[part 3 of 5: package /Cluster]
AUTOSAR XML (schema 4-3-0)
package /Cluster  (continued)
  can cluster HCP5_CANFD01: baudrate=500000, protocol-name=CAN, protocol-version=2.0, bus-off-recovery={bor-counter-l-1-to-l-2=1, bor-time-l-1=0.05, bor-time-l-2=0.2}, can-fd-baudrate=2000000  (continued)
    can physical channel CHNL: comm-connectors=CN_HCP5_CANFD01  (continued)
      frame NM_Gateway_XIX_HCP5_CANFD01: id 0x1B000010, to BMC_HV, frame-length=24, can-addressing-mode=EXTENDED, can-frame-rx-behavior=CAN-FD, can-frame-tx-behavior=CAN-FD, rx-identifier-range={lower-can-id=452984832, upper-can-id=452985855}
        nm pdu NM_Gateway_XIX_HCP5_CANFD01: length=24, unused-bit-pattern=0
          signal NM_Gateway_CBV_AWB_XIX_NM_Gateway_XIX_HCP5_CANFD01: start 4, 1 bit, little-endian, data-type-policy=OVERRIDE, i-signal-type=PRIMITIVE, init-value=0, base-type=BT_NM_Gateway_CBV_AWB, compu-method=CM_NM_Gateway_CBV_AWB, data-constr=DC_NM_Gateway_CBV_AWB, transfer-property=TRIGGERED  # Das Signal ist zu setzen, wenn das SG aktiv den Bus geweckt hat 0 = Passiver_WakeUp = SG hat das Netzwerk nicht aktiv geweckt 1 = Akitiver_WakeUp = SG hat das Netzwerk aktiv geweckt
          signal NM_Gateway_CBV_CRI_XIX_NM_Gateway_XIX_HCP5_CANFD01: start 6, 1 bit, little-endian, data-type-policy=OVERRIDE, i-signal-type=PRIMITIVE, init-value=1, base-type=BT_NM_Gateway_CBV_CRI, compu-method=CM_NM_Gateway_CBV_CRI, data-constr=DC_NM_Gateway_CBV_CRI, transfer-property=TRIGGERED  # Das Signal ist dauerhaft gesetzt, wenn das NM-Layout Cluster- Anforderungen enthält
          signal NM_Gateway_FCAB_XIX_NM_Gateway_XIX_HCP5_CANFD01: start 8, 56 bit, opaque, data-type-policy=OVERRIDE, i-signal-type=ARRAY, init-value=7 x 0b00000000, base-type=BT_NM_Gateway_FCAB, compu-method=CM_NM_Gateway_FCAB, data-constr=DC_NM_Gateway_FCAB, transfer-property=TRIGGERED-ON-CHANGE, to BMC_HV(timeout 2 s)  # FCAB = Funktions-Cluster-Aktiv-Bits
          signal NM_aktiv_ConnectVerbund_UseCase1_XIX_NM_Gateway_XIX_HCP5_CANFD01: start 114, 1 bit, little-endian, data-type-policy=OVERRIDE, i-signal-type=PRIMITIVE, init-value=0, base-type=BT_NM_aktiv_ConnectVerbund_UseCase1, compu-method=CM_NM_aktiv_ConnectVerbund_UseCase1, data-constr=DC_NM_aktiv_ConnectVerbund_UseCase1, transfer-property=TRIGGERED  # Die Connect Steuergeräte HCP3, HCP5 und ConMod sind über einen zusätzlichen Wecknachlauf, inkl. Bus Kommunikation und Backend Verbindung aufgeweckt. Der Kunde hat davor die Funktion "Verlängerte Wachphase An" in der HCP3 Goodbye Screen bestätigt. Die Funktion hat Dauer und Max Werte Analog VoKo oder Prädektives VoKo Funktionalität und darf nur aktiv bleiben solange VoKo an ist (NM_aktiv_Scheibenheizung). Um diese Funktionalität zu ermöglichen sind bestehenden Funktionscluster zu steuern
          signal NM_aktiv_ConnectVerbund_UseCase2_XIX_NM_Gateway_XIX_HCP5_CANFD01: start 115, 1 bit, little-endian, data-type-policy=OVERRIDE, i-signal-type=PRIMITIVE, init-value=0, base-type=BT_NM_aktiv_ConnectVerbund_UseCase2, compu-method=CM_NM_aktiv_ConnectVerbund_UseCase2, data-constr=DC_NM_aktiv_ConnectVerbund_UseCase2, transfer-property=TRIGGERED  # Die Connect Steuergeräte HCP3, HCP5 und ConMod bleiben über einen zusätzlichen Wecknachlauf wach, inkl. Bus Kommunikation und Backend Verbindung wenn der Kunde die Funktion "Verlängerte Wachphase An" in der HU Goodbye Screen die Funktion bestätigt. Um diese Funktionalität zu ermöglichen sind bestehenden Funktionscluster zu steuern Die HVEM soll zwischen 5-10 Minuten nachlaufen damit die Connect Verbund die NVEM Batterie optimal ausnutzt
          signal NM_aktiv_ConnectVerbund_UseCase3_XIX_NM_Gateway_XIX_HCP5_CANFD01: start 116, 1 bit, little-endian, data-type-policy=OVERRIDE, i-signal-type=PRIMITIVE, init-value=0, base-type=BT_NM_aktiv_ConnectVerbund_UseCase3, compu-method=CM_NM_aktiv_ConnectVerbund_UseCase3, data-constr=DC_NM_aktiv_ConnectVerbund_UseCase3, transfer-property=TRIGGERED  # Die ORU Steuergeräte sind länger wach inkl. Bus Kommunikation und Backend Verbindung wenn der Kunde die Funktion in der HU Goodbye Screen die Funktion "Verlängerte Wachphase An" bestätigt hat. Flash Umfänge bei denen den HV-System aus sein muss, darf nicht länger als 30 Minuten ORU Flashzeit. Andere Umfänge dürfen längere ORU Flashzeit (bis 180 Minuten) anfodern. NM_aktivgrund verfügbar NM_aktiv_OnlineRemoteUpdate
          signal NM_aktiv_ConnectVerbund_UseCase4_XIX_NM_Gateway_XIX_HCP5_CANFD01: start 117, 1 bit, little-endian, data-type-policy=OVERRIDE, i-signal-type=PRIMITIVE, init-value=0, base-type=BT_NM_aktiv_ConnectVerbund_UseCase4, compu-method=CM_NM_aktiv_ConnectVerbund_UseCase4, data-constr=DC_NM_aktiv_ConnectVerbund_UseCase4, transfer-property=TRIGGERED  # Die Connect Steuergeräte HCP3, HCP5, HCP4 und ConMod werden geweckt und bleiben wach, inkl. Bus Kommunikation und Backend Verbindung wenn der Kunde die Funktion "Verlängerte Wachphase An" in der Head Unit Goodbye Screen bestätigt hat während das Fahrzeug am DC Ladesäule geladen wird. Um diese Funktionalität zu ermöglichen sind bestehenden Funktionscluster zu steuern
          signal NM_aktiv_ConnectVerbund_UseCase5_XIX_NM_Gateway_XIX_HCP5_CANFD01: start 118, 1 bit, little-endian, data-type-policy=OVERRIDE, i-signal-type=PRIMITIVE, init-value=0, base-type=BT_NM_aktiv_ConnectVerbund_UseCase5, compu-method=CM_NM_aktiv_ConnectVerbund_UseCase5, data-constr=DC_NM_aktiv_ConnectVerbund_UseCase5, transfer-property=TRIGGERED  # Die Connect Steuergeräte HCP3, HCP5 und ConMod sind über einen zusätzlichen Wecknachlauf, inkl. Bus Kommunikation und Backend Verbindung aufgeweckt. Der Kunde hat davor die Funktion "Verlängerte Wachphase An" in der HCP3 Goodbye Screen bestätigt. Um diese Funktionalität zu ermöglichen sind bestehenden Funktionscluster zu steuern
          signal NM_aktiv_ConnectVerbund_UseCase6_XIX_NM_Gateway_XIX_HCP5_CANFD01: start 119, 1 bit, little-endian, data-type-policy=OVERRIDE, i-signal-type=PRIMITIVE, init-value=0, base-type=BT_NM_aktiv_ConnectVerbund_UseCase6, compu-method=CM_NM_aktiv_ConnectVerbund_UseCase6, data-constr=DC_NM_aktiv_ConnectVerbund_UseCase6, transfer-property=TRIGGERED  # Die Connect Steuergeräte HCP3, HCP5 und ConMod sind über einen zusätzlichen Wecknachlauf, inkl. Bus Kommunikation und Backend Verbindung aufgeweckt während das Fahrzeug am AC Ladesäule geladen wird. Trigger ist eine Anfrage über die App/Backend ins Auto. Der Kunde hat davor die Funktion "Verlängerte Wachphase An" in der HCP3 Goodbye Screen bestätigt. Um diese Funktionalität zu ermöglichen sind bestehenden Funktionscluster zu steuern
          signal NM_aktiv_AutomotiveEdge_1_XIX_NM_Gateway_XIX_HCP5_CANFD01: start 120, 1 bit, little-endian, data-type-policy=OVERRIDE, i-signal-type=PRIMITIVE, init-value=0, base-type=BT_NM_aktiv_AutomotiveEdge_1, compu-method=CM_NM_aktiv_AutomotiveEdge_1, data-constr=DC_NM_aktiv_AutomotiveEdge_1, transfer-property=TRIGGERED  # Vorhalt VNSM_UsrId und NM-Aktivgrund-Signal für künftig möglichen Funktionshub ohne erforderlichen K-Matrix Update
          signal NM_aktiv_AutomotiveEdge_2_XIX_NM_Gateway_XIX_HCP5_CANFD01: start 121, 1 bit, little-endian, data-type-policy=OVERRIDE, i-signal-type=PRIMITIVE, init-value=0, base-type=BT_NM_aktiv_AutomotiveEdge_2, compu-method=CM_NM_aktiv_AutomotiveEdge_2, data-constr=DC_NM_aktiv_AutomotiveEdge_2, transfer-property=TRIGGERED  # Vorhalt VNSM_UsrId und NM-Aktivgrund-Signal für künftig möglichen Funktionshub ohne erforderlichen K-Matrix Update
          signal NM_aktiv_AutomotiveEdge_3_XIX_NM_Gateway_XIX_HCP5_CANFD01: start 122, 1 bit, little-endian, data-type-policy=OVERRIDE, i-signal-type=PRIMITIVE, init-value=0, base-type=BT_NM_aktiv_AutomotiveEdge_3, compu-method=CM_NM_aktiv_AutomotiveEdge_3, data-constr=DC_NM_aktiv_AutomotiveEdge_3, transfer-property=TRIGGERED  # Vorhalt VNSM_UsrId und NM-Aktivgrund-Signal für künftig möglichen Funktionshub ohne erforderlichen K-Matrix Update
          signal NM_aktiv_AutomotiveEdge_4_XIX_NM_Gateway_XIX_HCP5_CANFD01: start 123, 1 bit, little-endian, data-type-policy=OVERRIDE, i-signal-type=PRIMITIVE, init-value=0, base-type=BT_NM_aktiv_AutomotiveEdge_4, compu-method=CM_NM_aktiv_AutomotiveEdge_4, data-constr=DC_NM_aktiv_AutomotiveEdge_4, transfer-property=TRIGGERED  # Vorhalt VNSM_UsrId und NM-Aktivgrund-Signal für künftig möglichen Funktionshub ohne erforderlichen K-Matrix Update
          signal NM_aktiv_AutomotiveEdge_5_XIX_NM_Gateway_XIX_HCP5_CANFD01: start 124, 1 bit, little-endian, data-type-policy=OVERRIDE, i-signal-type=PRIMITIVE, init-value=0, base-type=BT_NM_aktiv_AutomotiveEdge_5, compu-method=CM_NM_aktiv_AutomotiveEdge_5, data-constr=DC_NM_aktiv_AutomotiveEdge_5, transfer-property=TRIGGERED  # Vorhalt VNSM_UsrId und NM-Aktivgrund-Signal für künftig möglichen Funktionshub ohne erforderlichen K-Matrix Update
          signal NM_aktiv_MVEM_Fremdladung_XIX_NM_Gateway_XIX_HCP5_CANFD01: start 125, 1 bit, little-endian, data-type-policy=OVERRIDE, i-signal-type=PRIMITIVE, init-value=0, base-type=BT_NM_aktiv_MVEM_Fremdladung, compu-method=CM_NM_aktiv_MVEM_Fremdladung, data-constr=DC_NM_aktiv_MVEM_Fremdladung, transfer-property=TRIGGERED  # Nach Ausschalten der Kl.15 soll bei 12V-Fremdladungsfreigabe durch das NvEM das MV-Netz noch aktiv gehalten werden oder bei ausgeschalteter Kl.15 aktiviert werden, dazu muss der HCP5 wach sein, der DcDc-Wandler und das BMS mit den jeweiligen Bussen. - 12V-Fremdladung (Fremdladegerät an der 12V-Batterie), damit die 48V-Batterie über den DcDc-Wandler noch geladen werden kann => wachhalten/aufwecken
          signal NM_aktiv_Konditionierung_Track_XIX_NM_Gateway_XIX_HCP5_CANFD01: start 126, 1 bit, little-endian, data-type-policy=OVERRIDE, i-signal-type=PRIMITIVE, init-value=0, base-type=BT_NM_aktiv_Konditionierung_Track, compu-method=CM_NM_aktiv_Konditionierung_Track, data-constr=DC_NM_aktiv_Konditionierung_Track, transfer-property=TRIGGERED  # Ist die Teilfunktion "Vorkonditionierung" der Funktion Make Me Track Ready (MMTR) aktiv und das Fahrzeug wird dann abgestellt (HVEM_MMTR_State = 2 ||3 UND DANN KL15 Ein -> KL15 Aus), soll der Konditioniervorgang für eine applizierbare Maximalzeit weiter laufen und die betroffenen Steuergeräte wach gehalten werden. Der Kunde kann die Option mittels Display-Anzeige (HCP3) aktivieren. Anschließend wird der Konditionierungsstatus im Display angezeigt.
          signal NM_aktiv_Remote_Repair_XIX_NM_Gateway_XIX_HCP5_CANFD01: start 127, 1 bit, little-endian, data-type-policy=OVERRIDE, i-signal-type=PRIMITIVE, init-value=0, base-type=BT_NM_aktiv_Remote_Repair, compu-method=CM_NM_aktiv_Remote_Repair, data-constr=DC_NM_aktiv_Remote_Repair, transfer-property=TRIGGERED  # Wird aus den Aftersalessystemen (VW/Audi, Porsche) eine Remote Repair Verbindung zum Fahrzeug aufgebaut, so soll das HCP5 und zur Durchführung von Fehlerbehebungsmaßnahmen das gesamte Fahrzeug aufgeweckt bzw. Wachgehalten werden können. Die Verbindung aus den Aftersalessystemen soll hauptsächlich bei Liegenbleibern zur Anwendung kommen. Des Weiteren wenn die Fahrzeuge auf dem Werkstattgelände stehen, um ohne externen Tester DTCs auslesen zu können.
          signal NM_Gateway_SNI_10_XIX_NM_Gateway_XIX_HCP5_CANFD01: start 128, 10 bit, little-endian, data-type-policy=OVERRIDE, i-signal-type=PRIMITIVE, init-value=16, base-type=BT_NM_Gateway_SNI_10, compu-method=CM_NM_Gateway_SNI_10, data-constr=DC_NM_Gateway_SNI_10, transfer-property=TRIGGERED  # Source Node-Identifier (SNI) identifiziert den Sender der NM-Botschaft (Knotenadresse) eindeutig im Fahrzeug
          signal NM_Gateway_NM_State_XIX_NM_Gateway_XIX_HCP5_CANFD01: start 144, 6 bit, little-endian, data-type-policy=OVERRIDE, i-signal-type=PRIMITIVE, init-value=0, base-type=BT_NM_Gateway_NM_State, compu-method=CM_NM_Gateway_NM_State, data-constr=DC_NM_Gateway_NM_State, transfer-property=TRIGGERED  # 1 = Zustand Repeat Message (<-- Bus-Sleep Mode) 2 = Zustand Repeat Message (<-- Prepare Bus-Sleep Mode) 4 = Zustand Normal Operation (<-- Repeat Message) 8 = Zustand Normal Operation (<-- Ready Sleep)
          signal NM_Gateway_UDS_CC_XIX_NM_Gateway_XIX_HCP5_CANFD01: start 151, 1 bit, little-endian, data-type-policy=OVERRIDE, i-signal-type=PRIMITIVE, init-value=0, base-type=BT_NM_Gateway_UDS_CC, compu-method=CM_NM_Gateway_UDS_CC, data-constr=DC_NM_Gateway_UDS_CC, transfer-property=TRIGGERED  # Funktionseinschränkung aufgrund aktivem UDS-Communication Control, siehe VW80124
          signal NM_Gateway_Wakeup_V12_XIX_NM_Gateway_XIX_HCP5_CANFD01: start 152, 8 bit, little-endian, data-type-policy=OVERRIDE, i-signal-type=PRIMITIVE, init-value=0, base-type=BT_NM_Gateway_Wakeup_V12, compu-method=CM_NM_Gateway_Wakeup_V12, data-constr=DC_NM_Gateway_Wakeup_V12, transfer-property=TRIGGERED  # enthält die Weckursache; stehen mehrere Weckursachen parallel an, dann muss der kleinste Wert übertragen werden
          signal NM_Gateway_NM_aktiv_KL15_XIX_NM_Gateway_XIX_HCP5_CANFD01: start 160, 1 bit, little-endian, data-type-policy=OVERRIDE, i-signal-type=PRIMITIVE, init-value=0, base-type=BT_NM_Gateway_NM_aktiv_KL15, compu-method=CM_NM_Gateway_NM_aktiv_KL15, data-constr=DC_NM_Gateway_NM_aktiv_KL15, transfer-property=TRIGGERED  # Steuergerät hat KL15-EIN erkannt
          signal NM_Gateway_NM_aktiv_Diag_XIX_NM_Gateway_XIX_HCP5_CANFD01: start 161, 1 bit, little-endian, data-type-policy=OVERRIDE, i-signal-type=PRIMITIVE, init-value=0, base-type=BT_NM_Gateway_NM_aktiv_Diag, compu-method=CM_NM_Gateway_NM_aktiv_Diag, data-constr=DC_NM_Gateway_NM_aktiv_Diag, transfer-property=TRIGGERED  # Diagnose befindet sich nach VW80124 in einer NonDefaultDiagnostic-Session, z.B. ExtendedDiagnostic-Session
          signal NM_Gateway_NM_aktiv_Tmin_XIX_NM_Gateway_XIX_HCP5_CANFD01: start 162, 1 bit, little-endian, data-type-policy=OVERRIDE, i-signal-type=PRIMITIVE, init-value=0, base-type=BT_NM_Gateway_NM_aktiv_Tmin, compu-method=CM_NM_Gateway_NM_aktiv_Tmin, data-constr=DC_NM_Gateway_NM_aktiv_Tmin, transfer-property=TRIGGERED  # Mindestaktivzeit ist noch nicht abgelaufen (bei jedem Weckereignis wird die Mindestaktivzeit neu gestartet)
          signal NM_Gateway_NM_aktiv_CABaktiv_XIX_NM_Gateway_XIX_HCP5_CANFD01: start 163, 1 bit, little-endian, data-type-policy=OVERRIDE, i-signal-type=PRIMITIVE, init-value=0, base-type=BT_NM_Gateway_NM_aktiv_CABaktiv, compu-method=CM_NM_Gateway_NM_aktiv_CABaktiv, data-constr=DC_NM_Gateway_NM_aktiv_CABaktiv, transfer-property=TRIGGERED  # Nachlauf aufgrund Funktionscluster Anforderung
          signal NM_aktiv_Gefahreninfo_XIX_NM_Gateway_XIX_HCP5_CANFD01: start 164, 1 bit, little-endian, data-type-policy=OVERRIDE, i-signal-type=PRIMITIVE, init-value=0, base-type=BT_NM_aktiv_Gefahreninfo, compu-method=CM_NM_aktiv_Gefahreninfo, data-constr=DC_NM_aktiv_Gefahreninfo, transfer-property=TRIGGERED  # Nach dem Ausschalten der Zündung soll eine Veränderung der Position des FZGs, bzw. eine Bewegung des FZGs erkannt werden und ein zuvor detektiertes Pannen oder Unfall Event gecanncelt werden. Das versenden des Cancel-Events ans Backend muss noch sichergestellt sein. Allerdings tritt der Fall nur auf, wenn davor ein Unfall oder eine Panne detektiert wurde, also sehr selten.
          signal NM_aktiv_MVEM_Pos_RSG_XIX_NM_Gateway_XIX_HCP5_CANFD01: start 165, 1 bit, little-endian, data-type-policy=OVERRIDE, i-signal-type=PRIMITIVE, init-value=0, base-type=BT_NM_aktiv_MVEM_Pos_RSG, compu-method=CM_NM_aktiv_MVEM_Pos_RSG, data-constr=DC_NM_aktiv_MVEM_Pos_RSG, transfer-property=TRIGGERED  # Nach Ausschalten der Kl.15 soll der HCP5 noch für eine gewisse Zeit wachgehalten werden für Stalling Help/Positionierung vom RSG .
          signal NM_aktiv_Timer_abgelaufen_XIX_NM_Gateway_XIX_HCP5_CANFD01: start 166, 1 bit, little-endian, data-type-policy=OVERRIDE, i-signal-type=PRIMITIVE, init-value=0, base-type=BT_NM_aktiv_Timer_abgelaufen, compu-method=CM_NM_aktiv_Timer_abgelaufen, data-constr=DC_NM_aktiv_Timer_abgelaufen, transfer-property=TRIGGERED  # Timer des Basisdienst Zeitmaster::Timemaster_OBD hat ausgelöst
          signal NM_aktiv_Batteriekonditionierung_XIX_NM_Gateway_XIX_HCP5_CANFD01: start 167, 1 bit, little-endian, data-type-policy=OVERRIDE, i-signal-type=PRIMITIVE, init-value=0, base-type=BT_NM_aktiv_Batteriekonditionierung, compu-method=CM_NM_aktiv_Batteriekonditionierung, data-constr=DC_NM_aktiv_Batteriekonditionierung, transfer-property=TRIGGERED  # Zur Reduzierung der Ladezeit, Steigerung der Abfahrtsperfomance und Erhöhung der Reichweite durch Nutzung der HV-Batterie als Wärmequelle muss die HV-Batterie in einen Temperaturbereich konditioniert werden. Das prädiktive Thermomanagement ermittelt mittels Ladeplanung bzw. Abfahrtimer die notwendige Konditionierungsdauer und stellt in der Timerverwaltung einen Weckevorgang ein.
          signal NM_aktiv_HV_Laden_XIX_NM_Gateway_XIX_HCP5_CANFD01: start 168, 1 bit, little-endian, data-type-policy=OVERRIDE, i-signal-type=PRIMITIVE, init-value=0, base-type=BT_NM_aktiv_HV_Laden, compu-method=CM_NM_aktiv_HV_Laden, data-constr=DC_NM_aktiv_HV_Laden, transfer-property=TRIGGERED  # CMS-SWC fordert AC/DC-Laden
          signal NM_aktiv_Backend_KomGW_XIX_NM_Gateway_XIX_HCP5_CANFD01: start 169, 1 bit, little-endian, data-type-policy=OVERRIDE, i-signal-type=PRIMITIVE, init-value=0, base-type=BT_NM_aktiv_Backend_KomGW, compu-method=CM_NM_aktiv_Backend_KomGW, data-constr=DC_NM_aktiv_Backend_KomGW, transfer-property=TRIGGERED  # Der Nachlauf wird benötigt um eine Online Kommunikation zwischen dem Fahrzeug und dem Backend zu ermöglichen.
          signal NM_aktiv_Erw_HV_Ladefunktion_XIX_NM_Gateway_XIX_HCP5_CANFD01: start 170, 1 bit, little-endian, data-type-policy=OVERRIDE, i-signal-type=PRIMITIVE, init-value=0, base-type=BT_NM_aktiv_Erw_HV_Ladefunktion, compu-method=CM_NM_aktiv_Erw_HV_Ladefunktion, data-constr=DC_NM_aktiv_Erw_HV_Ladefunktion, transfer-property=TRIGGERED  # Anhand von Eingaben durch den Kunden wie z.b. einer Abfahrtszeit oder aufgrund von Preisleistungsinformationen werden Ladepläne berechnet und Zeitversetzt ggf. mit Unterbrechungen geladen.
          signal NM_aktiv_E3_SW_Plattform_1_XIX_NM_Gateway_XIX_HCP5_CANFD01: start 171, 1 bit, little-endian, data-type-policy=OVERRIDE, i-signal-type=PRIMITIVE, init-value=0, base-type=BT_NM_aktiv_E3_SW_Plattform_1, compu-method=CM_NM_aktiv_E3_SW_Plattform_1, data-constr=DC_NM_aktiv_E3_SW_Plattform_1, transfer-property=TRIGGERED  # Busaktivität wird durch Applikation 1 auf der E3 SW Plattform angefordert
          signal NM_aktiv_E3_SW_Plattform_2_XIX_NM_Gateway_XIX_HCP5_CANFD01: start 172, 1 bit, little-endian, data-type-policy=OVERRIDE, i-signal-type=PRIMITIVE, init-value=0, base-type=BT_NM_aktiv_E3_SW_Plattform_2, compu-method=CM_NM_aktiv_E3_SW_Plattform_2, data-constr=DC_NM_aktiv_E3_SW_Plattform_2, transfer-property=TRIGGERED  # Busaktivität wird durch Applikation 2 auf der E3 SW Plattform angefordert
          signal NM_aktiv_E3_SW_Plattform_3_XIX_NM_Gateway_XIX_HCP5_CANFD01: start 173, 1 bit, little-endian, data-type-policy=OVERRIDE, i-signal-type=PRIMITIVE, init-value=0, base-type=BT_NM_aktiv_E3_SW_Plattform_3, compu-method=CM_NM_aktiv_E3_SW_Plattform_3, data-constr=DC_NM_aktiv_E3_SW_Plattform_3, transfer-property=TRIGGERED  # Busaktivität wird durch Applikation 3 auf der E3 SW Plattform angefordert
          signal NM_aktiv_E3_SW_Plattform_4_XIX_NM_Gateway_XIX_HCP5_CANFD01: start 174, 1 bit, little-endian, data-type-policy=OVERRIDE, i-signal-type=PRIMITIVE, init-value=0, base-type=BT_NM_aktiv_E3_SW_Plattform_4, compu-method=CM_NM_aktiv_E3_SW_Plattform_4, data-constr=DC_NM_aktiv_E3_SW_Plattform_4, transfer-property=TRIGGERED  # Busaktivität wird durch Applikation 4 auf der E3 SW Plattform angefordert
          signal NM_aktiv_E3_SW_Plattform_5_XIX_NM_Gateway_XIX_HCP5_CANFD01: start 175, 1 bit, little-endian, data-type-policy=OVERRIDE, i-signal-type=PRIMITIVE, init-value=0, base-type=BT_NM_aktiv_E3_SW_Plattform_5, compu-method=CM_NM_aktiv_E3_SW_Plattform_5, data-constr=DC_NM_aktiv_E3_SW_Plattform_5, transfer-property=TRIGGERED  # Busaktivität wird durch Applikation 5 auf der E3 SW Plattform angefordert
          signal NM_aktiv_Key_Authentifiz_SMS_XIX_NM_Gateway_XIX_HCP5_CANFD01: start 176, 1 bit, little-endian, data-type-policy=OVERRIDE, i-signal-type=PRIMITIVE, init-value=0, base-type=BT_NM_aktiv_Key_Authentifiz_SMS, compu-method=CM_NM_aktiv_Key_Authentifiz_SMS, data-constr=DC_NM_aktiv_Key_Authentifiz_SMS, transfer-property=TRIGGERED  # Im Rahmen der Funktion MDK 2.0 müssen zu bestimmten Zeitpunkten Daten mit dem Backend ausgetauscht werden, um z.B. digitale Schlüssel im Fahrzeug zu löschen oder Zertifikate und Konfigurationsdaten zu aktualisieren
          signal NM_aktiv_HVK_XIX_NM_Gateway_XIX_HCP5_CANFD01: start 177, 1 bit, little-endian, data-type-policy=OVERRIDE, i-signal-type=PRIMITIVE, init-value=0, base-type=BT_NM_aktiv_HVK, compu-method=CM_NM_aktiv_HVK, data-constr=DC_NM_aktiv_HVK, transfer-property=TRIGGERED  # Der HV-Koordinator stellt den Fahrzeugfunktionen ein aktives HV-System im benötigten Betriebszustand zur Verfügung. Da es insbesondere für HV-Laden und für die Vorkonditionierung HV-Betriebszustände ohne KL15 Ein gibt, muss der Hochvolt-Koordinator benötigte Funktionen und HV-Komponenten aktiv anfordern.
          signal NM_aktiv_HVLM_XIX_NM_Gateway_XIX_HCP5_CANFD01: start 178, 1 bit, little-endian, data-type-policy=OVERRIDE, i-signal-type=PRIMITIVE, init-value=0, base-type=BT_NM_aktiv_HVLM, compu-method=CM_NM_aktiv_HVLM, data-constr=DC_NM_aktiv_HVLM, transfer-property=TRIGGERED  # HV-Lademanager bzw CMS-SWC fordert AC/DC-Laden
          signal NM_aktiv_NVEM_XIX_NM_Gateway_XIX_HCP5_CANFD01: start 179, 1 bit, little-endian, data-type-policy=OVERRIDE, i-signal-type=PRIMITIVE, init-value=0, base-type=BT_NM_aktiv_NVEM, compu-method=CM_NM_aktiv_NVEM, data-constr=DC_NM_aktiv_NVEM, transfer-property=TRIGGERED  # Niedervolt-Energiemanagement startet bei Unterschreitung eines bestimmten Ladungsinhalts der Niedervoltbatteri selbstständig den Nachlade-Prozess.
          signal NM_aktiv_OnlineRemoteUpdate_XIX_NM_Gateway_XIX_HCP5_CANFD01: start 180, 1 bit, little-endian, data-type-policy=OVERRIDE, i-signal-type=PRIMITIVE, init-value=0, base-type=BT_NM_aktiv_OnlineRemoteUpdate, compu-method=CM_NM_aktiv_OnlineRemoteUpdate, data-constr=DC_NM_aktiv_OnlineRemoteUpdate, transfer-property=TRIGGERED  # Im ORU Fall muss nach Kundenzustimmung des Updates geweckt wecken, um Vorbedinungungen für das Update zu prüfen sowie die Verbindung zu den betroffenen Steuergeräten aufzubauen und aufrechtzuerhalten.
          signal NM_aktiv_RemoteDiensteGW_XIX_NM_Gateway_XIX_HCP5_CANFD01: start 181, 1 bit, little-endian, data-type-policy=OVERRIDE, i-signal-type=PRIMITIVE, init-value=0, base-type=BT_NM_aktiv_RemoteDiensteGW, compu-method=CM_NM_aktiv_RemoteDiensteGW, data-constr=DC_NM_aktiv_RemoteDiensteGW, transfer-property=TRIGGERED  # Das Fahrzeug wird bei einem Smart-Phone-App Aufruf über die ConMod für einen Job geweckt. Der empfangene Job wird an das BCM bzw TME gesendet, welche die weiteren Services anbieten.
          signal NM_aktiv_SubbusSteuerung_HCP5_XIX_NM_Gateway_XIX_HCP5_CANFD01: start 182, 1 bit, little-endian, data-type-policy=OVERRIDE, i-signal-type=PRIMITIVE, init-value=0, base-type=BT_NM_aktiv_SubbusSteuerung_HCP5, compu-method=CM_NM_aktiv_SubbusSteuerung_HCP5, data-constr=DC_NM_aktiv_SubbusSteuerung_HCP5, transfer-property=TRIGGERED  # Steuerung des MFL_CAN sowie der Ethernet-Links HCP5_MFK_ETH, HCP5_MRR_ETH und HCP5_xView_ETH
          signal NM_aktiv_VehicleStatReport_Main_XIX_NM_Gateway_XIX_HCP5_CANFD01: start 183, 1 bit, little-endian, data-type-policy=OVERRIDE, i-signal-type=PRIMITIVE, init-value=0, base-type=BT_NM_aktiv_VehicleStatReport_Main, compu-method=CM_NM_aktiv_VehicleStatReport_Main, data-constr=DC_NM_aktiv_VehicleStatReport_Main, transfer-property=TRIGGERED  # Die Funktion zeigt Daten wie Türen und Fensterstatus oder Reichweiten in der App oder dem Portal an.
          signal NM_aktiv_Remote_Unlock_Lock_XIX_NM_Gateway_XIX_HCP5_CANFD01: start 184, 1 bit, little-endian, data-type-policy=OVERRIDE, i-signal-type=PRIMITIVE, init-value=0, base-type=BT_NM_aktiv_Remote_Unlock_Lock, compu-method=CM_NM_aktiv_Remote_Unlock_Lock, data-constr=DC_NM_aktiv_Remote_Unlock_Lock, transfer-property=TRIGGERED  # Über Smartphone App kann Nutzer ferngesteuert die Türen ver- und entriegeln: Fahrzeug wird für einen solchen Job geweckt über Online-Verbindung (conMod > HCP5; abgedeckt durch CoreServices Wakeup 85.3); empfangener Job wird von HCP5 an HCP4 gesendet (dieser Weck-/ Nachlaufgrund); HCP4 führt die Lock/Unlock Funktionalität dann aus, braucht dazu Backend-Kommunikation (HCP5 + ConMod), Türsteuergeräte, Zentralverriegelung und Powertrain (HCP1 + Gearbox) (weiterer Antrag/ Update von 67.2 )
          signal NM_aktiv_HVEM_XIX_NM_Gateway_XIX_HCP5_CANFD01: start 185, 1 bit, little-endian, data-type-policy=OVERRIDE, i-signal-type=PRIMITIVE, init-value=0, base-type=BT_NM_aktiv_HVEM, compu-method=CM_NM_aktiv_HVEM, data-constr=DC_NM_aktiv_HVEM, transfer-property=TRIGGERED  # Das Hochvolt-Energiemanagement (HVEM) ist für die Verteilung von Leistung und Energie in allen Betriebszuständen im HV-System zuständig.
          signal NM_aktiv_Call_XIX_NM_Gateway_XIX_HCP5_CANFD01: start 186, 1 bit, little-endian, data-type-policy=OVERRIDE, i-signal-type=PRIMITIVE, init-value=0, base-type=BT_NM_aktiv_Call, compu-method=CM_NM_aktiv_Call, data-constr=DC_NM_aktiv_Call, transfer-property=TRIGGERED  # Wird ein eCall oder Online Pannenruf durchgeführt und ist der Anruf zum Notruf oder Pannenruf Callcenter bereits aufgebaut, darf beim Ausschalten der KL15 der HCP3, ConMod und HCP5 nicht schlafen gehen
          signal NM_aktiv_RemoteStart_XIX_NM_Gateway_XIX_HCP5_CANFD01: start 187, 1 bit, little-endian, data-type-policy=OVERRIDE, i-signal-type=PRIMITIVE, init-value=0, base-type=BT_NM_aktiv_RemoteStart, compu-method=CM_NM_aktiv_RemoteStart, data-constr=DC_NM_aktiv_RemoteStart, transfer-property=TRIGGERED  # Zur Ausführung des Remote Motorstarts wird über den MOD eine Aktivierung durch den Fahrzeughalter über Smartphone getriggert
          signal NM_aktiv_Ladezustand_XIX_NM_Gateway_XIX_HCP5_CANFD01: start 188, 1 bit, little-endian, data-type-policy=OVERRIDE, i-signal-type=PRIMITIVE, init-value=0, base-type=BT_NM_aktiv_Ladezustand, compu-method=CM_NM_aktiv_Ladezustand, data-constr=DC_NM_aktiv_Ladezustand, transfer-property=TRIGGERED  # Über die App kann der Nutzer ferngesteuert zwischen Sofort und Zeitversetzten Laden wechseln. Weiterhin sendet das Fahrzeug wärend aktivem Ladevorgang zyklisch Updates zum Ladeverlauf.
          signal NM_aktiv_RemoteVehicleTracking_XIX_NM_Gateway_XIX_HCP5_CANFD01: start 189, 1 bit, little-endian, data-type-policy=OVERRIDE, i-signal-type=PRIMITIVE, init-value=0, base-type=BT_NM_aktiv_RemoteVehicleTracking, compu-method=CM_NM_aktiv_RemoteVehicleTracking, data-constr=DC_NM_aktiv_RemoteVehicleTracking, transfer-property=TRIGGERED  # Der RVT ist ein Diebstahlschutz, der remote das gestohlene Fahrzeug von einem Callcenter tracken kann. Dazu muss der Bus aufgeweckt werden.
          signal NM_aktiv_WarnblinkerInfo_XIX_NM_Gateway_XIX_HCP5_CANFD01: start 190, 1 bit, little-endian, data-type-policy=OVERRIDE, i-signal-type=PRIMITIVE, init-value=0, base-type=BT_NM_aktiv_WarnblinkerInfo, compu-method=CM_NM_aktiv_WarnblinkerInfo, data-constr=DC_NM_aktiv_WarnblinkerInfo, transfer-property=TRIGGERED  # - Der chinesische LTE-V2X Standard erfordert BSM Nachrichten. Das "Vehicle event flag" ist ein verpflichtender Teil dieser BSM Nachricht. Da die ConMod das nicht befüllen kann, soll diese SWC "LHWSenderChinaVehicleEventFlags" die Berechnung dieser Vehicle Event Flags übernehmen. Die Zusammensetzung und das Aussenden der vollständigen BSM-Nachrichten erfolgt nachgehend in der ConMod. - Eines dieser Vehicle Event Flags beschreibt das Verhalten bei aktiviertem Warnblinker. Ist der Warnblinker aktiviert sollen BSMs mit entsprechenden event flags auch bei inaktiver Klemme15 versendet werden. Hierfür ist ein Wecken der ConMod notwendig.
          signal NM_aktiv_NVEM2_XIX_NM_Gateway_XIX_HCP5_CANFD01: start 191, 1 bit, little-endian, data-type-policy=OVERRIDE, i-signal-type=PRIMITIVE, init-value=0, base-type=BT_NM_aktiv_NVEM2, compu-method=CM_NM_aktiv_NVEM2, data-constr=DC_NM_aktiv_NVEM2, transfer-property=TRIGGERED  # Niedervoltenergiemanagement 2 zur Sicherstellung der Versorgung sicherheitsrelevanter Verbraucher.
      frame NM_HVZB_XIX_HCP5_CANFD01: id 0x1B00011D, to BMC_HV, frame-length=24, can-addressing-mode=EXTENDED, can-frame-rx-behavior=CAN-FD, can-frame-tx-behavior=CAN-FD, rx-identifier-range={lower-can-id=452984832, upper-can-id=452985855}
        nm pdu NM_HVZB_XIX_HCP5_CANFD01: length=24, unused-bit-pattern=0
          signal NM_HVZB_CBV_AWB_XIX_NM_HVZB_XIX_HCP5_CANFD01: start 4, 1 bit, little-endian, data-type-policy=OVERRIDE, i-signal-type=PRIMITIVE, init-value=0, base-type=BT_NM_HVZB_CBV_AWB, compu-method=CM_NM_HVZB_CBV_AWB, data-constr=DC_NM_HVZB_CBV_AWB, transfer-property=TRIGGERED  # Das Signal ist zu setzen, wenn das SG aktiv den Bus geweckt hat 0 = Passiver_WakeUp = SG hat das Netzwerk nicht aktiv geweckt 1 = Akitiver_WakeUp = SG hat das Netzwerk aktiv geweckt
          signal NM_HVZB_CBV_CRI_XIX_NM_HVZB_XIX_HCP5_CANFD01: start 6, 1 bit, little-endian, data-type-policy=OVERRIDE, i-signal-type=PRIMITIVE, init-value=1, base-type=BT_NM_HVZB_CBV_CRI, compu-method=CM_NM_HVZB_CBV_CRI, data-constr=DC_NM_HVZB_CBV_CRI, transfer-property=TRIGGERED  # Das Signal ist dauerhaft gesetzt, wenn das NM-Layout Cluster- Anforderungen enthält
          signal NM_HVZB_FCAB_XIX_NM_HVZB_XIX_HCP5_CANFD01: start 8, 56 bit, opaque, data-type-policy=OVERRIDE, i-signal-type=ARRAY, init-value=7 x 0b00000000, base-type=BT_NM_HVZB_FCAB, compu-method=CM_NM_HVZB_FCAB, data-constr=DC_NM_HVZB_FCAB, transfer-property=TRIGGERED-ON-CHANGE, to BMC_HV(timeout 2 s)  # FCAB = Funktions-Cluster-Aktiv-Bits
          signal NM_HVZB_SNI_10_XIX_NM_HVZB_XIX_HCP5_CANFD01: start 128, 10 bit, little-endian, data-type-policy=OVERRIDE, i-signal-type=PRIMITIVE, init-value=285, base-type=BT_NM_HVZB_SNI_10, compu-method=CM_NM_HVZB_SNI_10, data-constr=DC_NM_HVZB_SNI_10, transfer-property=TRIGGERED  # Source Node-Identifier (SNI) identifiziert den Sender der NM-Botschaft (Knotenadresse) eindeutig im Fahrzeug
          signal NM_HVZB_NM_State_XIX_NM_HVZB_XIX_HCP5_CANFD01: start 144, 6 bit, little-endian, data-type-policy=OVERRIDE, i-signal-type=PRIMITIVE, init-value=0, base-type=BT_NM_HVZB_NM_State, compu-method=CM_NM_HVZB_NM_State, data-constr=DC_NM_HVZB_NM_State, transfer-property=TRIGGERED  # 1 = Zustand Repeat Message (<-- Bus-Sleep Mode) 2 = Zustand Repeat Message (<-- Prepare Bus-Sleep Mode) 4 = Zustand Normal Operation (<-- Repeat Message) 8 = Zustand Normal Operation (<-- Ready Sleep)
          signal NM_HVZB_UDS_CC_XIX_NM_HVZB_XIX_HCP5_CANFD01: start 151, 1 bit, little-endian, data-type-policy=OVERRIDE, i-signal-type=PRIMITIVE, init-value=0, base-type=BT_NM_HVZB_UDS_CC, compu-method=CM_NM_HVZB_UDS_CC, data-constr=DC_NM_HVZB_UDS_CC, transfer-property=TRIGGERED  # Funktionseinschränkung aufgrund aktivem UDS-Communication Control, siehe VW80124
          signal NM_HVZB_Wakeup_V12_XIX_NM_HVZB_XIX_HCP5_CANFD01: start 152, 8 bit, little-endian, data-type-policy=OVERRIDE, i-signal-type=PRIMITIVE, init-value=0, base-type=BT_NM_HVZB_Wakeup_V12, compu-method=CM_NM_HVZB_Wakeup_V12, data-constr=DC_NM_HVZB_Wakeup_V12, transfer-property=TRIGGERED  # enthält die Weckursache; stehen mehrere Weckursachen parallel an, dann muss der kleinste Wert übertragen werden
          signal NM_HVZB_NM_aktiv_KL15_XIX_NM_HVZB_XIX_HCP5_CANFD01: start 160, 1 bit, little-endian, data-type-policy=OVERRIDE, i-signal-type=PRIMITIVE, init-value=0, base-type=BT_NM_HVZB_NM_aktiv_KL15, compu-method=CM_NM_HVZB_NM_aktiv_KL15, data-constr=DC_NM_HVZB_NM_aktiv_KL15, transfer-property=TRIGGERED  # Steuergerät hat KL15-EIN erkannt
          signal NM_HVZB_NM_aktiv_Diag_XIX_NM_HVZB_XIX_HCP5_CANFD01: start 161, 1 bit, little-endian, data-type-policy=OVERRIDE, i-signal-type=PRIMITIVE, init-value=0, base-type=BT_NM_HVZB_NM_aktiv_Diag, compu-method=CM_NM_HVZB_NM_aktiv_Diag, data-constr=DC_NM_HVZB_NM_aktiv_Diag, transfer-property=TRIGGERED  # Diagnose befindet sich nach VW80124 in einer NonDefaultDiagnostic-Session, z.B. ExtendedDiagnostic-Session
          signal NM_HVZB_NM_aktiv_Tmin_XIX_NM_HVZB_XIX_HCP5_CANFD01: start 162, 1 bit, little-endian, data-type-policy=OVERRIDE, i-signal-type=PRIMITIVE, init-value=0, base-type=BT_NM_HVZB_NM_aktiv_Tmin, compu-method=CM_NM_HVZB_NM_aktiv_Tmin, data-constr=DC_NM_HVZB_NM_aktiv_Tmin, transfer-property=TRIGGERED  # Mindestaktivzeit ist noch nicht abgelaufen (bei jedem Weckereignis wird die Mindestaktivzeit neu gestartet)
      frame NM_Hybrid_01_XIX_HCP5_CANFD01: id 0x1B00007B, from BMC_HV, frame-length=24, can-addressing-mode=EXTENDED, can-frame-rx-behavior=CAN-FD, can-frame-tx-behavior=CAN-FD, rx-identifier-range={lower-can-id=452984832, upper-can-id=452985855}
        nm pdu NM_Hybrid_01_XIX_HCP5_CANFD01: length=24, unused-bit-pattern=0
          signal NM_Hybrid_01_CBV_AWB_XIX_NM_Hybrid_01_XIX_HCP5_CANFD01: start 4, 1 bit, little-endian, data-type-policy=OVERRIDE, i-signal-type=PRIMITIVE, init-value=0, base-type=BT_NM_Hybrid_01_CBV_AWB, compu-method=CM_NM_Hybrid_01_CBV_AWB, data-constr=DC_NM_Hybrid_01_CBV_AWB, transfer-property=TRIGGERED  # Das Signal ist zu setzen, wenn das SG aktiv den Bus geweckt hat 0 = Passiver_WakeUp = SG hat das Netzwerk nicht aktiv geweckt 1 = Akitiver_WakeUp = SG hat das Netzwerk aktiv geweckt
          signal NM_Hybrid_01_CBV_CRI_XIX_NM_Hybrid_01_XIX_HCP5_CANFD01: start 6, 1 bit, little-endian, data-type-policy=OVERRIDE, i-signal-type=PRIMITIVE, init-value=1, base-type=BT_NM_Hybrid_01_CBV_CRI, compu-method=CM_NM_Hybrid_01_CBV_CRI, data-constr=DC_NM_Hybrid_01_CBV_CRI, transfer-property=TRIGGERED  # Das Signal ist dauerhaft gesetzt, wenn das NM-Layout Cluster- Anforderungen enthält
          signal NM_Hybrid_01_FCAB_XIX_NM_Hybrid_01_XIX_HCP5_CANFD01: start 8, 56 bit, opaque, data-type-policy=OVERRIDE, i-signal-type=ARRAY, init-value=7 x 0b00000000, base-type=BT_NM_Hybrid_01_FCAB, compu-method=CM_NM_Hybrid_01_FCAB, data-constr=DC_NM_Hybrid_01_FCAB, transfer-property=TRIGGERED-ON-CHANGE  # FCAB = Funktions-Cluster-Aktiv-Bits
          signal NM_Hybrid_01_SNI_10_XIX_NM_Hybrid_01_XIX_HCP5_CANFD01: start 128, 10 bit, little-endian, data-type-policy=OVERRIDE, i-signal-type=PRIMITIVE, init-value=123, base-type=BT_NM_Hybrid_01_SNI_10, compu-method=CM_NM_Hybrid_01_SNI_10, data-constr=DC_NM_Hybrid_01_SNI_10, transfer-property=TRIGGERED  # Source Node-Identifier (SNI) identifiziert den Sender der NM-Botschaft (Knotenadresse) eindeutig im Fahrzeug
          signal NM_Hybrid_01_NM_State_XIX_NM_Hybrid_01_XIX_HCP5_CANFD01: start 144, 6 bit, little-endian, data-type-policy=OVERRIDE, i-signal-type=PRIMITIVE, init-value=0, base-type=BT_NM_Hybrid_01_NM_State, compu-method=CM_NM_Hybrid_01_NM_State, data-constr=DC_NM_Hybrid_01_NM_State, transfer-property=TRIGGERED  # 1 = Zustand Repeat Message (<-- Bus-Sleep Mode) 2 = Zustand Repeat Message (<-- Prepare Bus-Sleep Mode) 4 = Zustand Normal Operation (<-- Repeat Message) 8 = Zustand Normal Operation (<-- Ready Sleep)
          signal NM_Hybrid_01_UDS_CC_XIX_NM_Hybrid_01_XIX_HCP5_CANFD01: start 151, 1 bit, little-endian, data-type-policy=OVERRIDE, i-signal-type=PRIMITIVE, init-value=0, base-type=BT_NM_Hybrid_01_UDS_CC, compu-method=CM_NM_Hybrid_01_UDS_CC, data-constr=DC_NM_Hybrid_01_UDS_CC, transfer-property=TRIGGERED  # Funktionseinschränkung aufgrund aktivem UDS-Communication Control, siehe VW80124
          signal NM_Hybrid_01_Wakeup_V12_XIX_NM_Hybrid_01_XIX_HCP5_CANFD01: start 152, 8 bit, little-endian, data-type-policy=OVERRIDE, i-signal-type=PRIMITIVE, init-value=0, base-type=BT_NM_Hybrid_01_Wakeup_V12, compu-method=CM_NM_Hybrid_01_Wakeup_V12, data-constr=DC_NM_Hybrid_01_Wakeup_V12, transfer-property=TRIGGERED  # enthält die Weckursache; stehen mehrere Weckursachen parallel an, dann muss der kleinste Wert übertragen werden
          signal NM_Hybrid_01_NM_aktiv_KL15_XIX_NM_Hybrid_01_XIX_HCP5_CANFD01: start 160, 1 bit, little-endian, data-type-policy=OVERRIDE, i-signal-type=PRIMITIVE, init-value=0, base-type=BT_NM_Hybrid_01_NM_aktiv_KL15, compu-method=CM_NM_Hybrid_01_NM_aktiv_KL15, data-constr=DC_NM_Hybrid_01_NM_aktiv_KL15, transfer-property=TRIGGERED  # Steuergerät hat KL15-EIN erkannt
          signal NM_Hybrid_01_NM_aktiv_Diag_XIX_NM_Hybrid_01_XIX_HCP5_CANFD01: start 161, 1 bit, little-endian, data-type-policy=OVERRIDE, i-signal-type=PRIMITIVE, init-value=0, base-type=BT_NM_Hybrid_01_NM_aktiv_Diag, compu-method=CM_NM_Hybrid_01_NM_aktiv_Diag, data-constr=DC_NM_Hybrid_01_NM_aktiv_Diag, transfer-property=TRIGGERED  # Diagnose befindet sich nach VW80124 in einer NonDefaultDiagnostic-Session, z.B. ExtendedDiagnostic-Session
          signal NM_Hybrid_01_NM_aktiv_Tmin_XIX_NM_Hybrid_01_XIX_HCP5_CANFD01: start 162, 1 bit, little-endian, data-type-policy=OVERRIDE, i-signal-type=PRIMITIVE, init-value=0, base-type=BT_NM_Hybrid_01_NM_aktiv_Tmin, compu-method=CM_NM_Hybrid_01_NM_aktiv_Tmin, data-constr=DC_NM_Hybrid_01_NM_aktiv_Tmin, transfer-property=TRIGGERED  # Mindestaktivzeit ist noch nicht abgelaufen (bei jedem Weckereignis wird die Mindestaktivzeit neu gestartet)
          signal NM_aktiv_Konditionierungsbedarf_XIX_NM_Hybrid_01_XIX_HCP5_CANFD01: start 163, 1 bit, little-endian, data-type-policy=OVERRIDE, i-signal-type=PRIMITIVE, init-value=0, base-type=BT_NM_aktiv_Konditionierungsbedarf, compu-method=CM_NM_aktiv_Konditionierungsbedarf, data-constr=DC_NM_aktiv_Konditionierungsbedarf, transfer-property=TRIGGERED  # Die Batterie überwacht die Temperatur der Batterie und kann eine Konditionierung fordern.
          signal NM_aktiv_SubbusSteuerung_BMC_HV_XIX_NM_Hybrid_01_XIX_HCP5_CANFD01: start 164, 1 bit, little-endian, data-type-policy=OVERRIDE, i-signal-type=PRIMITIVE, init-value=0, base-type=BT_NM_aktiv_SubbusSteuerung_BMC_HV, compu-method=CM_NM_aktiv_SubbusSteuerung_BMC_HV, data-constr=DC_NM_aktiv_SubbusSteuerung_BMC_HV, transfer-property=TRIGGERED  # Wird für die Weiterleitung der Weckanforderungen an den SubCAN benötigt.
      frame NM_Ladegeraet_XIX_HCP5_CANFD01: id 0x1B000044, to BMC_HV, frame-length=24, can-addressing-mode=EXTENDED, can-frame-rx-behavior=CAN-FD, can-frame-tx-behavior=CAN-FD, rx-identifier-range={lower-can-id=452984832, upper-can-id=452985855}
        nm pdu NM_Ladegeraet_XIX_HCP5_CANFD01: length=24, unused-bit-pattern=0
          signal NM_Ladegeraet_CBV_AWB_XIX_NM_Ladegeraet_XIX_HCP5_CANFD01: start 4, 1 bit, little-endian, data-type-policy=OVERRIDE, i-signal-type=PRIMITIVE, init-value=0, base-type=BT_NM_Ladegeraet_CBV_AWB, compu-method=CM_NM_Ladegeraet_CBV_AWB, data-constr=DC_NM_Ladegeraet_CBV_AWB, transfer-property=TRIGGERED  # Das Signal ist zu setzen, wenn das SG aktiv den Bus geweckt hat 0 = Passiver_WakeUp = SG hat das Netzwerk nicht aktiv geweckt 1 = Akitiver_WakeUp = SG hat das Netzwerk aktiv geweckt
          signal NM_Ladegeraet_CBV_CRI_XIX_NM_Ladegeraet_XIX_HCP5_CANFD01: start 6, 1 bit, little-endian, data-type-policy=OVERRIDE, i-signal-type=PRIMITIVE, init-value=0, base-type=BT_NM_Ladegeraet_CBV_CRI, compu-method=CM_NM_Ladegeraet_CBV_CRI, data-constr=DC_NM_Ladegeraet_CBV_CRI, transfer-property=TRIGGERED  # Das Signal ist dauerhaft gesetzt, wenn das NM-Layout dem neuen NM-Layout für Teilnetzbetrieb entspricht
          signal NM_Ladegeraet_FCAB_XIX_NM_Ladegeraet_XIX_HCP5_CANFD01: start 8, 56 bit, opaque, data-type-policy=OVERRIDE, i-signal-type=ARRAY, init-value=7 x 0, base-type=BT_NM_Ladegeraet_FCAB, compu-method=CM_NM_Ladegeraet_FCAB, data-constr=DC_NM_Ladegeraet_FCAB, transfer-property=TRIGGERED-ON-CHANGE, to BMC_HV(timeout 2 s)  # FCAB = Funktions-Cluster-Aktiv-Bits
          signal NM_Ladegeraet_SNI_10_XIX_NM_Ladegeraet_XIX_HCP5_CANFD01: start 128, 10 bit, little-endian, data-type-policy=OVERRIDE, i-signal-type=PRIMITIVE, init-value=68, base-type=BT_NM_Ladegeraet_SNI_10, compu-method=CM_NM_Ladegeraet_SNI_10, data-constr=DC_NM_Ladegeraet_SNI_10, transfer-property=TRIGGERED  # Source Node-Identifier (SNI) identifiziert den Sender der NM-Botschaft (Knotenadresse) eindeutig im Fahrzeug
          signal NM_Ladegeraet_NM_State_XIX_NM_Ladegeraet_XIX_HCP5_CANFD01: start 144, 6 bit, little-endian, data-type-policy=OVERRIDE, i-signal-type=PRIMITIVE, init-value=0, base-type=BT_NM_Ladegeraet_NM_State, compu-method=CM_NM_Ladegeraet_NM_State, data-constr=DC_NM_Ladegeraet_NM_State, transfer-property=TRIGGERED  # 1 = Zustand Repeat Message (<-- Bus-Sleep Mode) 2 = Zustand Repeat Message (<-- Prepare Bus-Sleep Mode) 4 = Zustand Normal Operation (<-- Repeat Message) 8 = Zustand Normal Operation (<-- Ready Sleep)
          signal NM_Ladegeraet_UDS_CC_XIX_NM_Ladegeraet_XIX_HCP5_CANFD01: start 151, 1 bit, little-endian, data-type-policy=OVERRIDE, i-signal-type=PRIMITIVE, init-value=0, base-type=BT_NM_Ladegeraet_UDS_CC, compu-method=CM_NM_Ladegeraet_UDS_CC, data-constr=DC_NM_Ladegeraet_UDS_CC, transfer-property=TRIGGERED  # Funktionseinschränkung aufgrund aktivem UDS-Communication Control; siehe VW80124
          signal NM_Ladegeraet_Wakeup_V12_XIX_NM_Ladegeraet_XIX_HCP5_CANFD01: start 152, 8 bit, little-endian, data-type-policy=OVERRIDE, i-signal-type=PRIMITIVE, init-value=0, base-type=BT_NM_Ladegeraet_Wakeup_V12, compu-method=CM_NM_Ladegeraet_Wakeup_V12, data-constr=DC_NM_Ladegeraet_Wakeup_V12, transfer-property=TRIGGERED  # enthält die Weckursache; stehen mehrere Weckursachen parallel an, dann muss der kleinste Wert übertragen werden
          signal NM_Ladegeraet_NM_aktiv_KL15_XIX_NM_Ladegeraet_XIX_HCP5_CANFD01: start 160, 1 bit, little-endian, data-type-policy=OVERRIDE, i-signal-type=PRIMITIVE, init-value=0, base-type=BT_NM_Ladegeraet_NM_aktiv_KL15, compu-method=CM_NM_Ladegeraet_NM_aktiv_KL15, data-constr=DC_NM_Ladegeraet_NM_aktiv_KL15, transfer-property=TRIGGERED  # Steuergerät hat KL15-EIN erkannt
          signal NM_Ladegeraet_NM_aktiv_Diag_XIX_NM_Ladegeraet_XIX_HCP5_CANFD01: start 161, 1 bit, little-endian, data-type-policy=OVERRIDE, i-signal-type=PRIMITIVE, init-value=0, base-type=BT_NM_Ladegeraet_NM_aktiv_Diag, compu-method=CM_NM_Ladegeraet_NM_aktiv_Diag, data-constr=DC_NM_Ladegeraet_NM_aktiv_Diag, transfer-property=TRIGGERED  # Diagnose befindet sich nach VW80124 in einer NonDefaultDiagnostic-Session, z.B. ExtendedDiagnostic-Session
          signal NM_Ladegeraet_NM_aktiv_Tmin_XIX_NM_Ladegeraet_XIX_HCP5_CANFD01: start 162, 1 bit, little-endian, data-type-policy=OVERRIDE, i-signal-type=PRIMITIVE, init-value=0, base-type=BT_NM_Ladegeraet_NM_aktiv_Tmin, compu-method=CM_NM_Ladegeraet_NM_aktiv_Tmin, data-constr=DC_NM_Ladegeraet_NM_aktiv_Tmin, transfer-property=TRIGGERED  # Mindestaktivzeit ist noch nicht abgelaufen (bei jedem Weckereignis wird die Mindestaktivzeit neu gestartet)
      frame NM_SACID_1_XIX_HCP5_CANFD01: id 0x1B00011B, to BMC_HV, frame-length=24, can-addressing-mode=EXTENDED, can-frame-rx-behavior=CAN-FD, can-frame-tx-behavior=CAN-FD, rx-identifier-range={lower-can-id=452984832, upper-can-id=452985855}
        nm pdu NM_SACID_1_XIX_HCP5_CANFD01: length=24, unused-bit-pattern=0
          signal NM_SACID_1_CBV_AWB_XIX_NM_SACID_1_XIX_HCP5_CANFD01: start 4, 1 bit, little-endian, data-type-policy=OVERRIDE, i-signal-type=PRIMITIVE, init-value=0, base-type=BT_NM_SACID_1_CBV_AWB, compu-method=CM_NM_SACID_1_CBV_AWB, data-constr=DC_NM_SACID_1_CBV_AWB, transfer-property=TRIGGERED  # Das Signal ist zu setzen, wenn das SG aktiv den Bus geweckt hat 0 = Passiver_WakeUp = SG hat das Netzwerk nicht aktiv geweckt 1 = Akitiver_WakeUp = SG hat das Netzwerk aktiv geweckt
          signal NM_SACID_1_CBV_CRI_XIX_NM_SACID_1_XIX_HCP5_CANFD01: start 6, 1 bit, little-endian, data-type-policy=OVERRIDE, i-signal-type=PRIMITIVE, init-value=1, base-type=BT_NM_SACID_1_CBV_CRI, compu-method=CM_NM_SACID_1_CBV_CRI, data-constr=DC_NM_SACID_1_CBV_CRI, transfer-property=TRIGGERED  # Das Signal ist dauerhaft gesetzt, wenn das NM-Layout Cluster- Anforderungen enthält
          signal NM_SACID_1_FCAB_XIX_NM_SACID_1_XIX_HCP5_CANFD01: start 8, 56 bit, opaque, data-type-policy=OVERRIDE, i-signal-type=ARRAY, init-value=7 x 0b00000000, base-type=BT_NM_SACID_1_FCAB, compu-method=CM_NM_SACID_1_FCAB, data-constr=DC_NM_SACID_1_FCAB, transfer-property=TRIGGERED-ON-CHANGE, to BMC_HV(timeout 2 s)  # FCAB = Funktions-Cluster-Aktiv-Bits
          signal NM_SACID_1_SNI_10_XIX_NM_SACID_1_XIX_HCP5_CANFD01: start 128, 10 bit, little-endian, data-type-policy=OVERRIDE, i-signal-type=PRIMITIVE, init-value=283, base-type=BT_NM_SACID_1_SNI_10, compu-method=CM_NM_SACID_1_SNI_10, data-constr=DC_NM_SACID_1_SNI_10, transfer-property=TRIGGERED  # Source Node-Identifier (SNI) identifiziert den Sender der NM-Botschaft (Knotenadresse) eindeutig im Fahrzeug
          signal NM_SACID_1_NM_State_XIX_NM_SACID_1_XIX_HCP5_CANFD01: start 144, 6 bit, little-endian, data-type-policy=OVERRIDE, i-signal-type=PRIMITIVE, init-value=0, base-type=BT_NM_SACID_1_NM_State, compu-method=CM_NM_SACID_1_NM_State, data-constr=DC_NM_SACID_1_NM_State, transfer-property=TRIGGERED  # 1 = Zustand Repeat Message (<-- Bus-Sleep Mode) 2 = Zustand Repeat Message (<-- Prepare Bus-Sleep Mode) 4 = Zustand Normal Operation (<-- Repeat Message) 8 = Zustand Normal Operation (<-- Ready Sleep)
          signal NM_SACID_1_UDS_CC_XIX_NM_SACID_1_XIX_HCP5_CANFD01: start 151, 1 bit, little-endian, data-type-policy=OVERRIDE, i-signal-type=PRIMITIVE, init-value=0, base-type=BT_NM_SACID_1_UDS_CC, compu-method=CM_NM_SACID_1_UDS_CC, data-constr=DC_NM_SACID_1_UDS_CC, transfer-property=TRIGGERED  # Funktionseinschränkung aufgrund aktivem UDS-Communication Control, siehe VW80124
          signal NM_SACID_1_Wakeup_V12_XIX_NM_SACID_1_XIX_HCP5_CANFD01: start 152, 8 bit, little-endian, data-type-policy=OVERRIDE, i-signal-type=PRIMITIVE, init-value=0, base-type=BT_NM_SACID_1_Wakeup_V12, compu-method=CM_NM_SACID_1_Wakeup_V12, data-constr=DC_NM_SACID_1_Wakeup_V12, transfer-property=TRIGGERED  # enthält die Weckursache; stehen mehrere Weckursachen parallel an, dann muss der kleinste Wert übertragen werden
          signal NM_SACID_1_NM_aktiv_KL15_XIX_NM_SACID_1_XIX_HCP5_CANFD01: start 160, 1 bit, little-endian, data-type-policy=OVERRIDE, i-signal-type=PRIMITIVE, init-value=0, base-type=BT_NM_SACID_1_NM_aktiv_KL15, compu-method=CM_NM_SACID_1_NM_aktiv_KL15, data-constr=DC_NM_SACID_1_NM_aktiv_KL15, transfer-property=TRIGGERED  # Steuergerät hat KL15-EIN erkannt
          signal NM_SACID_1_NM_aktiv_Diag_XIX_NM_SACID_1_XIX_HCP5_CANFD01: start 161, 1 bit, little-endian, data-type-policy=OVERRIDE, i-signal-type=PRIMITIVE, init-value=0, base-type=BT_NM_SACID_1_NM_aktiv_Diag, compu-method=CM_NM_SACID_1_NM_aktiv_Diag, data-constr=DC_NM_SACID_1_NM_aktiv_Diag, transfer-property=TRIGGERED  # Diagnose befindet sich nach VW80124 in einer NonDefaultDiagnostic-Session, z.B. ExtendedDiagnostic-Session
          signal NM_SACID_1_NM_aktiv_Tmin_XIX_NM_SACID_1_XIX_HCP5_CANFD01: start 162, 1 bit, little-endian, data-type-policy=OVERRIDE, i-signal-type=PRIMITIVE, init-value=0, base-type=BT_NM_SACID_1_NM_aktiv_Tmin, compu-method=CM_NM_SACID_1_NM_aktiv_Tmin, data-constr=DC_NM_SACID_1_NM_aktiv_Tmin, transfer-property=TRIGGERED  # Mindestaktivzeit ist noch nicht abgelaufen (bei jedem Weckereignis wird die Mindestaktivzeit neu gestartet)
          signal NM_aktiv_Bedienung_an_Ladedose_1_XIX_NM_SACID_1_XIX_HCP5_CANFD01: start 163, 1 bit, little-endian, data-type-policy=OVERRIDE, i-signal-type=PRIMITIVE, init-value=0, base-type=BT_NM_aktiv_Bedienung_an_Ladedose_1, compu-method=CM_NM_aktiv_Bedienung_an_Ladedose_1, data-constr=DC_NM_aktiv_Bedienung_an_Ladedose_1, transfer-property=TRIGGERED  # Für die verschiedenen Bedienelemente an der Ladedose muss die HV-Ladefunktion im HCP5 geweckt werden um den Status zu erhalten und ggf. weitere Steuergeräte zu wecken
          signal NM_aktiv_Ladestecker_erkannt_1_XIX_NM_SACID_1_XIX_HCP5_CANFD01: start 164, 1 bit, little-endian, data-type-policy=OVERRIDE, i-signal-type=PRIMITIVE, init-value=0, base-type=BT_NM_aktiv_Ladestecker_erkannt_1, compu-method=CM_NM_aktiv_Ladestecker_erkannt_1, data-constr=DC_NM_aktiv_Ladestecker_erkannt_1, transfer-property=TRIGGERED  # Ladestecker erkannt und Absetzen der Information an das Hochvolt-Lademanagement
          signal NM_aktiv_SmartCharging_Aktiv_XIX_NM_SACID_1_XIX_HCP5_CANFD01: start 165, 1 bit, little-endian, data-type-policy=OVERRIDE, i-signal-type=PRIMITIVE, init-value=0, base-type=BT_NM_aktiv_SmartCharging_Aktiv, compu-method=CM_NM_aktiv_SmartCharging_Aktiv, data-constr=DC_NM_aktiv_SmartCharging_Aktiv, transfer-property=TRIGGERED  # Wenn eine Verbindung zum Smart Home's HEMS über die ConMod via WLAN aufgebaut wurde, dann muss das SACID 1 die Verbindugn so lange aktiv halten bis alle Daten empfangen wurden.
      frame NM_SACID_2_XIX_HCP5_CANFD01: id 0x1B00011C, to BMC_HV, frame-length=24, can-addressing-mode=EXTENDED, can-frame-rx-behavior=CAN-FD, can-frame-tx-behavior=CAN-FD, rx-identifier-range={lower-can-id=452984832, upper-can-id=452985855}
        nm pdu NM_SACID_2_XIX_HCP5_CANFD01: length=24, unused-bit-pattern=0
          signal NM_SACID_2_CBV_AWB_XIX_NM_SACID_2_XIX_HCP5_CANFD01: start 4, 1 bit, little-endian, data-type-policy=OVERRIDE, i-signal-type=PRIMITIVE, init-value=0, base-type=BT_NM_SACID_2_CBV_AWB, compu-method=CM_NM_SACID_2_CBV_AWB, data-constr=DC_NM_SACID_2_CBV_AWB, transfer-property=TRIGGERED  # Das Signal ist zu setzen, wenn das SG aktiv den Bus geweckt hat 0 = Passiver_WakeUp = SG hat das Netzwerk nicht aktiv geweckt 1 = Akitiver_WakeUp = SG hat das Netzwerk aktiv geweckt
          signal NM_SACID_2_CBV_CRI_XIX_NM_SACID_2_XIX_HCP5_CANFD01: start 6, 1 bit, little-endian, data-type-policy=OVERRIDE, i-signal-type=PRIMITIVE, init-value=1, base-type=BT_NM_SACID_2_CBV_CRI, compu-method=CM_NM_SACID_2_CBV_CRI, data-constr=DC_NM_SACID_2_CBV_CRI, transfer-property=TRIGGERED  # Das Signal ist dauerhaft gesetzt, wenn das NM-Layout Cluster- Anforderungen enthält
          signal NM_SACID_2_FCAB_XIX_NM_SACID_2_XIX_HCP5_CANFD01: start 8, 56 bit, opaque, data-type-policy=OVERRIDE, i-signal-type=ARRAY, init-value=7 x 0b00000000, base-type=BT_NM_SACID_2_FCAB, compu-method=CM_NM_SACID_2_FCAB, data-constr=DC_NM_SACID_2_FCAB, transfer-property=TRIGGERED-ON-CHANGE, to BMC_HV(timeout 2 s)  # FCAB = Funktions-Cluster-Aktiv-Bits
          signal NM_SACID_2_SNI_10_XIX_NM_SACID_2_XIX_HCP5_CANFD01: start 128, 10 bit, little-endian, data-type-policy=OVERRIDE, i-signal-type=PRIMITIVE, init-value=284, base-type=BT_NM_SACID_2_SNI_10, compu-method=CM_NM_SACID_2_SNI_10, data-constr=DC_NM_SACID_2_SNI_10, transfer-property=TRIGGERED  # Source Node-Identifier (SNI) identifiziert den Sender der NM-Botschaft (Knotenadresse) eindeutig im Fahrzeug
          signal NM_SACID_2_NM_State_XIX_NM_SACID_2_XIX_HCP5_CANFD01: start 144, 6 bit, little-endian, data-type-policy=OVERRIDE, i-signal-type=PRIMITIVE, init-value=0, base-type=BT_NM_SACID_2_NM_State, compu-method=CM_NM_SACID_2_NM_State, data-constr=DC_NM_SACID_2_NM_State, transfer-property=TRIGGERED  # 1 = Zustand Repeat Message (<-- Bus-Sleep Mode) 2 = Zustand Repeat Message (<-- Prepare Bus-Sleep Mode) 4 = Zustand Normal Operation (<-- Repeat Message) 8 = Zustand Normal Operation (<-- Ready Sleep)
          signal NM_SACID_2_UDS_CC_XIX_NM_SACID_2_XIX_HCP5_CANFD01: start 151, 1 bit, little-endian, data-type-policy=OVERRIDE, i-signal-type=PRIMITIVE, init-value=0, base-type=BT_NM_SACID_2_UDS_CC, compu-method=CM_NM_SACID_2_UDS_CC, data-constr=DC_NM_SACID_2_UDS_CC, transfer-property=TRIGGERED  # Funktionseinschränkung aufgrund aktivem UDS-Communication Control, siehe VW80124
          signal NM_SACID_2_Wakeup_V12_XIX_NM_SACID_2_XIX_HCP5_CANFD01: start 152, 8 bit, little-endian, data-type-policy=OVERRIDE, i-signal-type=PRIMITIVE, init-value=0, base-type=BT_NM_SACID_2_Wakeup_V12, compu-method=CM_NM_SACID_2_Wakeup_V12, data-constr=DC_NM_SACID_2_Wakeup_V12, transfer-property=TRIGGERED  # enthält die Weckursache; stehen mehrere Weckursachen parallel an, dann muss der kleinste Wert übertragen werden
          signal NM_SACID_2_NM_aktiv_KL15_XIX_NM_SACID_2_XIX_HCP5_CANFD01: start 160, 1 bit, little-endian, data-type-policy=OVERRIDE, i-signal-type=PRIMITIVE, init-value=0, base-type=BT_NM_SACID_2_NM_aktiv_KL15, compu-method=CM_NM_SACID_2_NM_aktiv_KL15, data-constr=DC_NM_SACID_2_NM_aktiv_KL15, transfer-property=TRIGGERED  # Steuergerät hat KL15-EIN erkannt
          signal NM_SACID_2_NM_aktiv_Diag_XIX_NM_SACID_2_XIX_HCP5_CANFD01: start 161, 1 bit, little-endian, data-type-policy=OVERRIDE, i-signal-type=PRIMITIVE, init-value=0, base-type=BT_NM_SACID_2_NM_aktiv_Diag, compu-method=CM_NM_SACID_2_NM_aktiv_Diag, data-constr=DC_NM_SACID_2_NM_aktiv_Diag, transfer-property=TRIGGERED  # Diagnose befindet sich nach VW80124 in einer NonDefaultDiagnostic-Session, z.B. ExtendedDiagnostic-Session
          signal NM_SACID_2_NM_aktiv_Tmin_XIX_NM_SACID_2_XIX_HCP5_CANFD01: start 162, 1 bit, little-endian, data-type-policy=OVERRIDE, i-signal-type=PRIMITIVE, init-value=0, base-type=BT_NM_SACID_2_NM_aktiv_Tmin, compu-method=CM_NM_SACID_2_NM_aktiv_Tmin, data-constr=DC_NM_SACID_2_NM_aktiv_Tmin, transfer-property=TRIGGERED  # Mindestaktivzeit ist noch nicht abgelaufen (bei jedem Weckereignis wird die Mindestaktivzeit neu gestartet)
          signal NM_aktiv_Bedienung_an_Ladedose_2_XIX_NM_SACID_2_XIX_HCP5_CANFD01: start 163, 1 bit, little-endian, data-type-policy=OVERRIDE, i-signal-type=PRIMITIVE, init-value=0, base-type=BT_NM_aktiv_Bedienung_an_Ladedose_2, compu-method=CM_NM_aktiv_Bedienung_an_Ladedose_2, data-constr=DC_NM_aktiv_Bedienung_an_Ladedose_2, transfer-property=TRIGGERED  # Für die verschiedenen Bedienelemente an der Ladedose muss die HV-Ladefunktion im HCP5 geweckt werden um den Status zu erhalten und ggf. weitere Steuergeräte zu wecken
          signal NM_aktiv_Ladestecker_erkannt_2_XIX_NM_SACID_2_XIX_HCP5_CANFD01: start 164, 1 bit, little-endian, data-type-policy=OVERRIDE, i-signal-type=PRIMITIVE, init-value=0, base-type=BT_NM_aktiv_Ladestecker_erkannt_2, compu-method=CM_NM_aktiv_Ladestecker_erkannt_2, data-constr=DC_NM_aktiv_Ladestecker_erkannt_2, transfer-property=TRIGGERED  # Ladestecker erkannt und Absetzen der Information an das Hochvolt-Lademanagement
      frame NVEM_12_XIX_HCP5_CANFD01: id 0x237, to BMC_HV, frame-length=12, can-addressing-mode=STANDARD, can-frame-rx-behavior=CAN-FD, can-frame-tx-behavior=CAN-FD
        pdu NVEM_12_XIX_HCP5_CANFD01: length=12, transmission-mode-true-timing=cyclic-timing={time-offset=0, time-period=0.1}, unused-bit-pattern=0
          signal NVEM_12_CRC_XIX_NVEM_12_XIX_HCP5_CANFD01: start 0, 8 bit, little-endian, data-type-policy=OVERRIDE, i-signal-type=PRIMITIVE, init-value=0, base-type=BT_NVEM_12_CRC, compu-method=CM_NVEM_12_CRC, data-constr=DC_NVEM_12_CRC, transfer-property=PENDING  # Für MLB: Berechnung siehe Lastenheft "Kommunikationsabsicherung für FlexRay und CAN" Ab MQB und MLBevo: Berechnung siehe Lastenheft "End-to-End Kommunikationsabsicherung" Endwerte siehe Begleitdokument "S-PDU Kennungsfolgen"
          signal NVEM_12_BZ_XIX_NVEM_12_XIX_HCP5_CANFD01: start 8, 4 bit, little-endian, data-type-policy=OVERRIDE, i-signal-type=PRIMITIVE, init-value=0, base-type=BT_NVEM_12_BZ, compu-method=CM_NVEM_12_BZ, data-constr=DC_NVEM_12_BZ, transfer-property=PENDING  # 4bit Botschaftszähler, wird mit jeder Sendebotschaft inkrementiert
          signal NVEM_Bordnetzdiagnose_XIX_NVEM_12_XIX_HCP5_CANFD01: start 12, 2 bit, little-endian, data-type-policy=OVERRIDE, i-signal-type=PRIMITIVE, init-value=0, base-type=BT_NVEM_Bordnetzdiagnose, compu-method=CM_NVEM_Bordnetzdiagnose, data-constr=DC_NVEM_Bordnetzdiagnose, transfer-property=PENDING  # Wird vom NVEM im NV-Netz ein Bordnetz-Fehler erkannt, so soll dies zu einer mehrstufigen Anzeige führen.
          signal NVEM_Last_Anf_XIX_NVEM_12_XIX_HCP5_CANFD01: start 14, 2 bit, little-endian, data-type-policy=OVERRIDE, i-signal-type=PRIMITIVE, init-value=0, base-type=BT_NVEM_Last_Anf, compu-method=CM_NVEM_Last_Anf, data-constr=DC_NVEM_Last_Anf, transfer-property=PENDING  # Das NVEM fordert für die Batteriediagnose einen Lastimpuls vom Fahrzeug an, der durch kontrollierte Verbraucherzuschaltungen (z. B. Aktivierung Heckscheibenheizung) generiert wird
          signal BEM_HL_Regelung_Status_XIX_NVEM_12_XIX_HCP5_CANFD01: start 16, 3 bit, little-endian, data-type-policy=OVERRIDE, i-signal-type=PRIMITIVE, init-value=0, base-type=BT_BEM_HL_Regelung_Status, compu-method=CM_BEM_HL_Regelung_Status, data-constr=DC_BEM_HL_Regelung_Status, transfer-property=PENDING  # Status Regelung Heizleistung
          signal NVEM_Abschaltstufe_XIX_NVEM_12_XIX_HCP5_CANFD01: start 19, 2 bit, little-endian, data-type-policy=OVERRIDE, i-signal-type=PRIMITIVE, init-value=0, base-type=BT_NVEM_Abschaltstufe, compu-method=CM_NVEM_Abschaltstufe, data-constr=DC_NVEM_Abschaltstufe, transfer-property=PENDING, to BMC_HV(timeout 1 s)  # Abschaltstufe aus dem Ruheenergiemanagement Maßnahmen des Empfängers werden im QLAH Ruhestrommanagement definiert
          signal NVEM_NV_BAT_ZellStatus_Index_Anf_XIX_NVEM_12_XIX_HCP5_CANFD01: start 21, 4 bit, little-endian, data-type-policy=OVERRIDE, i-signal-type=PRIMITIVE, init-value=0, base-type=BT_NVEM_NV_BAT_ZellStatus_Index_Anf, compu-method=CM_NVEM_NV_BAT_ZellStatus_Index_Anf, data-constr=DC_NVEM_NV_BAT_ZellStatus_Index_Anf, transfer-property=PENDING  # Multiplex signal for cell number of low voltage battery.
          signal NVEM_NV_BAT_ZellStatus_Typ_Anf_XIX_NVEM_12_XIX_HCP5_CANFD01: start 25, 3 bit, little-endian, data-type-policy=OVERRIDE, i-signal-type=PRIMITIVE, init-value=0, base-type=BT_NVEM_NV_BAT_ZellStatus_Typ_Anf, compu-method=CM_NVEM_NV_BAT_ZellStatus_Typ_Anf, data-constr=DC_NVEM_NV_BAT_ZellStatus_Typ_Anf, transfer-property=PENDING  # Multiplex signal for cell status of low voltage battery.
          signal NVEM_Freigabe_OTA_XIX_NVEM_12_XIX_HCP5_CANFD01: start 28, 2 bit, little-endian, data-type-policy=OVERRIDE, i-signal-type=PRIMITIVE, init-value=0, base-type=BT_NVEM_Freigabe_OTA, compu-method=CM_NVEM_Freigabe_OTA, data-constr=DC_NVEM_Freigabe_OTA, transfer-property=PENDING  # Bestätigung oder Ablehnung eines konkreten, angefragten Online-Updates durch das Energiemangement
          signal BEM_Generatordiagnose_XIX_NVEM_12_XIX_HCP5_CANFD01: start 30, 2 bit, little-endian, data-type-policy=OVERRIDE, i-signal-type=PRIMITIVE, init-value=0, base-type=BT_BEM_Generatordiagnose, compu-method=CM_BEM_Generatordiagnose, data-constr=DC_BEM_Generatordiagnose, transfer-property=PENDING  # Ansteuerung Generatorwarnleuchte im Kombi
          signal NVEM_DC_uSoll_NV_XIX_NVEM_12_XIX_HCP5_CANFD01: start 32, 8 bit, little-endian, data-type-policy=OVERRIDE, i-signal-type=PRIMITIVE, init-value=116, base-type=BT_NVEM_DC_uSoll_NV, invalid-value=Invalid_NVEM_DC_uSoll_NV_XIX_NVEM_12_XIX_HCP5_CANFD01:255, compu-method=CM_NVEM_DC_uSoll_NV, data-constr=DC_NVEM_DC_uSoll_NV, unit=Unit_Unit_Volt, transfer-property=PENDING  # Sollspannung 12V Seite des DC Wandlers, feine Auflösung
          signal NVEM_DC_iSoll_NV_XIX_NVEM_12_XIX_HCP5_CANFD01: start 40, 8 bit, little-endian, data-type-policy=OVERRIDE, i-signal-type=PRIMITIVE, init-value=254, base-type=BT_NVEM_DC_iSoll_NV, invalid-value=Invalid_NVEM_DC_iSoll_NV_XIX_NVEM_12_XIX_HCP5_CANFD01:255, compu-method=CM_NVEM_DC_iSoll_NV, data-constr=DC_NVEM_DC_iSoll_NV, unit=Unit_Unit_Amper, transfer-property=PENDING  # Soll-Entladestrom 12V Seite des DCDC Wandlers
          signal BEM_Batt_Ab_XIX_NVEM_12_XIX_HCP5_CANFD01: start 48, 1 bit, little-endian, data-type-policy=OVERRIDE, i-signal-type=PRIMITIVE, init-value=0, base-type=BT_BEM_Batt_Ab, compu-method=CM_BEM_Batt_Ab, data-constr=DC_BEM_Batt_Ab, transfer-property=PENDING  # Batterieverbindungskontrolle: 0x0: Batterie am Bordnetz 0x1: Batterie ab erkannt
          signal BEM_Red_Innengeblaese_XIX_NVEM_12_XIX_HCP5_CANFD01: start 49, 2 bit, little-endian, data-type-policy=OVERRIDE, i-signal-type=PRIMITIVE, init-value=0, base-type=BT_BEM_Red_Innengeblaese, compu-method=CM_BEM_Red_Innengeblaese, data-constr=DC_BEM_Red_Innengeblaese, transfer-property=PENDING  # Reduzierung Innengebläse
          signal NVEM_MV_DC_uMinLV_XIX_NVEM_12_XIX_HCP5_CANFD01: start 51, 7 bit, little-endian, data-type-policy=OVERRIDE, i-signal-type=PRIMITIVE, init-value=126, base-type=BT_NVEM_MV_DC_uMinLV, invalid-value=Invalid_NVEM_MV_DC_uMinLV_XIX_NVEM_12_XIX_HCP5_CANFD01:127, compu-method=CM_NVEM_MV_DC_uMinLV, data-constr=DC_NVEM_MV_DC_uMinLV, unit=Unit_Unit_Volt, transfer-property=PENDING  # Abregelgrenze: minimal erlaubte Bordnetzspannung im Hochsetzbetrieb vom 12V-Bordnetz ins 48V-Netz
          signal NVEM_MV_DC_uSollLV_XIX_NVEM_12_XIX_HCP5_CANFD01: start 58, 7 bit, little-endian, data-type-policy=OVERRIDE, i-signal-type=PRIMITIVE, init-value=126, base-type=BT_NVEM_MV_DC_uSollLV, invalid-value=Invalid_NVEM_MV_DC_uSollLV_XIX_NVEM_12_XIX_HCP5_CANFD01:127, compu-method=CM_NVEM_MV_DC_uSollLV, data-constr=DC_NVEM_MV_DC_uSollLV, unit=Unit_Unit_Volt, transfer-property=PENDING  # Sollwert für die 12V-Bordnetzspannung im Tiefsetzbetrieb vom 48V-Netz ins 12V-Bordnetz
          signal BEM_STH_Einschaltverbot_XIX_NVEM_12_XIX_HCP5_CANFD01: start 65, 1 bit, little-endian, data-type-policy=OVERRIDE, i-signal-type=PRIMITIVE, init-value=0, base-type=BT_BEM_STH_Einschaltverbot, compu-method=CM_BEM_STH_Einschaltverbot, data-constr=DC_BEM_STH_Einschaltverbot, transfer-property=PENDING  # Einschränkung Standheizung/-lüftung durch BEM: Setzt der BEM das Bit, dann darf die Standheizung nicht mehr einschalten (Die Standheizung muss aber nicht abschalten, sondern darf weiterbrennen) (Initialisierungswert aus EEprom)
          signal BEM_STH_Zielzeit_XIX_NVEM_12_XIX_HCP5_CANFD01: start 66, 4 bit, little-endian, data-type-policy=OVERRIDE, i-signal-type=PRIMITIVE, init-value=14, base-type=BT_BEM_STH_Zielzeit, invalid-value=Invalid_BEM_STH_Zielzeit_XIX_NVEM_12_XIX_HCP5_CANFD01:15, compu-method=CM_BEM_STH_Zielzeit, data-constr=DC_BEM_STH_Zielzeit, unit=Unit_Unit_Minut, transfer-property=PENDING  # Maximal mögliche Zeit für den Standheizungsbetrieb, um die Startfähigkeit nicht zu gefährden
          signal NVEM_Verbraucher_Information_XIX_NVEM_12_XIX_HCP5_CANFD01: start 70, 3 bit, little-endian, data-type-policy=OVERRIDE, i-signal-type=PRIMITIVE, init-value=6, base-type=BT_NVEM_Verbraucher_Information, invalid-value=Invalid_NVEM_Verbraucher_Information_XIX_NVEM_12_XIX_HCP5_CANFD01:7, compu-method=CM_NVEM_Verbraucher_Information, data-constr=DC_NVEM_Verbraucher_Information, transfer-property=PENDING  # Mit diesem Signal löst Das NVM eine Anzeige bzgl. einer bevorstehenden oder erfolgten Verbraucherabschaltung aus
          signal NVEM3_Absch_SCR_XIX_NVEM_12_XIX_HCP5_CANFD01: start 73, 1 bit, little-endian, data-type-policy=OVERRIDE, i-signal-type=PRIMITIVE, init-value=0, base-type=BT_NVEM3_Absch_SCR, compu-method=CM_NVEM3_Absch_SCR, data-constr=DC_NVEM3_Absch_SCR, transfer-property=PENDING  # Abschaltung der SCR-Heizung durch das NVEM bei energetisch kritischen Zuständen.
          signal NVEM_Bordnetz_Information_XIX_NVEM_12_XIX_HCP5_CANFD01: start 76, 4 bit, little-endian, data-type-policy=OVERRIDE, i-signal-type=PRIMITIVE, init-value=14, base-type=BT_NVEM_Bordnetz_Information, invalid-value=Invalid_NVEM_Bordnetz_Information_XIX_NVEM_12_XIX_HCP5_CANFD01:15, compu-method=CM_NVEM_Bordnetz_Information, data-constr=DC_NVEM_Bordnetz_Information, transfer-property=PENDING  # Informationsanzeigen zum 12V - Bordnetz
          signal NVEM_DC_uMin_NV_XIX_NVEM_12_XIX_HCP5_CANFD01: start 80, 8 bit, little-endian, data-type-policy=OVERRIDE, i-signal-type=PRIMITIVE, init-value=122, base-type=BT_NVEM_DC_uMin_NV, compu-method=CM_NVEM_DC_uMin_NV, data-constr=DC_NVEM_DC_uMin_NV, unit=Unit_Unit_Volt, transfer-property=PENDING  # Mindestspannung des DCDC Wandlers im Hochsetzbetrieb auf 12V Seite
          signal NVEM_MV_DC_iSoll_NV_XIX_NVEM_12_XIX_HCP5_CANFD01: start 88, 8 bit, little-endian, data-type-policy=OVERRIDE, i-signal-type=PRIMITIVE, init-value=254, base-type=BT_NVEM_MV_DC_iSoll_NV, invalid-value=Invalid_NVEM_MV_DC_iSoll_NV_XIX_NVEM_12_XIX_HCP5_CANFD01:255, compu-method=CM_NVEM_MV_DC_iSoll_NV, data-constr=DC_NVEM_MV_DC_iSoll_NV, unit=Unit_Unit_Amper, transfer-property=PENDING  # Sollstromvorgabe NVEM an MV - DCDC Wandler
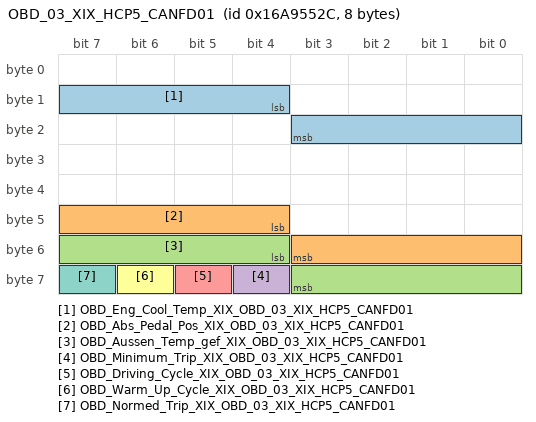
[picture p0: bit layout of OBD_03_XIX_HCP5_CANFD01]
      frame OBD_03_XIX_HCP5_CANFD01: id 0x16A9552C, to BMC_HV, frame-length=8, can-addressing-mode=EXTENDED, can-frame-rx-behavior=CAN-FD, can-frame-tx-behavior=CAN-FD
        pdu OBD_03_XIX_HCP5_CANFD01: length=8, transmission-mode-true-timing=cyclic-timing={time-offset=0, time-period=0.32}, unused-bit-pattern=0
          signal OBD_Eng_Cool_Temp_XIX_OBD_03_XIX_HCP5_CANFD01: start 12, 8 bit, little-endian, data-type-policy=OVERRIDE, i-signal-type=PRIMITIVE, init-value=255, base-type=BT_OBD_Eng_Cool_Temp, compu-method=CM_OBD_Eng_Cool_Temp, data-constr=DC_OBD_Eng_Cool_Temp, unit=Unit_Unit_DegreCelsi, transfer-property=PENDING, to BMC_HV(timeout 3.2 s)  # Engine Coolant Temperature Übertragung von Meßgrößen an das Getriebesteuergerät für Freeze Frame Abspeicherung bei Getriebefehlern PID $05 Engine Coolant Temperature; -40 .. +215°C mit 1°C/bit und 40°C Offset
          signal OBD_Abs_Pedal_Pos_XIX_OBD_03_XIX_HCP5_CANFD01: start 44, 8 bit, little-endian, data-type-policy=OVERRIDE, i-signal-type=PRIMITIVE, init-value=255, base-type=BT_OBD_Abs_Pedal_Pos, compu-method=CM_OBD_Abs_Pedal_Pos, data-constr=DC_OBD_Abs_Pedal_Pos, unit=Unit_Unit_PerCent, transfer-property=PENDING, to BMC_HV(timeout 3.2 s)  # Absolute Pedal Position Übertragung von Meßgrößen an das Getriebesteuergerät für Freeze Frame Abspeicherung bei Getriebefehlern PID $49 Accelerator Pedal Position D; 0 .. 100% mit 100/255 %/bit
          signal OBD_Aussen_Temp_gef_XIX_OBD_03_XIX_HCP5_CANFD01: start 52, 8 bit, little-endian, data-type-policy=OVERRIDE, i-signal-type=PRIMITIVE, init-value=254, base-type=BT_OBD_Aussen_Temp_gef, invalid-value=Invalid_OBD_Aussen_Temp_gef_XIX_OBD_03_XIX_HCP5_CANFD01:255, compu-method=CM_OBD_Aussen_Temp_gef, data-constr=DC_OBD_Aussen_Temp_gef, unit=Unit_Unit_DegreCelsi, transfer-property=PENDING, to BMC_HV(timeout 3.2 s)  # Gefilterte Aussentemperatur vom Motor für OBD Funktionen.
          signal OBD_Minimum_Trip_XIX_OBD_03_XIX_HCP5_CANFD01: start 60, 1 bit, little-endian, data-type-policy=OVERRIDE, i-signal-type=PRIMITIVE, init-value=0, base-type=BT_OBD_Minimum_Trip, compu-method=CM_OBD_Minimum_Trip, data-constr=DC_OBD_Minimum_Trip, transfer-property=PENDING, to BMC_HV(timeout 3.2 s)  # Grundlage OBD-Gesetz CCR 1968.2 (d)(4.3) Denominator Specifications Bildung des General Denominator "Normed Trip": 600 sec. (kumulativ) Zeit nach Motorstart 300 sec. (kumulativ) mit Fahrzeuggeschwindigkeit > 25 mph (40 km/h) 30 sec. (kontinuierlich) Leerlauf Wenn alle diese Bedingungen erfüllt wurden ist ein OBD_Min_Normed_Trip erfüllt
          signal OBD_Driving_Cycle_XIX_OBD_03_XIX_HCP5_CANFD01: start 61, 1 bit, little-endian, data-type-policy=OVERRIDE, i-signal-type=PRIMITIVE, init-value=0, base-type=BT_OBD_Driving_Cycle, compu-method=CM_OBD_Driving_Cycle, data-constr=DC_OBD_Driving_Cycle, transfer-property=PENDING, to BMC_HV(timeout 3.2 s)  # Signalisierung Driving Cycle Qualifizierung - Trigger Ignition Cycle Counter
          signal OBD_Warm_Up_Cycle_XIX_OBD_03_XIX_HCP5_CANFD01: start 62, 1 bit, little-endian, data-type-policy=OVERRIDE, i-signal-type=PRIMITIVE, init-value=0, base-type=BT_OBD_Warm_Up_Cycle, compu-method=CM_OBD_Warm_Up_Cycle, data-constr=DC_OBD_Warm_Up_Cycle, transfer-property=PENDING, to BMC_HV(timeout 3.2 s)  # Mit dem Warm-Up-Cycle wird der zentrale Verlernzähler vom Gateway inkrementiert
          signal OBD_Normed_Trip_XIX_OBD_03_XIX_HCP5_CANFD01: start 63, 1 bit, little-endian, data-type-policy=OVERRIDE, i-signal-type=PRIMITIVE, init-value=0, base-type=BT_OBD_Normed_Trip, compu-method=CM_OBD_Normed_Trip, data-constr=DC_OBD_Normed_Trip, transfer-property=PENDING, to BMC_HV(timeout 3.2 s)  # Gesetzlich definierte "Normed Condition" erfüllt, "General Denominator" darf erhöht werden
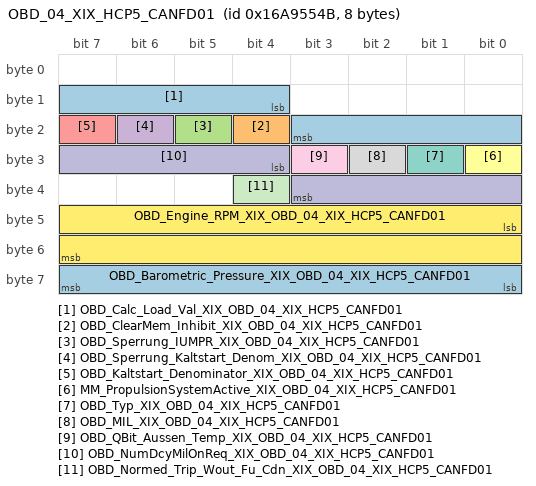
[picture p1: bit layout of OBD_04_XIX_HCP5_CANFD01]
      frame OBD_04_XIX_HCP5_CANFD01: id 0x16A9554B, to BMC_HV, frame-length=8, can-addressing-mode=EXTENDED, can-frame-rx-behavior=CAN-FD, can-frame-tx-behavior=CAN-FD
        pdu OBD_04_XIX_HCP5_CANFD01: length=8, minimum-delay=0.08, transmission-mode-true-timing={cyclic-timing={time-offset=0, time-period=0.32}, event-controlled-timing={number-of-repetitions=0, repetition-period=0}}, unused-bit-pattern=0
          signal OBD_Calc_Load_Val_XIX_OBD_04_XIX_HCP5_CANFD01: start 12, 8 bit, little-endian, data-type-policy=OVERRIDE, i-signal-type=PRIMITIVE, init-value=255, base-type=BT_OBD_Calc_Load_Val, compu-method=CM_OBD_Calc_Load_Val, data-constr=DC_OBD_Calc_Load_Val, unit=Unit_Unit_PerCent, transfer-property=PENDING, to BMC_HV(timeout 3.2 s)  # Calculated Load Value Übertragung von Meßgrößen an das Getriebesteuergerät für Freeze Frame Abspeicherung bei Getriebefehlern PID $04 Calculated Load Value; 0 .. 100% mit 100/255 % per bit
          signal OBD_ClearMem_Inhibit_XIX_OBD_04_XIX_HCP5_CANFD01: start 20, 1 bit, little-endian, data-type-policy=OVERRIDE, i-signal-type=PRIMITIVE, init-value=0, base-type=BT_OBD_ClearMem_Inhibit, compu-method=CM_OBD_ClearMem_Inhibit, data-constr=DC_OBD_ClearMem_Inhibit, transfer-property=PENDING, to BMC_HV(timeout 3.2 s)  # Bei FSP_Loeschen_zulässig müssen alle OBD-ECUs im Gesamtfahrzeug einen Service 04hex Request (Ereignisspeicher löschen) korrekt ausführen. In MLB-, MLBevo-, MQB-Fahrzeugkonzepten muss der MIL-Master/Motorsteuergerät bei Kl.15 ein, projektabhängig, konstant OBD_ClearMem_Inhibit = 0 senden, sofern das Löschen des Ereignisspeichers noch in jedem Betriebszustand (auch bei laufendem Motor, etc.) gefordert ist. Projektspezifisch im MLB-, MLBevo-, und MQB-Fahrzeugkonzepten und vollumfänglich in MQB_37W- und MLB3-Fahrzeugkonzepten wird das Ereignisspeicher löschen in allen OBD-ECUs auf den Betriebszustand stehendes Fahrzeug und stehender Motor beschränkt und die entsprechende Freigabe das Ereignisspeicher Löschens vom MIL-Master über das Bussignal OBD_ClearMem_Inhibit für alle anderen OBD-ECUs im Gesamtfahrzeug signalisiert. Hinweis: Steuergerät- oder Komponentenspezifische Randbedingungen sind unter Abhängigkeit des Sicherheitskonzepts zu prüfen und zu bewerten.
          signal OBD_Sperrung_IUMPR_XIX_OBD_04_XIX_HCP5_CANFD01: start 21, 1 bit, little-endian, data-type-policy=OVERRIDE, i-signal-type=PRIMITIVE, init-value=0, base-type=BT_OBD_Sperrung_IUMPR, compu-method=CM_OBD_Sperrung_IUMPR, data-constr=DC_OBD_Sperrung_IUMPR, transfer-property=PENDING, to BMC_HV(timeout 3.2 s)  # Wenn der General Denominator auf Grund eines Fehlers in den Eingangsgrößen gesperrt wird, wird diese Information über Bussystem als OBD-Statusinformation OBD_Sperrung_IUMPR für andere OBD-Steuergeräte bereitgestellt. Das MSG (MIL-Master) setzt dieses Bit, wenn auf Grund vorliegender Sperrbedingungen keine Inkrementierung des GeneralDenominator mehr stattfindet. Im Empfänger-SG ist entsprechend die Inkrementierung des oder der Numeratoren einzufrieren.
          signal OBD_Sperrung_Kaltstart_Denom_XIX_OBD_04_XIX_HCP5_CANFD01: start 22, 1 bit, little-endian, data-type-policy=OVERRIDE, i-signal-type=PRIMITIVE, init-value=0, base-type=BT_OBD_Sperrung_Kaltstart_Denom, compu-method=CM_OBD_Sperrung_Kaltstart_Denom, data-constr=DC_OBD_Sperrung_Kaltstart_Denom, transfer-property=PENDING, to BMC_HV(timeout 3.2 s)  # Information vom MIL Master, dass die Bildung des EVAP Denominators im Motor nicht möglich ist und damit der noECM-Denominator gesperrt werden darf.
          signal OBD_Kaltstart_Denominator_XIX_OBD_04_XIX_HCP5_CANFD01: start 23, 1 bit, little-endian, data-type-policy=OVERRIDE, i-signal-type=PRIMITIVE, init-value=0, base-type=BT_OBD_Kaltstart_Denominator, compu-method=CM_OBD_Kaltstart_Denominator, data-constr=DC_OBD_Kaltstart_Denominator, transfer-property=PENDING, to BMC_HV(timeout 3.2 s)  # Bestimmte Diagnosen werden nur unter Kaltstartbedingungen durchgeführt, der entsprechende Denominator bei IUMPR-pflichtigen Systemen wird anhand dieses vom MSG gebildeten Signals inkrementiert. (Entspricht EVAP-Denominator)
          signal MM_PropulsionSystemActive_XIX_OBD_04_XIX_HCP5_CANFD01: start 24, 1 bit, little-endian, data-type-policy=OVERRIDE, i-signal-type=PRIMITIVE, init-value=0, base-type=BT_MM_PropulsionSystemActive, compu-method=CM_MM_PropulsionSystemActive, data-constr=DC_MM_PropulsionSystemActive, transfer-property=TRIGGERED-ON-CHANGE-WITHOUT-REPETITION, to BMC_HV(timeout 3.2 s)  # Fahrzeug ist fahrbereit
          signal OBD_Typ_XIX_OBD_04_XIX_HCP5_CANFD01: start 25, 1 bit, little-endian, data-type-policy=OVERRIDE, i-signal-type=PRIMITIVE, init-value=0, base-type=BT_OBD_Typ, compu-method=CM_OBD_Typ, data-constr=DC_OBD_Typ, transfer-property=PENDING, to BMC_HV(timeout 3.2 s)  # Abgastyp OBD Hinweis: In Fahrzeugen mit dem Zielmarkt China und einer Zertifizierung ab China 6 muss auf dem Signal "OBD_Typ" der Wert "US_OBD" gesendet werden."
          signal OBD_MIL_XIX_OBD_04_XIX_HCP5_CANFD01: start 26, 1 bit, little-endian, data-type-policy=OVERRIDE, i-signal-type=PRIMITIVE, init-value=0, base-type=BT_OBD_MIL, invalid-value=Invalid_OBD_MIL_XIX_OBD_04_XIX_HCP5_CANFD01:1, compu-method=CM_OBD_MIL, data-constr=DC_OBD_MIL, transfer-property=TRIGGERED-ON-CHANGE-WITHOUT-REPETITION  # Ansteuerung der MIL
          signal OBD_QBit_Aussen_Temp_XIX_OBD_04_XIX_HCP5_CANFD01: start 27, 1 bit, little-endian, data-type-policy=OVERRIDE, i-signal-type=PRIMITIVE, init-value=1, base-type=BT_OBD_QBit_Aussen_Temp, compu-method=CM_OBD_QBit_Aussen_Temp, data-constr=DC_OBD_QBit_Aussen_Temp, transfer-property=TRIGGERED-ON-CHANGE-WITHOUT-REPETITION, to BMC_HV(timeout 3.2 s)  # QBit der Aussentemperatur. Gesetzt bei Ersatzwert, Init oder Fehler.
          signal OBD_NumDcyMilOnReq_XIX_OBD_04_XIX_HCP5_CANFD01: start 28, 8 bit, little-endian, data-type-policy=OVERRIDE, i-signal-type=PRIMITIVE, init-value=0, base-type=BT_OBD_NumDcyMilOnReq, compu-method=CM_OBD_NumDcyMilOnReq, data-constr=DC_OBD_NumDcyMilOnReq, unit=Unit_Unit_None, transfer-property=PENDING, to BMC_HV(timeout 3.2 s)  # Anzahl der DrivingCycle für MIL-Entprellung von MIL-Master
          signal OBD_Normed_Trip_Wout_Fu_Cdn_XIX_OBD_04_XIX_HCP5_CANFD01: start 36, 1 bit, little-endian, data-type-policy=OVERRIDE, i-signal-type=PRIMITIVE, init-value=0, base-type=BT_OBD_Normed_Trip_Wout_Fu_Cdn, compu-method=CM_OBD_Normed_Trip_Wout_Fu_Cdn, data-constr=DC_OBD_Normed_Trip_Wout_Fu_Cdn, transfer-property=PENDING  # Bedingung für General Denominator-Inkrementierung ohne FueledEngine-Operation -> wird für die Berechnung des General Denominators in der Motorsteuerung (ScanTool-Ausgabe Mode$09, InfoType$08, OBDCOND) benötigt
          signal OBD_Engine_RPM_XIX_OBD_04_XIX_HCP5_CANFD01: start 40, 16 bit, little-endian, data-type-policy=OVERRIDE, i-signal-type=PRIMITIVE, init-value=0, base-type=BT_OBD_Engine_RPM, compu-method=CM_OBD_Engine_RPM, data-constr=DC_OBD_Engine_RPM, unit=Unit_Unit_MinutInver, transfer-property=PENDING, to BMC_HV(timeout 3.2 s)  # Motordrehzahl des Verbrennungsmotors für OBD freeze frame
          signal OBD_Barometric_Pressure_XIX_OBD_04_XIX_HCP5_CANFD01: start 56, 8 bit, little-endian, data-type-policy=OVERRIDE, i-signal-type=PRIMITIVE, init-value=0, base-type=BT_OBD_Barometric_Pressure, compu-method=CM_OBD_Barometric_Pressure, data-constr=DC_OBD_Barometric_Pressure, unit=Unit_Unit_KiloPascal, transfer-property=PENDING, to BMC_HV(timeout 3.2 s)  # Umgebungsdruck für OBD freeze frame
      frame OBD_HCP1_SOK_XIX_HCP5_CANFD01: id 0x17E4000F, to BMC_HV, frame-length=6, can-addressing-mode=EXTENDED, can-frame-rx-behavior=CAN-FD, can-frame-tx-behavior=CAN-FD
        secured i pdu OBD_HCP1_SOK_XIX_HCP5_CANFD01:
          length=6
          authentication-props=SecureCommunicationAuthenticationProps_XIX_32
          freshness-props=SecureCommunicationFreshnessProps
          payload=PT_OBD_HCP1
          secure-communication-props={auth-data-freshness-length=0, auth-data-freshness-start-position=0, auth-info-tx-length=32, authentication-build-attempts=1, authentication-retries=4, data-id=864, freshness-value-id=2, freshness-value-length=64, freshness-value-tx-length=0}
          use-as-cryptographic-i-pdu=false
      frame OBD_Hybrid_01_SOK_XIX_HCP5_CANFD01: id 0x17E40005, from BMC_HV, frame-length=6, can-addressing-mode=EXTENDED, can-frame-rx-behavior=CAN-FD, can-frame-tx-behavior=CAN-FD
        secured i pdu OBD_Hybrid_01_SOK_XIX_HCP5_CANFD01:
          length=6
          authentication-props=SecureCommunicationAuthenticationProps_XIX_32
          freshness-props=SecureCommunicationFreshnessProps
          payload=PT_OBD_Hybrid_01
          secure-communication-props={auth-data-freshness-length=0, auth-data-freshness-start-position=0, auth-info-tx-length=32, authentication-build-attempts=1, authentication-retries=4, data-id=865, freshness-value-id=7, freshness-value-length=64, freshness-value-tx-length=0}
          use-as-cryptographic-i-pdu=false
      frame OBDC_Funktionaler_Req_All_FD_XIX_HCP5_CANFD01: id 0x1C410200, to BMC_HV, frame-length=64, can-addressing-mode=EXTENDED, can-frame-rx-behavior=CAN-FD, can-frame-tx-behavior=CAN-FD
        n pdu OBDC_Funktionaler_Req_All_FD_XIX_HCP5_CANFD01: length=64
      frame OBDC_Hybrid_01_Req_FD_XIX_HCP5_CANFD01: id 0x1C40027B, to BMC_HV, frame-length=64, can-addressing-mode=EXTENDED, can-frame-rx-behavior=CAN-FD, can-frame-tx-behavior=CAN-FD
        n pdu OBDC_Hybrid_01_Req_FD_XIX_HCP5_CANFD01: length=64
      frame OBDC_Hybrid_01_Resp_FD_XIX_HCP5_CANFD01: id 0x1C42027B, from BMC_HV, frame-length=64, can-addressing-mode=EXTENDED, can-frame-rx-behavior=CAN-FD, can-frame-tx-behavior=CAN-FD
        n pdu OBDC_Hybrid_01_Resp_FD_XIX_HCP5_CANFD01: length=64
      frame OBDC_SSN_BJB_Req_XIX_HCP5_CANFD01: id 0x17FC70D0, to BMC_HV, frame-length=8, can-addressing-mode=EXTENDED, can-frame-rx-behavior=CAN-FD, can-frame-tx-behavior=CAN-FD
        n pdu OBDC_SSN_BJB_Req_XIX_HCP5_CANFD01: length=8
      frame OBDC_SSN_BJB_Resp_XIX_HCP5_CANFD01: id 0x17FE70D0, from BMC_HV, frame-length=8, can-addressing-mode=EXTENDED, can-frame-rx-behavior=CAN-FD, can-frame-tx-behavior=CAN-FD
        n pdu OBDC_SSN_BJB_Resp_XIX_HCP5_CANFD01: length=8
      frame OBDC_SSN_UI2Sens01_Req_XIX_HCP5_CANFD01: id 0x17FC71B1, to BMC_HV, frame-length=8, can-addressing-mode=EXTENDED, can-frame-rx-behavior=CAN-FD, can-frame-tx-behavior=CAN-FD
        n pdu OBDC_SSN_UI2Sens01_Req_XIX_HCP5_CANFD01: length=8
      frame OBDC_SSN_UI2Sens01_Resp_XIX_HCP5_CANFD01: id 0x17FE71B1, from BMC_HV, frame-length=8, can-addressing-mode=EXTENDED, can-frame-rx-behavior=CAN-FD, can-frame-tx-behavior=CAN-FD
        n pdu OBDC_SSN_UI2Sens01_Resp_XIX_HCP5_CANFD01: length=8
      frame OBDC_SSN_UI2Sens02_Req_XIX_HCP5_CANFD01: id 0x17FC71B2, to BMC_HV, frame-length=8, can-addressing-mode=EXTENDED, can-frame-rx-behavior=CAN-FD, can-frame-tx-behavior=CAN-FD
        n pdu OBDC_SSN_UI2Sens02_Req_XIX_HCP5_CANFD01: length=8
      frame OBDC_SSN_UI2Sens02_Resp_XIX_HCP5_CANFD01: id 0x17FE71B2, from BMC_HV, frame-length=8, can-addressing-mode=EXTENDED, can-frame-rx-behavior=CAN-FD, can-frame-tx-behavior=CAN-FD
        n pdu OBDC_SSN_UI2Sens02_Resp_XIX_HCP5_CANFD01: length=8
      frame OBDx_allOBD_Req_XIX_HCP5_CANFD01: id 0x18DB33F1, to BMC_HV, frame-length=8, can-addressing-mode=EXTENDED, can-frame-rx-behavior=CAN-FD, can-frame-tx-behavior=CAN-FD
        n pdu OBDx_allOBD_Req_XIX_HCP5_CANFD01: length=8
      frame OBDx_Hybrid_01_Req_XIX_HCP5_CANFD01: id 0x18DA05F1, to BMC_HV, frame-length=8, can-addressing-mode=EXTENDED, can-frame-rx-behavior=CAN-FD, can-frame-tx-behavior=CAN-FD
        n pdu OBDx_Hybrid_01_Req_XIX_HCP5_CANFD01: length=8
      frame OBDx_Hybrid_01_Resp_XIX_HCP5_CANFD01: id 0x18DAF105, from BMC_HV, frame-length=8, can-addressing-mode=EXTENDED, can-frame-rx-behavior=CAN-FD, can-frame-tx-behavior=CAN-FD
        n pdu OBDx_Hybrid_01_Resp_XIX_HCP5_CANFD01: length=8
      frame OBG_01_XIX_HCP5_CANFD01: id 0x12DD5518, to BMC_HV, frame-length=64, can-addressing-mode=EXTENDED, can-frame-rx-behavior=CAN-FD, can-frame-tx-behavior=CAN-FD
        pdu OBG_01_XIX_HCP5_CANFD01: length=60, transmission-mode-true-timing=cyclic-timing={time-offset=0, time-period=0.1}, unused-bit-pattern=0
          signal OBG_01_BZ_XIX_OBG_01_XIX_HCP5_CANFD01: start 8, 4 bit, little-endian, data-type-policy=OVERRIDE, i-signal-type=PRIMITIVE, init-value=0, base-type=BT_OBG_01_BZ, compu-method=CM_OBG_01_BZ, data-constr=DC_OBG_01_BZ, transfer-property=PENDING  # 4bit Botschaftszähler, wird mit jeder Sendebotschaft inkrementiert
          signal HVLE_IstSpannung_HV_XIX_OBG_01_XIX_HCP5_CANFD01: start 12, 10 bit, little-endian, data-type-policy=OVERRIDE, i-signal-type=PRIMITIVE, init-value=1022, base-type=BT_HVLE_IstSpannung_HV, invalid-value=Invalid_HVLE_IstSpannung_HV_XIX_OBG_01_XIX_HCP5_CANFD01:1023, compu-method=CM_HVLE_IstSpannung_HV, data-constr=DC_HVLE_IstSpannung_HV, unit=Unit_Unit_Volt, transfer-property=PENDING, to BMC_HV(timeout 1 s)  # aktuelle DC-Ausgangsspannung des Ladegeraet
          signal HVLE_Ist_Wirkungsgrad_XIX_OBG_01_XIX_HCP5_CANFD01: start 22, 7 bit, little-endian, data-type-policy=OVERRIDE, i-signal-type=PRIMITIVE, init-value=126, base-type=BT_HVLE_Ist_Wirkungsgrad, invalid-value=Invalid_HVLE_Ist_Wirkungsgrad_XIX_OBG_01_XIX_HCP5_CANFD01:127, compu-method=CM_HVLE_Ist_Wirkungsgrad, data-constr=DC_HVLE_Ist_Wirkungsgrad, unit=Unit_Unit_PerCent, transfer-property=PENDING  # aktueller Wirkungsgrad des Ladegeraet
          signal HVLE_Netzfrequenz_EVU_XIX_OBG_01_XIX_HCP5_CANFD01: start 29, 9 bit, little-endian, data-type-policy=OVERRIDE, i-signal-type=PRIMITIVE, init-value=510, base-type=BT_HVLE_Netzfrequenz_EVU, invalid-value=Invalid_HVLE_Netzfrequenz_EVU_XIX_OBG_01_XIX_HCP5_CANFD01:511, compu-method=CM_HVLE_Netzfrequenz_EVU, data-constr=DC_HVLE_Netzfrequenz_EVU, unit=Unit_Unit_Hertz, transfer-property=PENDING  # aktuelle AC-Netzfrequenz im Eingangskreis des Ladegeraet
          signal HVLE_Energiemenge_Laden_XIX_OBG_01_XIX_HCP5_CANFD01: start 38, 14 bit, little-endian, data-type-policy=OVERRIDE, i-signal-type=PRIMITIVE, init-value=0, base-type=BT_HVLE_Energiemenge_Laden, compu-method=CM_HVLE_Energiemenge_Laden, data-constr=DC_HVLE_Energiemenge_Laden, unit=Unit_Unit_WattHour, transfer-property=PENDING  # Energiemenge, die von dem Ladegeraet ueber einen definierten Zeitraum an das Fahrzeug geliefert wurde
          signal HVLE_I_istAC_Netz_L1_XIX_OBG_01_XIX_HCP5_CANFD01: start 52, 9 bit, little-endian, data-type-policy=OVERRIDE, i-signal-type=PRIMITIVE, init-value=510, base-type=BT_HVLE_I_istAC_Netz_L1, invalid-value=Invalid_HVLE_I_istAC_Netz_L1_XIX_OBG_01_XIX_HCP5_CANFD01:511, compu-method=CM_HVLE_I_istAC_Netz_L1, data-constr=DC_HVLE_I_istAC_Netz_L1, unit=Unit_Unit_Amper, transfer-property=PENDING  # aktueller AC-Iststrom am Eingangskreis Phase 1 des Ladegeraet
          signal HVLE_I_istAC_Netz_L2_XIX_OBG_01_XIX_HCP5_CANFD01: start 61, 9 bit, little-endian, data-type-policy=OVERRIDE, i-signal-type=PRIMITIVE, init-value=510, base-type=BT_HVLE_I_istAC_Netz_L2, invalid-value=Invalid_HVLE_I_istAC_Netz_L2_XIX_OBG_01_XIX_HCP5_CANFD01:511, compu-method=CM_HVLE_I_istAC_Netz_L2, data-constr=DC_HVLE_I_istAC_Netz_L2, unit=Unit_Unit_Amper, transfer-property=PENDING  # aktueller AC-Iststrom am Eingangskreis Phase 2 des Ladegeraet
          signal HVLE_I_istAC_Netz_L3_XIX_OBG_01_XIX_HCP5_CANFD01: start 70, 9 bit, little-endian, data-type-policy=OVERRIDE, i-signal-type=PRIMITIVE, init-value=510, base-type=BT_HVLE_I_istAC_Netz_L3, invalid-value=Invalid_HVLE_I_istAC_Netz_L3_XIX_OBG_01_XIX_HCP5_CANFD01:511, compu-method=CM_HVLE_I_istAC_Netz_L3, data-constr=DC_HVLE_I_istAC_Netz_L3, unit=Unit_Unit_Amper, transfer-property=PENDING  # aktueller AC-Iststrom am Eingangskreis Phase 3 des Ladegeraet
          signal HVLE_U_istAC_Netz_L1_XIX_OBG_01_XIX_HCP5_CANFD01: start 79, 9 bit, little-endian, data-type-policy=OVERRIDE, i-signal-type=PRIMITIVE, init-value=510, base-type=BT_HVLE_U_istAC_Netz_L1, invalid-value=Invalid_HVLE_U_istAC_Netz_L1_XIX_OBG_01_XIX_HCP5_CANFD01:511, compu-method=CM_HVLE_U_istAC_Netz_L1, data-constr=DC_HVLE_U_istAC_Netz_L1, unit=Unit_Unit_Volt, transfer-property=PENDING  # aktuelle AC-Istspannung am Eingangskreis Phase 1 des Ladegeraet
          signal HVLE_U_istAC_Netz_L2_XIX_OBG_01_XIX_HCP5_CANFD01: start 88, 9 bit, little-endian, data-type-policy=OVERRIDE, i-signal-type=PRIMITIVE, init-value=510, base-type=BT_HVLE_U_istAC_Netz_L2, invalid-value=Invalid_HVLE_U_istAC_Netz_L2_XIX_OBG_01_XIX_HCP5_CANFD01:511, compu-method=CM_HVLE_U_istAC_Netz_L2, data-constr=DC_HVLE_U_istAC_Netz_L2, unit=Unit_Unit_Volt, transfer-property=PENDING  # aktuelle AC-Istspannung am Eingangskreis Phase 2 des Ladegeraet
          signal HVLE_U_istAC_Netz_L3_XIX_OBG_01_XIX_HCP5_CANFD01: start 97, 9 bit, little-endian, data-type-policy=OVERRIDE, i-signal-type=PRIMITIVE, init-value=510, base-type=BT_HVLE_U_istAC_Netz_L3, invalid-value=Invalid_HVLE_U_istAC_Netz_L3_XIX_OBG_01_XIX_HCP5_CANFD01:511, compu-method=CM_HVLE_U_istAC_Netz_L3, data-constr=DC_HVLE_U_istAC_Netz_L3, unit=Unit_Unit_Volt, transfer-property=PENDING  # aktuelle AC-Istspannung am Eingangskreis Phase 3 des Ladegeraet
          signal HVLE_OBG_DC_MaxStrom_XIX_OBG_01_XIX_HCP5_CANFD01: start 106, 11 bit, little-endian, data-type-policy=OVERRIDE, i-signal-type=PRIMITIVE, init-value=2046, base-type=BT_HVLE_OBG_DC_MaxStrom, invalid-value=Invalid_HVLE_OBG_DC_MaxStrom_XIX_OBG_01_XIX_HCP5_CANFD01:2047, compu-method=CM_HVLE_OBG_DC_MaxStrom, data-constr=DC_HVLE_OBG_DC_MaxStrom, unit=Unit_Unit_Amper, transfer-property=PENDING  # maximaler Strom den das Ladegeraet bei der aktuellen Spannungslage und des vorgegebenen AC-Aufnahmenstrom stellen kann
          signal HVLE_OBG_DC_IstStrom_XIX_OBG_01_XIX_HCP5_CANFD01: start 117, 11 bit, little-endian, data-type-policy=OVERRIDE, i-signal-type=PRIMITIVE, init-value=2046, base-type=BT_HVLE_OBG_DC_IstStrom, invalid-value=Invalid_HVLE_OBG_DC_IstStrom_XIX_OBG_01_XIX_HCP5_CANFD01:2047, compu-method=CM_HVLE_OBG_DC_IstStrom, data-constr=DC_HVLE_OBG_DC_IstStrom, unit=Unit_Unit_Amper, transfer-property=PENDING  # aktueller Iststrom des OCC
          signal HVLE_Netzmodus_XIX_OBG_01_XIX_HCP5_CANFD01: start 128, 4 bit, little-endian, data-type-policy=OVERRIDE, i-signal-type=PRIMITIVE, init-value=0, base-type=BT_HVLE_Netzmodus, invalid-value=Invalid_HVLE_Netzmodus_XIX_OBG_01_XIX_HCP5_CANFD01:15, compu-method=CM_HVLE_Netzmodus, data-constr=DC_HVLE_Netzmodus, transfer-property=PENDING  # Das Ladegeraet signalisiert hier den aktuellen Netzmodus. (1-phasig, 2-phasig, 3phasig, usw.)
          signal HVLE_Derating_Temperatur_XIX_OBG_01_XIX_HCP5_CANFD01: start 132, 1 bit, little-endian, data-type-policy=OVERRIDE, i-signal-type=PRIMITIVE, init-value=0, base-type=BT_HVLE_Derating_Temperatur, compu-method=CM_HVLE_Derating_Temperatur, data-constr=DC_HVLE_Derating_Temperatur, transfer-property=PENDING  # Derating-Status aufgrund von Temperaturbegrenzungen des Ladegeraet
          signal HVLE_OBG_IstModus_XIX_OBG_01_XIX_HCP5_CANFD01: start 133, 3 bit, little-endian, data-type-policy=OVERRIDE, i-signal-type=PRIMITIVE, init-value=6, base-type=BT_HVLE_OBG_IstModus, invalid-value=Invalid_HVLE_OBG_IstModus_XIX_OBG_01_XIX_HCP5_CANFD01:7, compu-method=CM_HVLE_OBG_IstModus, data-constr=DC_HVLE_OBG_IstModus, transfer-property=PENDING, to BMC_HV(timeout 1 s)  # aktueller Funktionszustand des Ladegeraet
          signal HVLE_OBG_Warnzustand_XIX_OBG_01_XIX_HCP5_CANFD01: start 136, 4 bit, little-endian, data-type-policy=OVERRIDE, i-signal-type=PRIMITIVE, init-value=0, base-type=BT_HVLE_OBG_Warnzustand, compu-method=CM_HVLE_OBG_Warnzustand, data-constr=DC_HVLE_OBG_Warnzustand, transfer-property=PENDING  # Zeigt an, ob eine Warnung für das Ladegerät aufgetreten ist.
          signal HVLE_OBG_Fehlerstatus_XIX_OBG_01_XIX_HCP5_CANFD01: start 140, 1 bit, little-endian, data-type-policy=OVERRIDE, i-signal-type=PRIMITIVE, init-value=0, base-type=BT_HVLE_OBG_Fehlerstatus, compu-method=CM_HVLE_OBG_Fehlerstatus, data-constr=DC_HVLE_OBG_Fehlerstatus, transfer-property=PENDING  # Gibt an, ob bei dem Ladegerät ein Fehler anliegt.
          signal HVLE_OBG_Fehlerstrom_XIX_OBG_01_XIX_HCP5_CANFD01: start 143, 1 bit, little-endian, data-type-policy=OVERRIDE, i-signal-type=PRIMITIVE, init-value=0, base-type=BT_HVLE_OBG_Fehlerstrom, compu-method=CM_HVLE_OBG_Fehlerstrom, data-constr=DC_HVLE_OBG_Fehlerstrom, transfer-property=PENDING  # Fehlerstrom der durch einen Isolationsfehler (z.B. schadhafte Isolierung, Berührung) vom Betriebsmittel zum Erdungssystem abfließt. Dies können hier AC- oder DC-Ströme sein.
          signal HVLE_OBG_ACDC_IstLeistung_XIX_OBG_01_XIX_HCP5_CANFD01: start 144, 11 bit, little-endian, data-type-policy=OVERRIDE, i-signal-type=PRIMITIVE, init-value=2046, base-type=BT_HVLE_OBG_ACDC_IstLeistung, invalid-value=Invalid_HVLE_OBG_ACDC_IstLeistung_XIX_OBG_01_XIX_HCP5_CANFD01:2047, compu-method=CM_HVLE_OBG_ACDC_IstLeistung, data-constr=DC_HVLE_OBG_ACDC_IstLeistung, unit=Unit_Unit_Watt, transfer-property=PENDING  # Aktuelle Ist-Leistung des Onboardgleichrichters nach der AC-DC-Umwandlung inkl. Verluste des Wirkungsgrades
          signal HVLE_OBG_ACDC_MaxLeistung_XIX_OBG_01_XIX_HCP5_CANFD01: start 155, 11 bit, little-endian, data-type-policy=OVERRIDE, i-signal-type=PRIMITIVE, init-value=2046, base-type=BT_HVLE_OBG_ACDC_MaxLeistung, invalid-value=Invalid_HVLE_OBG_ACDC_MaxLeistung_XIX_OBG_01_XIX_HCP5_CANFD01:2047, compu-method=CM_HVLE_OBG_ACDC_MaxLeistung, data-constr=DC_HVLE_OBG_ACDC_MaxLeistung, unit=Unit_Unit_Watt, transfer-property=PENDING  # Maximale mögliche Leistung des Onboardgleichrichters nach der AC-DC-Umwandlung inkl. Verluste des Wirkungsgrades
          signal HVLE_OBG_AC_maxStrom_XIX_OBG_01_XIX_HCP5_CANFD01: start 166, 10 bit, little-endian, data-type-policy=OVERRIDE, i-signal-type=PRIMITIVE, init-value=1022, base-type=BT_HVLE_OBG_AC_maxStrom, invalid-value=Invalid_HVLE_OBG_AC_maxStrom_XIX_OBG_01_XIX_HCP5_CANFD01:1023, compu-method=CM_HVLE_OBG_AC_maxStrom, data-constr=DC_HVLE_OBG_AC_maxStrom, unit=Unit_Unit_Amper, transfer-property=PENDING  # auteiltechnischer Grenzwert des maximalen Stroms pro Phase welches vom Ladegerät unterstützt wird.
          signal HVLE_OBG_AC_maxSpannung_XIX_OBG_01_XIX_HCP5_CANFD01: start 176, 10 bit, little-endian, data-type-policy=OVERRIDE, i-signal-type=PRIMITIVE, init-value=1022, base-type=BT_HVLE_OBG_AC_maxSpannung, invalid-value=Invalid_HVLE_OBG_AC_maxSpannung_XIX_OBG_01_XIX_HCP5_CANFD01:1023, compu-method=CM_HVLE_OBG_AC_maxSpannung, data-constr=DC_HVLE_OBG_AC_maxSpannung, unit=Unit_Unit_Volt, transfer-property=PENDING  # Bauteiltechnischer Grenzwert der maximalen nominellen Spannung gemessen zwischen Phase und Neutral.
          signal HVLE_AnzahlVerwendeterPhasen_XIX_OBG_01_XIX_HCP5_CANFD01: start 186, 2 bit, little-endian, data-type-policy=OVERRIDE, i-signal-type=PRIMITIVE, init-value=0, base-type=BT_HVLE_AnzahlVerwendeterPhasen, invalid-value=Invalid_HVLE_AnzahlVerwendeterPhasen_XIX_OBG_01_XIX_HCP5_CANFD01:3, compu-method=CM_HVLE_AnzahlVerwendeterPhasen, data-constr=DC_HVLE_AnzahlVerwendeterPhasen, transfer-property=PENDING  # Gibt die Anzahl der verwendeten Phasen für das AC Laden an
          signal HVLE_AsymmetrischLadenMoeglich_XIX_OBG_01_XIX_HCP5_CANFD01: start 188, 1 bit, little-endian, data-type-policy=OVERRIDE, i-signal-type=PRIMITIVE, init-value=0, base-type=BT_HVLE_AsymmetrischLadenMoeglich, compu-method=CM_HVLE_AsymmetrischLadenMoeglich, data-constr=DC_HVLE_AsymmetrischLadenMoeglich, transfer-property=PENDING  # Information ob das Ladegerät ein asymetrisches Laden bauartbedingt unterstützt
          signal HVLE_OBG_Typ_verbaut_XIX_OBG_01_XIX_HCP5_CANFD01: start 189, 3 bit, little-endian, data-type-policy=OVERRIDE, i-signal-type=PRIMITIVE, init-value=7, base-type=BT_HVLE_OBG_Typ_verbaut, compu-method=CM_HVLE_OBG_Typ_verbaut, data-constr=DC_HVLE_OBG_Typ_verbaut, transfer-property=PENDING  # Typ des verbauten Onboard-Gleichrichters
          signal HVLE_PE_Monitor_XIX_OBG_01_XIX_HCP5_CANFD01: start 192, 3 bit, little-endian, data-type-policy=OVERRIDE, i-signal-type=PRIMITIVE, init-value=0, base-type=BT_HVLE_PE_Monitor, invalid-value=Invalid_HVLE_PE_Monitor_XIX_OBG_01_XIX_HCP5_CANFD01:7, compu-method=CM_HVLE_PE_Monitor, data-constr=DC_HVLE_PE_Monitor, transfer-property=PENDING  # Messung des PE-Leiters der Infrastruktur bei galvanisch nicht getrennten Onboard Gleichrichtern.
      frame ORU_01_XIX_HCP5_CANFD01: id 0x1A555548, to BMC_HV, frame-length=8, can-addressing-mode=EXTENDED, can-frame-rx-behavior=CAN-FD, can-frame-tx-behavior=CAN-FD
        pdu ORU_01_XIX_HCP5_CANFD01: length=8, transmission-mode-true-timing=cyclic-timing={time-offset=0, time-period=0.5}, unused-bit-pattern=0
          signal ORU_AgLgtSdsl_XIX_ORU_01_XIX_HCP5_CANFD01: start 12, 11 bit, little-endian, data-type-policy=OVERRIDE, i-signal-type=PRIMITIVE, init-value=2001, base-type=BT_ORU_AgLgtSdsl, invalid-value=Invalid_ORU_AgLgtSdsl_XIX_ORU_01_XIX_HCP5_CANFD01:2002, compu-method=CM_ORU_AgLgtSdsl, data-constr=DC_ORU_AgLgtSdsl, unit=Unit_Unit_PerCent, transfer-property=PENDING  # Vehicle inclination angle at standstill in percent
          signal ORU_Status_XIX_ORU_01_XIX_HCP5_CANFD01: start 61, 3 bit, little-endian, data-type-policy=OVERRIDE, i-signal-type=PRIMITIVE, init-value=0, base-type=BT_ORU_Status, compu-method=CM_ORU_Status, data-constr=DC_ORU_Status, transfer-property=PENDING, to BMC_HV(timeout 5 s)  # Verteilung des internen ORU Zustandes
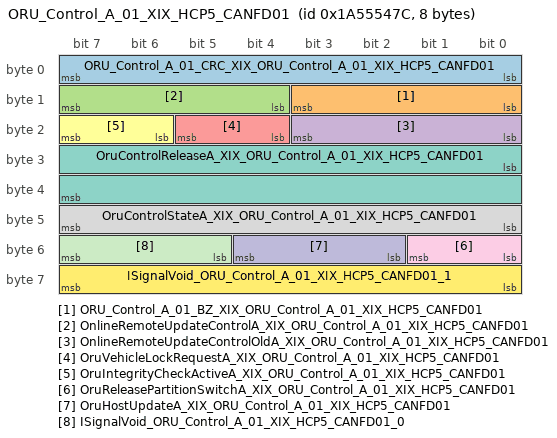
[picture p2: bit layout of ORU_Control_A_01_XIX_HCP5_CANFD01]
      frame ORU_Control_A_01_XIX_HCP5_CANFD01: id 0x1A55547C, to BMC_HV, frame-length=8, can-addressing-mode=EXTENDED, can-frame-rx-behavior=CAN-FD, can-frame-tx-behavior=CAN-FD
        pdu ORU_Control_A_01_XIX_HCP5_CANFD01_E2E: length=8, transmission-mode-true-timing=event-controlled-timing={number-of-repetitions=0, repetition-period=0}, unused-bit-pattern=0  # Fuer die Botschaft ist das Cyclic-Timing 0.5 zu verwenden.
          signal ORU_Control_A_01_CRC_XIX_ORU_Control_A_01_XIX_HCP5_CANFD01: start 0, 8 bit, little-endian, data-type-policy=OVERRIDE, i-signal-type=PRIMITIVE, init-value=0, base-type=BT_ORU_Control_A_01_CRC, compu-method=CM_ORU_Control_A_01_CRC, data-constr=DC_ORU_Control_A_01_CRC, to BMC_HV(timeout 5 s)
          signal ORU_Control_A_01_BZ_XIX_ORU_Control_A_01_XIX_HCP5_CANFD01: start 8, 4 bit, little-endian, data-type-policy=OVERRIDE, i-signal-type=PRIMITIVE, init-value=0, base-type=BT_ORU_Control_A_01_BZ, compu-method=CM_ORU_Control_A_01_BZ, data-constr=DC_ORU_Control_A_01_BZ, to BMC_HV(timeout 5 s)
          signal OnlineRemoteUpdateControlA_XIX_ORU_Control_A_01_XIX_HCP5_CANFD01: start 12, 4 bit, little-endian, data-type-policy=OVERRIDE, i-signal-type=PRIMITIVE, init-value=0, base-type=BT_OnlineRemoteUpdateControlA, invalid-value=Invalid_OnlineRemoteUpdateControlA_XIX_ORU_Control_A_01_XIX_HCP5_CANFD01:15, compu-method=CM_OnlineRemoteUpdateControlA, data-constr=DC_OnlineRemoteUpdateControlA, to BMC_HV(timeout 5 s)  # Current state of the oru control component
          signal OnlineRemoteUpdateControlOldA_XIX_ORU_Control_A_01_XIX_HCP5_CANFD01: start 16, 4 bit, little-endian, data-type-policy=OVERRIDE, i-signal-type=PRIMITIVE, init-value=0, base-type=BT_OnlineRemoteUpdateControlOldA, invalid-value=Invalid_OnlineRemoteUpdateControlOldA_XIX_ORU_Control_A_01_XIX_HCP5_CANFD01:15, compu-method=CM_OnlineRemoteUpdateControlOldA, data-constr=DC_OnlineRemoteUpdateControlOldA, to BMC_HV(timeout 5 s)  # Old state of the ORU control A signal (state 5 cycles before)
          signal OruVehicleLockRequestA_XIX_ORU_Control_A_01_XIX_HCP5_CANFD01: start 20, 2 bit, little-endian, data-type-policy=OVERRIDE, i-signal-type=PRIMITIVE, init-value=0, base-type=BT_OruVehicleLockRequestA, invalid-value=Invalid_OruVehicleLockRequestA_XIX_ORU_Control_A_01_XIX_HCP5_CANFD01:3, compu-method=CM_OruVehicleLockRequestA, data-constr=DC_OruVehicleLockRequestA  # Releases or locks one or more ECUs with their specific functions (e.g. immobilizer)
          signal OruIntegrityCheckActiveA_XIX_ORU_Control_A_01_XIX_HCP5_CANFD01: start 22, 2 bit, little-endian, data-type-policy=OVERRIDE, i-signal-type=PRIMITIVE, init-value=0, base-type=BT_OruIntegrityCheckActiveA, invalid-value=Invalid_OruIntegrityCheckActiveA_XIX_ORU_Control_A_01_XIX_HCP5_CANFD01:3, compu-method=CM_OruIntegrityCheckActiveA, data-constr=DC_OruIntegrityCheckActiveA  # Signal to indicate if the integrity check is active
          signal OruControlReleaseA_XIX_ORU_Control_A_01_XIX_HCP5_CANFD01: start 24, 16 bit, little-endian, data-type-policy=OVERRIDE, i-signal-type=PRIMITIVE, init-value=0, base-type=BT_OruControlReleaseA, compu-method=CM_OruControlReleaseA, data-constr=DC_OruControlReleaseA, unit=Unit_Unit_None, to BMC_HV(timeout 5 s)  # Release of an ecu to be flashed by oru
          signal OruControlStateA_XIX_ORU_Control_A_01_XIX_HCP5_CANFD01: start 40, 8 bit, little-endian, data-type-policy=OVERRIDE, i-signal-type=PRIMITIVE, init-value=0, base-type=BT_OruControlStateA, invalid-value=Invalid_OruControlStateA_XIX_ORU_Control_A_01_XIX_HCP5_CANFD01:129, compu-method=CM_OruControlStateA, data-constr=DC_OruControlStateA  # Internal State of ORU Control component.
          signal OruReleasePartitionSwitchA_XIX_ORU_Control_A_01_XIX_HCP5_CANFD01: start 48, 2 bit, little-endian, data-type-policy=OVERRIDE, i-signal-type=PRIMITIVE, init-value=0, base-type=BT_OruReleasePartitionSwitchA, invalid-value=Invalid_OruReleasePartitionSwitchA_XIX_ORU_Control_A_01_XIX_HCP5_CANFD01:3, compu-method=CM_OruReleasePartitionSwitchA, data-constr=DC_OruReleasePartitionSwitchA  # Release to switch the partition in case of an A/B partition update
          signal OruHostUpdateA_XIX_ORU_Control_A_01_XIX_HCP5_CANFD01: start 50, 3 bit, little-endian, data-type-policy=OVERRIDE, i-signal-type=PRIMITIVE, init-value=0, base-type=BT_OruHostUpdateA, invalid-value=Invalid_OruHostUpdateA_XIX_ORU_Control_A_01_XIX_HCP5_CANFD01:4, compu-method=CM_OruHostUpdateA, data-constr=DC_OruHostUpdateA  # Releases an update of an critical funcion's host (due to functional safety)
          signal ISignalVoid_ORU_Control_A_01_XIX_HCP5_CANFD01_0: start 53, 3 bit, little-endian, system signal SignalVoid_ORU_Control_A_01_0, data-type-policy=OVERRIDE, i-signal-type=PRIMITIVE, base-type=BT_SignalVoid
          signal ISignalVoid_ORU_Control_A_01_XIX_HCP5_CANFD01_1: start 56, 8 bit, little-endian, system signal SignalVoid_ORU_Control_A_01_1, data-type-policy=OVERRIDE, i-signal-type=PRIMITIVE, base-type=BT_SignalVoid
          mapping SG_ORU_Control_A_01_XIX_HCP5_CANFD01: i-signal-group=SG_ORU_Control_A_01_XIX_HCP5_CANFD01, transfer-property=TRIGGERED-WITHOUT-REPETITION
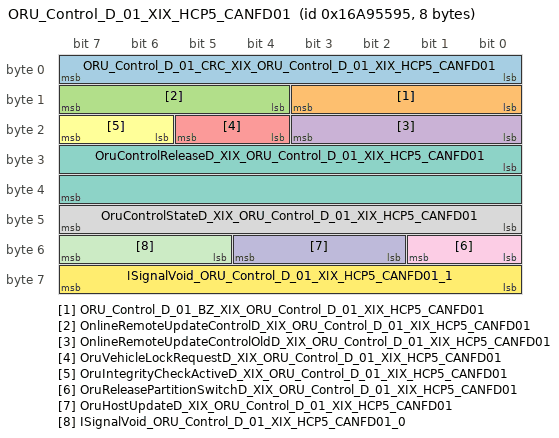
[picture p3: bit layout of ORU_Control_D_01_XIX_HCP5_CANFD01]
      frame ORU_Control_D_01_XIX_HCP5_CANFD01: id 0x16A95595, to BMC_HV, frame-length=8, can-addressing-mode=EXTENDED, can-frame-rx-behavior=CAN-FD, can-frame-tx-behavior=CAN-FD
        pdu ORU_Control_D_01_XIX_HCP5_CANFD01_E2E: length=8, transmission-mode-true-timing=event-controlled-timing={number-of-repetitions=0, repetition-period=0}, unused-bit-pattern=0  # Fuer die Botschaft ist das Cyclic-Timing 0.32 zu verwenden.
          signal ORU_Control_D_01_CRC_XIX_ORU_Control_D_01_XIX_HCP5_CANFD01: start 0, 8 bit, little-endian, data-type-policy=OVERRIDE, i-signal-type=PRIMITIVE, init-value=0, base-type=BT_ORU_Control_D_01_CRC, compu-method=CM_ORU_Control_D_01_CRC, data-constr=DC_ORU_Control_D_01_CRC, to BMC_HV(timeout 3.2 s)
          signal ORU_Control_D_01_BZ_XIX_ORU_Control_D_01_XIX_HCP5_CANFD01: start 8, 4 bit, little-endian, data-type-policy=OVERRIDE, i-signal-type=PRIMITIVE, init-value=0, base-type=BT_ORU_Control_D_01_BZ, compu-method=CM_ORU_Control_D_01_BZ, data-constr=DC_ORU_Control_D_01_BZ, to BMC_HV(timeout 3.2 s)
          signal OnlineRemoteUpdateControlD_XIX_ORU_Control_D_01_XIX_HCP5_CANFD01: start 12, 4 bit, little-endian, data-type-policy=OVERRIDE, i-signal-type=PRIMITIVE, init-value=0, base-type=BT_OnlineRemoteUpdateControlD, invalid-value=Invalid_OnlineRemoteUpdateControlD_XIX_ORU_Control_D_01_XIX_HCP5_CANFD01:15, compu-method=CM_OnlineRemoteUpdateControlD, data-constr=DC_OnlineRemoteUpdateControlD, to BMC_HV(timeout 3.2 s)  # This signal is part of the ORU functional safety concept to inform ECUs, if an update is possible
          signal OnlineRemoteUpdateControlOldD_XIX_ORU_Control_D_01_XIX_HCP5_CANFD01: start 16, 4 bit, little-endian, data-type-policy=OVERRIDE, i-signal-type=PRIMITIVE, init-value=0, base-type=BT_OnlineRemoteUpdateControlOldD, invalid-value=Invalid_OnlineRemoteUpdateControlOldD_XIX_ORU_Control_D_01_XIX_HCP5_CANFD01:15, compu-method=CM_OnlineRemoteUpdateControlOldD, data-constr=DC_OnlineRemoteUpdateControlOldD, to BMC_HV(timeout 3.2 s)  # Old state of the ORU control C component (state as of 5 previous cycles)
          signal OruVehicleLockRequestD_XIX_ORU_Control_D_01_XIX_HCP5_CANFD01: start 20, 2 bit, little-endian, data-type-policy=OVERRIDE, i-signal-type=PRIMITIVE, init-value=0, base-type=BT_OruVehicleLockRequestD, invalid-value=Invalid_OruVehicleLockRequestD_XIX_ORU_Control_D_01_XIX_HCP5_CANFD01:3, compu-method=CM_OruVehicleLockRequestD, data-constr=DC_OruVehicleLockRequestD  # Releases or locks one or more ECUs with their specific functions (e.g. immobilizer)
          signal OruIntegrityCheckActiveD_XIX_ORU_Control_D_01_XIX_HCP5_CANFD01: start 22, 2 bit, little-endian, data-type-policy=OVERRIDE, i-signal-type=PRIMITIVE, init-value=0, base-type=BT_OruIntegrityCheckActiveD, invalid-value=Invalid_OruIntegrityCheckActiveD_XIX_ORU_Control_D_01_XIX_HCP5_CANFD01:3, compu-method=CM_OruIntegrityCheckActiveD, data-constr=DC_OruIntegrityCheckActiveD  # Signal to indicate if the integrity check is active
          signal OruControlReleaseD_XIX_ORU_Control_D_01_XIX_HCP5_CANFD01: start 24, 16 bit, little-endian, data-type-policy=OVERRIDE, i-signal-type=PRIMITIVE, init-value=0, base-type=BT_OruControlReleaseD, compu-method=CM_OruControlReleaseD, data-constr=DC_OruControlReleaseD, unit=Unit_Unit_None, to BMC_HV(timeout 3.2 s)  # This signal is used to allow an ECU to start an update session. As this is a critical point, 2 components have to approve this
          signal OruControlStateD_XIX_ORU_Control_D_01_XIX_HCP5_CANFD01: start 40, 8 bit, little-endian, data-type-policy=OVERRIDE, i-signal-type=PRIMITIVE, init-value=0, base-type=BT_OruControlStateD, invalid-value=Invalid_OruControlStateD_XIX_ORU_Control_D_01_XIX_HCP5_CANFD01:129, compu-method=CM_OruControlStateD, data-constr=DC_OruControlStateD  # This signal is used to allow an ECU to start an update session.
          signal OruReleasePartitionSwitchD_XIX_ORU_Control_D_01_XIX_HCP5_CANFD01: start 48, 2 bit, little-endian, data-type-policy=OVERRIDE, i-signal-type=PRIMITIVE, init-value=0, base-type=BT_OruReleasePartitionSwitchD, invalid-value=Invalid_OruReleasePartitionSwitchD_XIX_ORU_Control_D_01_XIX_HCP5_CANFD01:3, compu-method=CM_OruReleasePartitionSwitchD, data-constr=DC_OruReleasePartitionSwitchD  # Release to switch the partition in case of an A/B partition update
          signal OruHostUpdateD_XIX_ORU_Control_D_01_XIX_HCP5_CANFD01: start 50, 3 bit, little-endian, data-type-policy=OVERRIDE, i-signal-type=PRIMITIVE, init-value=0, base-type=BT_OruHostUpdateD, invalid-value=Invalid_OruHostUpdateD_XIX_ORU_Control_D_01_XIX_HCP5_CANFD01:4, compu-method=CM_OruHostUpdateD, data-constr=DC_OruHostUpdateD  # Releases an update of an critical funcion's host (due to functional safety)
          signal ISignalVoid_ORU_Control_D_01_XIX_HCP5_CANFD01_0: start 53, 3 bit, little-endian, system signal SignalVoid_ORU_Control_D_01_0, data-type-policy=OVERRIDE, i-signal-type=PRIMITIVE, base-type=BT_SignalVoid
          signal ISignalVoid_ORU_Control_D_01_XIX_HCP5_CANFD01_1: start 56, 8 bit, little-endian, system signal SignalVoid_ORU_Control_D_01_1, data-type-policy=OVERRIDE, i-signal-type=PRIMITIVE, base-type=BT_SignalVoid
          mapping SG_ORU_Control_D_01_XIX_HCP5_CANFD01: i-signal-group=SG_ORU_Control_D_01_XIX_HCP5_CANFD01, transfer-property=TRIGGERED-WITHOUT-REPETITION
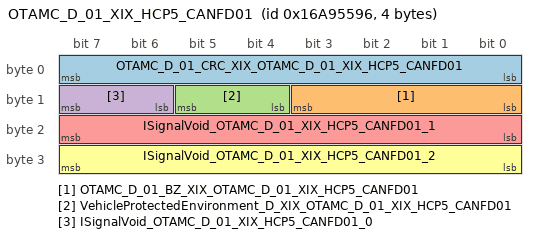
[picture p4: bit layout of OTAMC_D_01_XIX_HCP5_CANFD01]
      frame OTAMC_D_01_XIX_HCP5_CANFD01: id 0x16A95596, to BMC_HV, frame-length=4, can-addressing-mode=EXTENDED, can-frame-rx-behavior=CAN-FD, can-frame-tx-behavior=CAN-FD
        pdu OTAMC_D_01_XIX_HCP5_CANFD01_E2E: length=4, transmission-mode-true-timing=event-controlled-timing={number-of-repetitions=0, repetition-period=0}, unused-bit-pattern=0  # Fuer die Botschaft ist das Cyclic-Timing 0.32 zu verwenden.
          signal OTAMC_D_01_CRC_XIX_OTAMC_D_01_XIX_HCP5_CANFD01: start 0, 8 bit, little-endian, data-type-policy=OVERRIDE, i-signal-type=PRIMITIVE, init-value=0, base-type=BT_OTAMC_D_01_CRC, compu-method=CM_OTAMC_D_01_CRC, data-constr=DC_OTAMC_D_01_CRC, to BMC_HV(timeout 3.2 s)
          signal OTAMC_D_01_BZ_XIX_OTAMC_D_01_XIX_HCP5_CANFD01: start 8, 4 bit, little-endian, data-type-policy=OVERRIDE, i-signal-type=PRIMITIVE, init-value=0, base-type=BT_OTAMC_D_01_BZ, compu-method=CM_OTAMC_D_01_BZ, data-constr=DC_OTAMC_D_01_BZ, to BMC_HV(timeout 3.2 s)
          signal VehicleProtectedEnvironment_D_XIX_OTAMC_D_01_XIX_HCP5_CANFD01: start 12, 2 bit, little-endian, data-type-policy=OVERRIDE, i-signal-type=PRIMITIVE, init-value=0, base-type=BT_VehicleProtectedEnvironment_D, compu-method=CM_VehicleProtectedEnvironment_D, data-constr=DC_VehicleProtectedEnvironment_D, to BMC_HV(timeout 3.2 s)  # Environment of vehicle in case of Remote Production
          signal ISignalVoid_OTAMC_D_01_XIX_HCP5_CANFD01_0: start 14, 2 bit, little-endian, system signal SignalVoid_OTAMC_D_01_0, data-type-policy=OVERRIDE, i-signal-type=PRIMITIVE, base-type=BT_SignalVoid
          signal ISignalVoid_OTAMC_D_01_XIX_HCP5_CANFD01_1: start 16, 8 bit, little-endian, system signal SignalVoid_OTAMC_D_01_1, data-type-policy=OVERRIDE, i-signal-type=PRIMITIVE, base-type=BT_SignalVoid
          signal ISignalVoid_OTAMC_D_01_XIX_HCP5_CANFD01_2: start 24, 8 bit, little-endian, system signal SignalVoid_OTAMC_D_01_2, data-type-policy=OVERRIDE, i-signal-type=PRIMITIVE, base-type=BT_SignalVoid
          mapping SG_OTAMC_D_01_XIX_HCP5_CANFD01: i-signal-group=SG_OTAMC_D_01_XIX_HCP5_CANFD01, transfer-property=TRIGGERED-WITHOUT-REPETITION
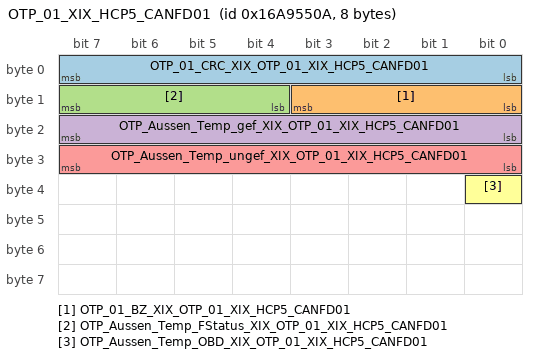
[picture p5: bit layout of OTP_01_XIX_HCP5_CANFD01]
      frame OTP_01_XIX_HCP5_CANFD01: id 0x16A9550A, to BMC_HV, frame-length=8, can-addressing-mode=EXTENDED, can-frame-rx-behavior=CAN-FD, can-frame-tx-behavior=CAN-FD
        pdu OTP_01_XIX_HCP5_CANFD01: length=8, transmission-mode-true-timing=cyclic-timing={time-offset=0, time-period=0.2}, unused-bit-pattern=0
          signal OTP_01_CRC_XIX_OTP_01_XIX_HCP5_CANFD01: start 0, 8 bit, little-endian, data-type-policy=OVERRIDE, i-signal-type=PRIMITIVE, init-value=0, base-type=BT_OTP_01_CRC, compu-method=CM_OTP_01_CRC, data-constr=DC_OTP_01_CRC, transfer-property=PENDING  # Für MLB: Berechnung siehe Lastenheft "Kommunikationsabsicherung für FlexRay und CAN" Ab MQB und MLBevo: Berechnung siehe Lastenheft "End-to-End Kommunikationsabsicherung" Endwerte siehe Begleitdokument "S-PDU Kennungsfolgen"
          signal OTP_01_BZ_XIX_OTP_01_XIX_HCP5_CANFD01: start 8, 4 bit, little-endian, data-type-policy=OVERRIDE, i-signal-type=PRIMITIVE, init-value=0, base-type=BT_OTP_01_BZ, compu-method=CM_OTP_01_BZ, data-constr=DC_OTP_01_BZ, transfer-property=PENDING  # 4bit Botschaftszähler, wird mit jeder Sendebotschaft inkrementiert
          signal OTP_Aussen_Temp_FStatus_XIX_OTP_01_XIX_HCP5_CANFD01: start 12, 4 bit, little-endian, data-type-policy=OVERRIDE, i-signal-type=PRIMITIVE, init-value=0, base-type=BT_OTP_Aussen_Temp_FStatus, compu-method=CM_OTP_Aussen_Temp_FStatus, data-constr=DC_OTP_Aussen_Temp_FStatus, transfer-property=PENDING  # Fehlerstatus Umgebungstemperatursensor
          signal OTP_Aussen_Temp_gef_XIX_OTP_01_XIX_HCP5_CANFD01: start 16, 8 bit, little-endian, data-type-policy=OVERRIDE, i-signal-type=PRIMITIVE, init-value=254, base-type=BT_OTP_Aussen_Temp_gef, invalid-value=Invalid_OTP_Aussen_Temp_gef_XIX_OTP_01_XIX_HCP5_CANFD01:255, compu-method=CM_OTP_Aussen_Temp_gef, data-constr=DC_OTP_Aussen_Temp_gef, unit=Unit_Unit_DegreCelsi, transfer-property=PENDING  # Gefilterte Aussentemperatur. Es werden hier Einflüsse durch Abwärme ausgefiltert.
          signal OTP_Aussen_Temp_ungef_XIX_OTP_01_XIX_HCP5_CANFD01: start 24, 8 bit, little-endian, data-type-policy=OVERRIDE, i-signal-type=PRIMITIVE, init-value=254, base-type=BT_OTP_Aussen_Temp_ungef, invalid-value=Invalid_OTP_Aussen_Temp_ungef_XIX_OTP_01_XIX_HCP5_CANFD01:255, compu-method=CM_OTP_Aussen_Temp_ungef, data-constr=DC_OTP_Aussen_Temp_ungef, unit=Unit_Unit_DegreCelsi, transfer-property=PENDING, to BMC_HV(timeout 2 s)  # ungefilterter Wert des Aussentemperatursensors
          signal OTP_Aussen_Temp_OBD_XIX_OTP_01_XIX_HCP5_CANFD01: start 32, 1 bit, little-endian, data-type-policy=OVERRIDE, i-signal-type=PRIMITIVE, init-value=1, base-type=BT_OTP_Aussen_Temp_OBD, compu-method=CM_OTP_Aussen_Temp_OBD, data-constr=DC_OTP_Aussen_Temp_OBD, transfer-property=PENDING, to BMC_HV(timeout 2 s)  # OBD-QBit der Aussentemperatur. Gesetzt bei Ersatzwert, Init oder Fehler.
      frame SOK_NoAuthenticTime_01_XIX_HCP5_CANFD01: id 0x1A5555AC, to BMC_HV, frame-length=8, can-addressing-mode=EXTENDED, can-frame-rx-behavior=CAN-FD, can-frame-tx-behavior=CAN-FD
        pdu SOK_NoAuthenticTime_01_XIX_HCP5_CANFD01: length=8, transmission-mode-true-timing=event-controlled-timing={number-of-repetitions=0, repetition-period=0}, unused-bit-pattern=0
          signal SOK_ungeschuetzte_Zeit_XIX_SOK_NoAuthenticTime_01_XIX_HCP5_CANFD01: start 8, 56 bit, opaque, data-type-policy=OVERRIDE, i-signal-type=ARRAY, init-value=7 x 0, base-type=BT_SOK_ungeschuetzte_Zeit, compu-method=CM_SOK_ungeschuetzte_Zeit, data-constr=DC_SOK_ungeschuetzte_Zeit, unit=Unit_Unit_None, transfer-property=TRIGGERED-ON-CHANGE-WITHOUT-REPETITION, to BMC_HV  # Periodisch verschickter SOK Zeitwert des SOK Zeitmasters als Referenzzeit zur Erkennung von Clockjitter durch andere SOK Teilnehmer. Der Empfang dieses Signals ist verpflichtend für jedes Steuergerät, das durch die authentische Broadcast Funktionalität von SOK geschützte Daten versendet oder empfängt.
      frame SOK_Zeit_Hybrid_01_Chal_01_XIX_HCP5_CANFD01: id 0x12E0007B, from BMC_HV, frame-length=8, can-addressing-mode=EXTENDED, can-frame-rx-behavior=CAN-FD, can-frame-tx-behavior=CAN-FD
        pdu SOK_Zeit_Hybrid_01_Chal_01_XIX_HCP5_CANFD01: length=8, minimum-delay=0.1, transmission-mode-true-timing=event-controlled-timing={number-of-repetitions=0, repetition-period=0}, unused-bit-pattern=0
          signal SOK_Zeit_Hybrid_01_Challenge_XIX_SOK_Zeit_Hybrid_01_Chal_01_XIX_HCP5_CANFD01: start 0, 64 bit, opaque, data-type-policy=OVERRIDE, i-signal-type=ARRAY, base-type=BT_SOK_Zeit_Hybrid_01_Challenge, compu-method=CM_SOK_Zeit_Hybrid_01_Challenge, data-constr=DC_SOK_Zeit_Hybrid_01_Challenge, unit=Unit_Unit_None, transfer-property=TRIGGERED-ON-CHANGE-WITHOUT-REPETITION  # Challenge of SOK participant BMC_HV to SOK time server for requesting authentic SOK time
      frame SOK_Zeit_Hybrid_01_Resp_01_SOK_XIX_HCP5_CANFD01: id 0x12E2007B, to BMC_HV, frame-length=16, can-addressing-mode=EXTENDED, can-frame-rx-behavior=CAN-FD, can-frame-tx-behavior=CAN-FD
        secured i pdu SOK_Zeit_Hybrid_01_Resp_01_SOK_XIX_HCP5_CANFD01:
          length=16
          authentication-props=SecureCommunicationAuthenticationProps_XIX_64
          freshness-props=SecureCommunicationFreshnessProps
          payload=PT_SOK_Zeit_Hybrid_01_Resp_01
          secure-communication-props={auth-data-freshness-length=0, auth-data-freshness-start-position=0, auth-info-tx-length=64, authentication-build-attempts=1, authentication-retries=1, data-id=402, freshness-value-id=0, freshness-value-length=64, freshness-value-tx-length=0}
          use-as-cryptographic-i-pdu=false
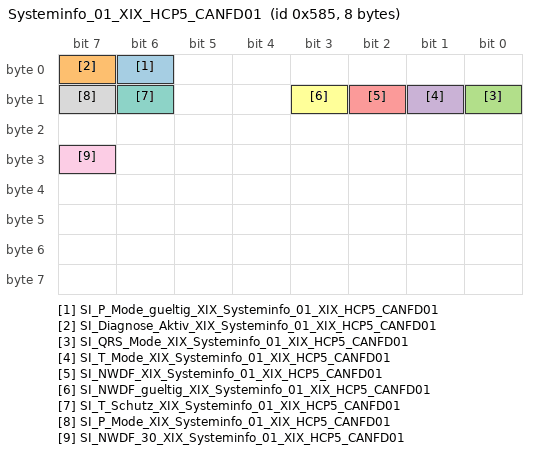
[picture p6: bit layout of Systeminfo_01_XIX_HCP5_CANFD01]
      frame Systeminfo_01_XIX_HCP5_CANFD01: id 0x585, to BMC_HV, frame-length=8, can-addressing-mode=STANDARD, can-frame-rx-behavior=CAN-FD, can-frame-tx-behavior=CAN-FD
        pdu Systeminfo_01_XIX_HCP5_CANFD01: length=8, minimum-delay=0.01, transmission-mode-true-timing={cyclic-timing={time-offset=0, time-period=1}, event-controlled-timing={number-of-repetitions=0, repetition-period=0}}, unused-bit-pattern=0  # MQB, MLBevo
          signal SI_P_Mode_gueltig_XIX_Systeminfo_01_XIX_HCP5_CANFD01: start 6, 1 bit, little-endian, data-type-policy=OVERRIDE, i-signal-type=PRIMITIVE, init-value=0, base-type=BT_SI_P_Mode_gueltig, compu-method=CM_SI_P_Mode_gueltig, data-constr=DC_SI_P_Mode_gueltig, transfer-property=PENDING, to BMC_HV(timeout 5 s)  # zeigt an, ob es sich um ein Fahrzeug mit zentraler oder dezentraler Steu-erung des Produktionsmodes handelt Siehe Q-LAH Produktionsmode (LAH.DUM.907.AS)
          signal SI_Diagnose_Aktiv_XIX_Systeminfo_01_XIX_HCP5_CANFD01: start 7, 1 bit, little-endian, data-type-policy=OVERRIDE, i-signal-type=PRIMITIVE, init-value=0, base-type=BT_SI_Diagnose_Aktiv, compu-method=CM_SI_Diagnose_Aktiv, data-constr=DC_SI_Diagnose_Aktiv, transfer-property=PENDING  # Gibt an ob Diagnose-Botschaften empfangen werden und somit eine Diagnose aktiv ist. MQB: Gibt an ob Diagnose-Bus Botschaften empfangen werden und somit eine Diagnose aktiv ist.
          signal SI_QRS_Mode_XIX_Systeminfo_01_XIX_HCP5_CANFD01: start 8, 1 bit, little-endian, data-type-policy=OVERRIDE, i-signal-type=PRIMITIVE, init-value=0, base-type=BT_SI_QRS_Mode, compu-method=CM_SI_QRS_Mode, data-constr=DC_SI_QRS_Mode, transfer-property=PENDING  # Messmodus Quick-Ruhestrom
          signal SI_T_Mode_XIX_Systeminfo_01_XIX_HCP5_CANFD01: start 9, 1 bit, little-endian, data-type-policy=OVERRIDE, i-signal-type=PRIMITIVE, init-value=0, base-type=BT_SI_T_Mode, compu-method=CM_SI_T_Mode, data-constr=DC_SI_T_Mode, transfer-property=PENDING, to BMC_HV(timeout 5 s)  # 0x0: Transportmodus nicht aktiv 0x1: Transportmodus aktiv
          signal SI_NWDF_XIX_Systeminfo_01_XIX_HCP5_CANFD01: start 10, 1 bit, little-endian, data-type-policy=OVERRIDE, i-signal-type=PRIMITIVE, init-value=0, base-type=BT_SI_NWDF, compu-method=CM_SI_NWDF, data-constr=DC_SI_NWDF, transfer-property=TRIGGERED-ON-CHANGE-WITHOUT-REPETITION, to BMC_HV(timeout 5 s)  # Netzwerk-Diagnose Freigebe zur zentralen Aktivierung der Netzwerkdiagnose
          signal SI_NWDF_gueltig_XIX_Systeminfo_01_XIX_HCP5_CANFD01: start 11, 1 bit, little-endian, data-type-policy=OVERRIDE, i-signal-type=PRIMITIVE, init-value=1, base-type=BT_SI_NWDF_gueltig, compu-method=CM_SI_NWDF_gueltig, data-constr=DC_SI_NWDF_gueltig, transfer-property=PENDING  # Gültigkeitsbit zu SI_NWDF gemäß Lastenheft: Zentrale Aktivierung Netzwerkdiagnose
          signal SI_T_Schutz_XIX_Systeminfo_01_XIX_HCP5_CANFD01: start 14, 1 bit, little-endian, data-type-policy=OVERRIDE, i-signal-type=PRIMITIVE, init-value=0, base-type=BT_SI_T_Schutz, compu-method=CM_SI_T_Schutz, data-constr=DC_SI_T_Schutz, transfer-property=PENDING  # Transportschutz-Signal, das bei Transportmodus und Motorlauf aktiv bleibt 0x0: Transportschutz nicht aktiv 0x1: Transportschutz aktiv
          signal SI_P_Mode_XIX_Systeminfo_01_XIX_HCP5_CANFD01: start 15, 1 bit, little-endian, data-type-policy=OVERRIDE, i-signal-type=PRIMITIVE, init-value=0, base-type=BT_SI_P_Mode, compu-method=CM_SI_P_Mode, data-constr=DC_SI_P_Mode, transfer-property=PENDING, to BMC_HV(timeout 5 s)  # Zentrale Steuerung des Produktionsmodes gemäß Q-LAH-Produktionsmode (LAH.DUM.907.AS)
          signal SI_NWDF_30_XIX_Systeminfo_01_XIX_HCP5_CANFD01: start 31, 1 bit, little-endian, data-type-policy=OVERRIDE, i-signal-type=PRIMITIVE, init-value=0, base-type=BT_SI_NWDF_30, compu-method=CM_SI_NWDF_30, data-constr=DC_SI_NWDF_30, transfer-property=TRIGGERED-ON-CHANGE-WITHOUT-REPETITION, to BMC_HV(timeout 5 s)  # Netzwerk-Diagnose Freigabe zur zentralen Aktivierung der Netzwerkdiagnose (keine Ausblendbedingung aktiv)
      frame Thermomanagement_01_XIX_HCP5_CANFD01: id 0x12DD5516, to BMC_HV, frame-length=64, can-addressing-mode=EXTENDED, can-frame-rx-behavior=CAN-FD, can-frame-tx-behavior=CAN-FD
        pdu Thermomanagement_01_XIX_HCP5_CANFD01: length=64, minimum-delay=0.01, transmission-mode-true-timing={cyclic-timing={time-offset=0, time-period=0.1}, event-controlled-timing={number-of-repetitions=5, repetition-period=0.02}}, unused-bit-pattern=0
          signal TME_EKK_Istmodus_XIX_Thermomanagement_01_XIX_HCP5_CANFD01: start 12, 3 bit, little-endian, data-type-policy=OVERRIDE, i-signal-type=PRIMITIVE, init-value=7, base-type=BT_TME_EKK_Istmodus, invalid-value=Invalid_TME_EKK_Istmodus_XIX_Thermomanagement_01_XIX_HCP5_CANFD01:5, compu-method=CM_TME_EKK_Istmodus, data-constr=DC_TME_EKK_Istmodus, transfer-property=PENDING  # aktuelle IstModus des elektrischen Klimakompressors
          signal TME_IPB_Status_Kuehlung_XIX_Thermomanagement_01_XIX_HCP5_CANFD01: start 15, 1 bit, little-endian, data-type-policy=OVERRIDE, i-signal-type=PRIMITIVE, init-value=0, base-type=BT_TME_IPB_Status_Kuehlung, invalid-value=Invalid_TME_IPB_Status_Kuehlung_XIX_Thermomanagement_01_XIX_HCP5_CANFD01:1, compu-method=CM_TME_IPB_Status_Kuehlung, data-constr=DC_TME_IPB_Status_Kuehlung, transfer-property=PENDING  # Statuss seitens Thermomanagement, ob die Kühlung der IPB funktional i.O. ist
          signal TME_HVHW_Ansteuerung_Soll_XIX_Thermomanagement_01_XIX_HCP5_CANFD01: start 24, 8 bit, little-endian, data-type-policy=OVERRIDE, i-signal-type=PRIMITIVE, init-value=254, base-type=BT_TME_HVHW_Ansteuerung_Soll, invalid-value=Invalid_TME_HVHW_Ansteuerung_Soll_XIX_Thermomanagement_01_XIX_HCP5_CANFD01:255, compu-method=CM_TME_HVHW_Ansteuerung_Soll, data-constr=DC_TME_HVHW_Ansteuerung_Soll, unit=Unit_Unit_PerCent, transfer-property=PENDING  # Soll Ansteuerung für den HV-Heizer-Wasser
          signal KL_Verdampfertemperatur_XIX_Thermomanagement_01_XIX_HCP5_CANFD01: start 32, 10 bit, little-endian, data-type-policy=OVERRIDE, i-signal-type=PRIMITIVE, init-value=1022, base-type=BT_KL_Verdampfertemperatur, invalid-value=Invalid_KL_Verdampfertemperatur_XIX_Thermomanagement_01_XIX_HCP5_CANFD01:1023, compu-method=CM_KL_Verdampfertemperatur, data-constr=DC_KL_Verdampfertemperatur, unit=Unit_Unit_DegreCelsi, transfer-property=PENDING  # Istwert der Verdampfertemperatur
          signal TME_HVHL_Istmodus_XIX_Thermomanagement_01_XIX_HCP5_CANFD01: start 42, 3 bit, little-endian, data-type-policy=OVERRIDE, i-signal-type=PRIMITIVE, init-value=7, base-type=BT_TME_HVHL_Istmodus, invalid-value=Invalid_TME_HVHL_Istmodus_XIX_Thermomanagement_01_XIX_HCP5_CANFD01:5, compu-method=CM_TME_HVHL_Istmodus, data-constr=DC_TME_HVHL_Istmodus, transfer-property=PENDING  # aktueller Status des HV-Heizer-Wasser
          signal TME_PTC_Verbauinfo_XIX_Thermomanagement_01_XIX_HCP5_CANFD01: start 45, 2 bit, little-endian, data-type-policy=OVERRIDE, i-signal-type=PRIMITIVE, init-value=0, base-type=BT_TME_PTC_Verbauinfo, compu-method=CM_TME_PTC_Verbauinfo, data-constr=DC_TME_PTC_Verbauinfo, transfer-property=PENDING  # Im Thermomanagement wird der Verbau eines PTCs und dessen elektr. Leistungsklasse codiert
          signal TME_HV_IstLeistung_XIX_Thermomanagement_01_XIX_HCP5_CANFD01: start 47, 9 bit, little-endian, data-type-policy=OVERRIDE, i-signal-type=PRIMITIVE, init-value=510, base-type=BT_TME_HV_IstLeistung, invalid-value=Invalid_TME_HV_IstLeistung_XIX_Thermomanagement_01_XIX_HCP5_CANFD01:511, compu-method=CM_TME_HV_IstLeistung, data-constr=DC_TME_HV_IstLeistung, unit=Unit_Unit_Watt, transfer-property=PENDING  # Aktuelle HV Leistung aller HV-Komponenten des Thermomanagements
          signal TME_HVEM_HV_Anf_XIX_Thermomanagement_01_XIX_HCP5_CANFD01: start 56, 2 bit, little-endian, data-type-policy=OVERRIDE, i-signal-type=PRIMITIVE, init-value=0, base-type=BT_TME_HVEM_HV_Anf, invalid-value=Invalid_TME_HVEM_HV_Anf_XIX_Thermomanagement_01_XIX_HCP5_CANFD01:3, compu-method=CM_TME_HVEM_HV_Anf, data-constr=DC_TME_HVEM_HV_Anf, transfer-property=PENDING  # Anforderung "HV-Netz aktivieren" wegen Innenraumkonditionierung mit HV-Komponente
          signal EKK_HVK_EoHVL_Status_XIX_Thermomanagement_01_XIX_HCP5_CANFD01: start 58, 2 bit, little-endian, data-type-policy=OVERRIDE, i-signal-type=PRIMITIVE, init-value=0, base-type=BT_EKK_HVK_EoHVL_Status, invalid-value=Invalid_EKK_HVK_EoHVL_Status_XIX_Thermomanagement_01_XIX_HCP5_CANFD01:3, compu-method=CM_EKK_HVK_EoHVL_Status, data-constr=DC_EKK_HVK_EoHVL_Status, transfer-property=PENDING, to BMC_HV(timeout 1 s)  # Status - Erkennung offener HV-Leitung des elektrischen Klimakompressors
          signal HVHL_HVK_EoHVL_Status_XIX_Thermomanagement_01_XIX_HCP5_CANFD01: start 60, 2 bit, little-endian, data-type-policy=OVERRIDE, i-signal-type=PRIMITIVE, init-value=0, base-type=BT_HVHL_HVK_EoHVL_Status, invalid-value=Invalid_HVHL_HVK_EoHVL_Status_XIX_Thermomanagement_01_XIX_HCP5_CANFD01:3, compu-method=CM_HVHL_HVK_EoHVL_Status, data-constr=DC_HVHL_HVK_EoHVL_Status, transfer-property=PENDING  # Status - Erkennung offener HV-Leitung desHV-Heizer-Wasser
          signal TME_HVHW_SollModus_XIX_Thermomanagement_01_XIX_HCP5_CANFD01: start 62, 2 bit, little-endian, data-type-policy=OVERRIDE, i-signal-type=PRIMITIVE, init-value=3, base-type=BT_TME_HVHW_SollModus, compu-method=CM_TME_HVHW_SollModus, data-constr=DC_TME_HVHW_SollModus, transfer-property=PENDING  # Freigabesignal seitens Thermomanagement für den HV-Heizer-Wasser
          signal TME_Klimaanforderung_XIX_Thermomanagement_01_XIX_HCP5_CANFD01: start 64, 3 bit, little-endian, data-type-policy=OVERRIDE, i-signal-type=PRIMITIVE, init-value=0, base-type=BT_TME_Klimaanforderung, compu-method=CM_TME_Klimaanforderung, data-constr=DC_TME_Klimaanforderung, transfer-property=PENDING  # Anforderungsgrund der Klimaapplikation durch die TME
          signal HVHL_HVK_Fehler_intern_XIX_Thermomanagement_01_XIX_HCP5_CANFD01: start 67, 1 bit, little-endian, data-type-policy=OVERRIDE, i-signal-type=PRIMITIVE, init-value=0, base-type=BT_HVHL_HVK_Fehler_intern, compu-method=CM_HVHL_HVK_Fehler_intern, data-constr=DC_HVHL_HVK_Fehler_intern, transfer-property=PENDING  # HVK relevanter Fehler des elektrischen HV-Heizer-Wasser
          signal HV_Heizer_Status_XIX_Thermomanagement_01_XIX_HCP5_CANFD01: start 68, 2 bit, little-endian, data-type-policy=OVERRIDE, i-signal-type=PRIMITIVE, init-value=0, base-type=BT_HV_Heizer_Status, compu-method=CM_HV_Heizer_Status, data-constr=DC_HV_Heizer_Status, transfer-property=TRIGGERED-ON-CHANGE-WITHOUT-REPETITION  # Ansteuerstatus Hochvoltheizer
          signal Kompressor_Status_XIX_Thermomanagement_01_XIX_HCP5_CANFD01: start 70, 2 bit, little-endian, data-type-policy=OVERRIDE, i-signal-type=PRIMITIVE, init-value=0, base-type=BT_Kompressor_Status, compu-method=CM_Kompressor_Status, data-constr=DC_Kompressor_Status, transfer-property=TRIGGERED-ON-CHANGE-WITHOUT-REPETITION  # Ansteuerstatus Klimakompressor
          signal EKK_HVK_Fehler_intern_XIX_Thermomanagement_01_XIX_HCP5_CANFD01: start 72, 1 bit, little-endian, data-type-policy=OVERRIDE, i-signal-type=PRIMITIVE, init-value=0, base-type=BT_EKK_HVK_Fehler_intern, compu-method=CM_EKK_HVK_Fehler_intern, data-constr=DC_EKK_HVK_Fehler_intern, transfer-property=PENDING  # HVK relevanter Fehler des elektrischen Klimakompressors
          signal Waermepumpe_Status_XIX_Thermomanagement_01_XIX_HCP5_CANFD01: start 73, 2 bit, little-endian, data-type-policy=OVERRIDE, i-signal-type=PRIMITIVE, init-value=0, base-type=BT_Waermepumpe_Status, compu-method=CM_Waermepumpe_Status, data-constr=DC_Waermepumpe_Status, transfer-property=TRIGGERED-ON-CHANGE-WITHOUT-REPETITION  # Ansteuerstatus Wärmepumpe
          signal Thermo_Verbrauch_BTL_XIX_Thermomanagement_01_XIX_HCP5_CANFD01: start 75, 13 bit, little-endian, data-type-policy=OVERRIDE, i-signal-type=PRIMITIVE, init-value=0, base-type=BT_Thermo_Verbrauch_BTL, compu-method=CM_Thermo_Verbrauch_BTL, data-constr=DC_Thermo_Verbrauch_BTL, unit=Unit_Unit_WattSecond, transfer-property=PENDING  # Verbrauch für Heizen und Kühlen der Bauteile
          signal Thermo_Verbrauch_BTL_Ueberlauf_XIX_Thermomanagement_01_XIX_HCP5_CANFD01: start 88, 1 bit, little-endian, data-type-policy=OVERRIDE, i-signal-type=PRIMITIVE, init-value=0, base-type=BT_Thermo_Verbrauch_BTL_Ueberlauf, compu-method=CM_Thermo_Verbrauch_BTL_Ueberlauf, data-constr=DC_Thermo_Verbrauch_BTL_Ueberlauf, transfer-property=PENDING  # Überlauf-Bit Verbrauch Bauteil
          signal Thermo_Verbrauch_Innen_Ueberlauf_XIX_Thermomanagement_01_XIX_HCP5_CANFD01: start 89, 1 bit, little-endian, data-type-policy=OVERRIDE, i-signal-type=PRIMITIVE, init-value=0, base-type=BT_Thermo_Verbrauch_Innen_Ueberlauf, compu-method=CM_Thermo_Verbrauch_Innen_Ueberlauf, data-constr=DC_Thermo_Verbrauch_Innen_Ueberlauf, transfer-property=PENDING  # Überlauf-Bit Verbrauch Innenraum
          signal Thermo_Verbrauch_Innen_XIX_Thermomanagement_01_XIX_HCP5_CANFD01: start 90, 13 bit, little-endian, data-type-policy=OVERRIDE, i-signal-type=PRIMITIVE, init-value=0, base-type=BT_Thermo_Verbrauch_Innen, compu-method=CM_Thermo_Verbrauch_Innen, data-constr=DC_Thermo_Verbrauch_Innen, unit=Unit_Unit_WattSecond, transfer-property=PENDING  # Verbrauch für Heizen und Kühlen Innenraum
          signal TME_HVHW_HVK_Fehler_intern_XIX_Thermomanagement_01_XIX_HCP5_CANFD01: start 103, 1 bit, little-endian, data-type-policy=OVERRIDE, i-signal-type=PRIMITIVE, init-value=0, base-type=BT_TME_HVHW_HVK_Fehler_intern, compu-method=CM_TME_HVHW_HVK_Fehler_intern, data-constr=DC_TME_HVHW_HVK_Fehler_intern, transfer-property=PENDING  # HVK relevanter Fehler des HV-Heizers
          signal TME_Min_Fahrdrehzahl_XIX_Thermomanagement_01_XIX_HCP5_CANFD01: start 104, 7 bit, little-endian, data-type-policy=OVERRIDE, i-signal-type=PRIMITIVE, init-value=126, base-type=BT_TME_Min_Fahrdrehzahl, invalid-value=Invalid_TME_Min_Fahrdrehzahl_XIX_Thermomanagement_01_XIX_HCP5_CANFD01:127, compu-method=CM_TME_Min_Fahrdrehzahl, data-constr=DC_TME_Min_Fahrdrehzahl, unit=Unit_Unit_MinutInver, transfer-property=PENDING  # Minimale Motordrehzahl während der Fahrt
          signal TME_HVHW_HVK_IstModus_XIX_Thermomanagement_01_XIX_HCP5_CANFD01: start 111, 3 bit, little-endian, data-type-policy=OVERRIDE, i-signal-type=PRIMITIVE, init-value=7, base-type=BT_TME_HVHW_HVK_IstModus, invalid-value=Invalid_TME_HVHW_HVK_IstModus_XIX_Thermomanagement_01_XIX_HCP5_CANFD01:5, compu-method=CM_TME_HVHW_HVK_IstModus, data-constr=DC_TME_HVHW_HVK_IstModus, transfer-property=PENDING  # Istmodus des HV-Heizers
          signal TME_HVHW_HVK_EoHVL_Status_XIX_Thermomanagement_01_XIX_HCP5_CANFD01: start 114, 2 bit, little-endian, data-type-policy=OVERRIDE, i-signal-type=PRIMITIVE, init-value=0, base-type=BT_TME_HVHW_HVK_EoHVL_Status, invalid-value=Invalid_TME_HVHW_HVK_EoHVL_Status_XIX_Thermomanagement_01_XIX_HCP5_CANFD01:3, compu-method=CM_TME_HVHW_HVK_EoHVL_Status, data-constr=DC_TME_HVHW_HVK_EoHVL_Status, transfer-property=PENDING  # HV-Heizer Erkennung offene HV-Leitung
          signal TME_HVHW_HVK_Fehler_HVIL_XIX_Thermomanagement_01_XIX_HCP5_CANFD01: start 116, 2 bit, little-endian, data-type-policy=OVERRIDE, i-signal-type=PRIMITIVE, init-value=3, base-type=BT_TME_HVHW_HVK_Fehler_HVIL, invalid-value=Invalid_TME_HVHW_HVK_Fehler_HVIL_XIX_Thermomanagement_01_XIX_HCP5_CANFD01:2, compu-method=CM_TME_HVHW_HVK_Fehler_HVIL, data-constr=DC_TME_HVHW_HVK_Fehler_HVIL, transfer-property=PENDING  # HV-Interlock-Status des HV-Heizers
          signal TME_HVHW_HVK_Status_Spgfreiheit_XIX_Thermomanagement_01_XIX_HCP5_CANFD01: start 118, 2 bit, little-endian, data-type-policy=OVERRIDE, i-signal-type=PRIMITIVE, init-value=0, base-type=BT_TME_HVHW_HVK_Status_Spgfreiheit, invalid-value=Invalid_TME_HVHW_HVK_Status_Spgfreiheit_XIX_Thermomanagement_01_XIX_HCP5_CANFD01:3, compu-method=CM_TME_HVHW_HVK_Status_Spgfreiheit, data-constr=DC_TME_HVHW_HVK_Status_Spgfreiheit, transfer-property=PENDING  # Status ueber Spannungsfreiheit des HV-Heizers
          signal TME_Batt_Kond_Verf_XIX_Thermomanagement_01_XIX_HCP5_CANFD01: start 120, 3 bit, little-endian, data-type-policy=OVERRIDE, i-signal-type=PRIMITIVE, init-value=0, base-type=BT_TME_Batt_Kond_Verf, compu-method=CM_TME_Batt_Kond_Verf, data-constr=DC_TME_Batt_Kond_Verf, transfer-property=PENDING, to BMC_HV(timeout 1 s)  # Verfügbarkeit der Vorkonditionierung der Batterie
          signal TME_HVHL_NTC_Warnung_XIX_Thermomanagement_01_XIX_HCP5_CANFD01: start 123, 1 bit, little-endian, data-type-policy=OVERRIDE, i-signal-type=PRIMITIVE, init-value=0, base-type=BT_TME_HVHL_NTC_Warnung, compu-method=CM_TME_HVHL_NTC_Warnung, data-constr=DC_TME_HVHL_NTC_Warnung, transfer-property=PENDING  # Warnung vor Leistungsreduzierung des HVHL und möglichem NTC-Verhalten
          signal TME_HVHW_HVK_Fehler_AE_XIX_Thermomanagement_01_XIX_HCP5_CANFD01: start 124, 2 bit, little-endian, data-type-policy=OVERRIDE, i-signal-type=PRIMITIVE, init-value=2, base-type=BT_TME_HVHW_HVK_Fehler_AE, invalid-value=Invalid_TME_HVHW_HVK_Fehler_AE_XIX_Thermomanagement_01_XIX_HCP5_CANFD01:1, compu-method=CM_TME_HVHW_HVK_Fehler_AE, data-constr=DC_TME_HVHW_HVK_Fehler_AE, transfer-property=TRIGGERED-ON-CHANGE  # Fehlerstatus aktive Entladung HV-PTC Wertebelegung
          signal TME_Klima_Red_Heizleistung_HVHL_XIX_Thermomanagement_01_XIX_HCP5_CANFD01: start 126, 2 bit, little-endian, data-type-policy=OVERRIDE, i-signal-type=PRIMITIVE, init-value=0, base-type=BT_TME_Klima_Red_Heizleistung_HVHL, compu-method=CM_TME_Klima_Red_Heizleistung_HVHL, data-constr=DC_TME_Klima_Red_Heizleistung_HVHL, transfer-property=PENDING  # Status reduzierte Heizleistung des HV-Luftheizers für die Innenraumklimatisierung
          signal TME_Verbrauch_gesamt_XIX_Thermomanagement_01_XIX_HCP5_CANFD01: start 128, 12 bit, little-endian, data-type-policy=OVERRIDE, i-signal-type=PRIMITIVE, init-value=0, base-type=BT_TME_Verbrauch_gesamt, compu-method=CM_TME_Verbrauch_gesamt, data-constr=DC_TME_Verbrauch_gesamt, unit=Unit_Unit_WattSecond, transfer-property=TRIGGERED-ON-CHANGE-WITHOUT-REPETITION  # Energieverbrauch vom TME für Komfort- und Thermo-Bereich
          signal TME_Verbrauch_gesamt_Ueberlauf_XIX_Thermomanagement_01_XIX_HCP5_CANFD01: start 140, 1 bit, little-endian, data-type-policy=OVERRIDE, i-signal-type=PRIMITIVE, init-value=0, base-type=BT_TME_Verbrauch_gesamt_Ueberlauf, compu-method=CM_TME_Verbrauch_gesamt_Ueberlauf, data-constr=DC_TME_Verbrauch_gesamt_Ueberlauf, transfer-property=TRIGGERED-ON-CHANGE-WITHOUT-REPETITION  # Überlauf-Bit für das Signal TME_Verbrauch_gesamt
          signal EKK_HVK_Status_Spgfreiheit_XIX_Thermomanagement_01_XIX_HCP5_CANFD01: start 141, 2 bit, little-endian, data-type-policy=OVERRIDE, i-signal-type=PRIMITIVE, init-value=0, base-type=BT_EKK_HVK_Status_Spgfreiheit, invalid-value=Invalid_EKK_HVK_Status_Spgfreiheit_XIX_Thermomanagement_01_XIX_HCP5_CANFD01:3, compu-method=CM_EKK_HVK_Status_Spgfreiheit, data-constr=DC_EKK_HVK_Status_Spgfreiheit, transfer-property=TRIGGERED-ON-CHANGE-WITHOUT-REPETITION  # Status ueber Spannungsfreiheit des elektrischen Klimakompressors
          signal TME_HVHL_verfuegbar_XIX_Thermomanagement_01_XIX_HCP5_CANFD01: start 143, 1 bit, little-endian, data-type-policy=OVERRIDE, i-signal-type=PRIMITIVE, init-value=0, base-type=BT_TME_HVHL_verfuegbar, compu-method=CM_TME_HVHL_verfuegbar, data-constr=DC_TME_HVHL_verfuegbar, transfer-property=PENDING  # HV-Luftheizer verfuegbar
          signal HVHL_HVK_Status_Spgfreiheit_XIX_Thermomanagement_01_XIX_HCP5_CANFD01: start 144, 2 bit, little-endian, data-type-policy=OVERRIDE, i-signal-type=PRIMITIVE, init-value=0, base-type=BT_HVHL_HVK_Status_Spgfreiheit, invalid-value=Invalid_HVHL_HVK_Status_Spgfreiheit_XIX_Thermomanagement_01_XIX_HCP5_CANFD01:3, compu-method=CM_HVHL_HVK_Status_Spgfreiheit, data-constr=DC_HVHL_HVK_Status_Spgfreiheit, transfer-property=TRIGGERED-ON-CHANGE-WITHOUT-REPETITION  # Status ueber Spannungsfreiheit des HV-Luftheizers
          signal TME_NT_Kreis_Status_XIX_Thermomanagement_01_XIX_HCP5_CANFD01: start 146, 1 bit, little-endian, data-type-policy=OVERRIDE, i-signal-type=PRIMITIVE, init-value=0, base-type=BT_TME_NT_Kreis_Status, invalid-value=Invalid_TME_NT_Kreis_Status_XIX_Thermomanagement_01_XIX_HCP5_CANFD01:1, compu-method=CM_TME_NT_Kreis_Status, data-constr=DC_TME_NT_Kreis_Status, transfer-property=PENDING  # Status gibt an ob der NT Kreis funktional i.O ist. (Komponenten i.O)
          signal TME_ELM1_IstVolumenstrom_XIX_Thermomanagement_01_XIX_HCP5_CANFD01: start 147, 5 bit, little-endian, data-type-policy=OVERRIDE, i-signal-type=PRIMITIVE, init-value=30, base-type=BT_TME_ELM1_IstVolumenstrom, invalid-value=Invalid_TME_ELM1_IstVolumenstrom_XIX_Thermomanagement_01_XIX_HCP5_CANFD01:31, compu-method=CM_TME_ELM1_IstVolumenstrom, data-constr=DC_TME_ELM1_IstVolumenstrom, unit=Unit_Unit_LiterPerMinut, transfer-property=PENDING  # Ist-Volumenstrom Kuehlkreis Leistungselektronik
          signal TME_ELM2_IstVolumenstrom_XIX_Thermomanagement_01_XIX_HCP5_CANFD01: start 152, 5 bit, little-endian, data-type-policy=OVERRIDE, i-signal-type=PRIMITIVE, init-value=30, base-type=BT_TME_ELM2_IstVolumenstrom, invalid-value=Invalid_TME_ELM2_IstVolumenstrom_XIX_Thermomanagement_01_XIX_HCP5_CANFD01:31, compu-method=CM_TME_ELM2_IstVolumenstrom, data-constr=DC_TME_ELM2_IstVolumenstrom, unit=Unit_Unit_LiterPerMinut, transfer-property=PENDING  # Ist-Volumenstrom Kuehlkreis Leistungselektronik
          signal TME_ELM3_IstVolumenstrom_XIX_Thermomanagement_01_XIX_HCP5_CANFD01: start 157, 5 bit, little-endian, data-type-policy=OVERRIDE, i-signal-type=PRIMITIVE, init-value=30, base-type=BT_TME_ELM3_IstVolumenstrom, invalid-value=Invalid_TME_ELM3_IstVolumenstrom_XIX_Thermomanagement_01_XIX_HCP5_CANFD01:31, compu-method=CM_TME_ELM3_IstVolumenstrom, data-constr=DC_TME_ELM3_IstVolumenstrom, unit=Unit_Unit_LiterPerMinut, transfer-property=PENDING  # Ist-Volumenstrom Kuehlkreis Leistungselektronik
          signal TME_Temp_KM_vor_LE_XIX_Thermomanagement_01_XIX_HCP5_CANFD01: start 162, 8 bit, little-endian, data-type-policy=OVERRIDE, i-signal-type=PRIMITIVE, init-value=254, base-type=BT_TME_Temp_KM_vor_LE, invalid-value=Invalid_TME_Temp_KM_vor_LE_XIX_Thermomanagement_01_XIX_HCP5_CANFD01:255, compu-method=CM_TME_Temp_KM_vor_LE, data-constr=DC_TME_Temp_KM_vor_LE, unit=Unit_Unit_DegreCelsi, transfer-property=PENDING  # Kuehlmittelvorlauftemperatur vor der Leistungselektronik
          signal TME_Temp_nach_Heizung_Front_XIX_Thermomanagement_01_XIX_HCP5_CANFD01: start 170, 10 bit, little-endian, data-type-policy=OVERRIDE, i-signal-type=PRIMITIVE, init-value=1022, base-type=BT_TME_Temp_nach_Heizung_Front, invalid-value=Invalid_TME_Temp_nach_Heizung_Front_XIX_Thermomanagement_01_XIX_HCP5_CANFD01:1023, compu-method=CM_TME_Temp_nach_Heizung_Front, data-constr=DC_TME_Temp_nach_Heizung_Front, unit=Unit_Unit_DegreCelsi, transfer-property=PENDING  # Lufttemperatur nach Heizungswaermetauscher Front
          signal TME_Temp_nach_Verdampfer_Front_XIX_Thermomanagement_01_XIX_HCP5_CANFD01: start 180, 10 bit, little-endian, data-type-policy=OVERRIDE, i-signal-type=PRIMITIVE, init-value=1022, base-type=BT_TME_Temp_nach_Verdampfer_Front, invalid-value=Invalid_TME_Temp_nach_Verdampfer_Front_XIX_Thermomanagement_01_XIX_HCP5_CANFD01:1023, compu-method=CM_TME_Temp_nach_Verdampfer_Front, data-constr=DC_TME_Temp_nach_Verdampfer_Front, unit=Unit_Unit_DegreCelsi, transfer-property=PENDING  # Lufttemperatur nach Frontverdampfer
          signal TME_Temp_nach_HVH_Heizk1_1_XIX_Thermomanagement_01_XIX_HCP5_CANFD01: start 190, 10 bit, little-endian, data-type-policy=OVERRIDE, i-signal-type=PRIMITIVE, init-value=1022, base-type=BT_TME_Temp_nach_HVH_Heizk1_1, invalid-value=Invalid_TME_Temp_nach_HVH_Heizk1_1_XIX_Thermomanagement_01_XIX_HCP5_CANFD01:1023, compu-method=CM_TME_Temp_nach_HVH_Heizk1_1, data-constr=DC_TME_Temp_nach_HVH_Heizk1_1, unit=Unit_Unit_DegreCelsi, transfer-property=PENDING  # Lufttemperatur nach Heizungswaermetauscher Front
          signal TME_Temp_nach_HVH_Heizk1_2_XIX_Thermomanagement_01_XIX_HCP5_CANFD01: start 200, 10 bit, little-endian, data-type-policy=OVERRIDE, i-signal-type=PRIMITIVE, init-value=1022, base-type=BT_TME_Temp_nach_HVH_Heizk1_2, invalid-value=Invalid_TME_Temp_nach_HVH_Heizk1_2_XIX_Thermomanagement_01_XIX_HCP5_CANFD01:1023, compu-method=CM_TME_Temp_nach_HVH_Heizk1_2, data-constr=DC_TME_Temp_nach_HVH_Heizk1_2, unit=Unit_Unit_DegreCelsi, transfer-property=PENDING  # Lufttemperatur nach Heizungswaermetauscher Front
          signal TME_Temp_nach_HVH_Heizk2_1_XIX_Thermomanagement_01_XIX_HCP5_CANFD01: start 210, 10 bit, little-endian, data-type-policy=OVERRIDE, i-signal-type=PRIMITIVE, init-value=1022, base-type=BT_TME_Temp_nach_HVH_Heizk2_1, invalid-value=Invalid_TME_Temp_nach_HVH_Heizk2_1_XIX_Thermomanagement_01_XIX_HCP5_CANFD01:1023, compu-method=CM_TME_Temp_nach_HVH_Heizk2_1, data-constr=DC_TME_Temp_nach_HVH_Heizk2_1, unit=Unit_Unit_DegreCelsi, transfer-property=PENDING  # Lufttemperatur nach Heizungswaermetauscher Front
          signal TME_Temp_nach_HVH_Heizk2_2_XIX_Thermomanagement_01_XIX_HCP5_CANFD01: start 220, 10 bit, little-endian, data-type-policy=OVERRIDE, i-signal-type=PRIMITIVE, init-value=1022, base-type=BT_TME_Temp_nach_HVH_Heizk2_2, invalid-value=Invalid_TME_Temp_nach_HVH_Heizk2_2_XIX_Thermomanagement_01_XIX_HCP5_CANFD01:1023, compu-method=CM_TME_Temp_nach_HVH_Heizk2_2, data-constr=DC_TME_Temp_nach_HVH_Heizk2_2, unit=Unit_Unit_DegreCelsi, transfer-property=PENDING  # Lufttemperatur nach Heizungswaermetauscher Front
          signal TME_Temp_nach_HVH_Heizk3_1_XIX_Thermomanagement_01_XIX_HCP5_CANFD01: start 230, 10 bit, little-endian, data-type-policy=OVERRIDE, i-signal-type=PRIMITIVE, init-value=1022, base-type=BT_TME_Temp_nach_HVH_Heizk3_1, invalid-value=Invalid_TME_Temp_nach_HVH_Heizk3_1_XIX_Thermomanagement_01_XIX_HCP5_CANFD01:1023, compu-method=CM_TME_Temp_nach_HVH_Heizk3_1, data-constr=DC_TME_Temp_nach_HVH_Heizk3_1, unit=Unit_Unit_DegreCelsi, transfer-property=PENDING  # Lufttemperatur nach Heizungswaermetauscher Front
          signal TME_Temp_nach_HVH_Heizk3_2_XIX_Thermomanagement_01_XIX_HCP5_CANFD01: start 240, 10 bit, little-endian, data-type-policy=OVERRIDE, i-signal-type=PRIMITIVE, init-value=1022, base-type=BT_TME_Temp_nach_HVH_Heizk3_2, invalid-value=Invalid_TME_Temp_nach_HVH_Heizk3_2_XIX_Thermomanagement_01_XIX_HCP5_CANFD01:1023, compu-method=CM_TME_Temp_nach_HVH_Heizk3_2, data-constr=DC_TME_Temp_nach_HVH_Heizk3_2, unit=Unit_Unit_DegreCelsi, transfer-property=PENDING  # Lufttemperatur nach Heizungswaermetauscher Front
          signal TME_Temp_nach_HVH_Heizk4_1_XIX_Thermomanagement_01_XIX_HCP5_CANFD01: start 250, 10 bit, little-endian, data-type-policy=OVERRIDE, i-signal-type=PRIMITIVE, init-value=1022, base-type=BT_TME_Temp_nach_HVH_Heizk4_1, invalid-value=Invalid_TME_Temp_nach_HVH_Heizk4_1_XIX_Thermomanagement_01_XIX_HCP5_CANFD01:1023, compu-method=CM_TME_Temp_nach_HVH_Heizk4_1, data-constr=DC_TME_Temp_nach_HVH_Heizk4_1, unit=Unit_Unit_DegreCelsi, transfer-property=PENDING  # Lufttemperatur nach Heizungswaermetauscher Front
          signal TME_Temp_nach_HVH_Heizk4_2_XIX_Thermomanagement_01_XIX_HCP5_CANFD01: start 260, 10 bit, little-endian, data-type-policy=OVERRIDE, i-signal-type=PRIMITIVE, init-value=1022, base-type=BT_TME_Temp_nach_HVH_Heizk4_2, invalid-value=Invalid_TME_Temp_nach_HVH_Heizk4_2_XIX_Thermomanagement_01_XIX_HCP5_CANFD01:1023, compu-method=CM_TME_Temp_nach_HVH_Heizk4_2, data-constr=DC_TME_Temp_nach_HVH_Heizk4_2, unit=Unit_Unit_DegreCelsi, transfer-property=PENDING  # Lufttemperatur nach Heizungswaermetauscher Front
          signal TME_HVEM_Minleistung_XIX_Thermomanagement_01_XIX_HCP5_CANFD01: start 270, 9 bit, little-endian, data-type-policy=OVERRIDE, i-signal-type=PRIMITIVE, init-value=510, base-type=BT_TME_HVEM_Minleistung, invalid-value=Invalid_TME_HVEM_Minleistung_XIX_Thermomanagement_01_XIX_HCP5_CANFD01:511, compu-method=CM_TME_HVEM_Minleistung, data-constr=DC_TME_HVEM_Minleistung, unit=Unit_Unit_Watt, transfer-property=PENDING  # Angeforderte MinLeistung der TME an das HVEM
          signal TME_HVEM_Wunschleistung_XIX_Thermomanagement_01_XIX_HCP5_CANFD01: start 279, 9 bit, little-endian, data-type-policy=OVERRIDE, i-signal-type=PRIMITIVE, init-value=510, base-type=BT_TME_HVEM_Wunschleistung, invalid-value=Invalid_TME_HVEM_Wunschleistung_XIX_Thermomanagement_01_XIX_HCP5_CANFD01:511, compu-method=CM_TME_HVEM_Wunschleistung, data-constr=DC_TME_HVEM_Wunschleistung, unit=Unit_Unit_Watt, transfer-property=PENDING  # Angeforderte Leistung der TME an das HVEM
          signal TME_OBD_Lampe_Anf_XIX_Thermomanagement_01_XIX_HCP5_CANFD01: start 288, 1 bit, little-endian, data-type-policy=OVERRIDE, i-signal-type=PRIMITIVE, init-value=0, base-type=BT_TME_OBD_Lampe_Anf, compu-method=CM_TME_OBD_Lampe_Anf, data-constr=DC_TME_OBD_Lampe_Anf, transfer-property=PENDING  # MIL-Request durch TME-Steuergerät
          signal TME_Therm_IstLeistung_HVBatterie_XIX_Thermomanagement_01_XIX_HCP5_CANFD01: start 289, 9 bit, little-endian, data-type-policy=OVERRIDE, i-signal-type=PRIMITIVE, init-value=510, base-type=BT_TME_Therm_IstLeistung_HVBatterie, invalid-value=Invalid_TME_Therm_IstLeistung_HVBatterie_XIX_Thermomanagement_01_XIX_HCP5_CANFD01:511, compu-method=CM_TME_Therm_IstLeistung_HVBatterie, data-constr=DC_TME_Therm_IstLeistung_HVBatterie, unit=Unit_Unit_Watt, transfer-property=PENDING, to BMC_HV(timeout 1 s)  # aktuelle thermische Leistung über HV-Batterie(positiv - Wärmeeintrag, negativ - Wärmeentzug)
          signal TME_HVEM_Rekuleistung_XIX_Thermomanagement_01_XIX_HCP5_CANFD01: start 298, 9 bit, little-endian, data-type-policy=OVERRIDE, i-signal-type=PRIMITIVE, init-value=510, base-type=BT_TME_HVEM_Rekuleistung, invalid-value=Invalid_TME_HVEM_Rekuleistung_XIX_Thermomanagement_01_XIX_HCP5_CANFD01:511, compu-method=CM_TME_HVEM_Rekuleistung, data-constr=DC_TME_HVEM_Rekuleistung, unit=Unit_Unit_Watt, transfer-property=PENDING  # HV-Istleistung seitens Thermoamanagement, die als Rekuleistung verwendet werden kann
          signal TME_HV_IstLeistung_EKK_XIX_Thermomanagement_01_XIX_HCP5_CANFD01: start 307, 7 bit, little-endian, data-type-policy=OVERRIDE, i-signal-type=PRIMITIVE, init-value=126, base-type=BT_TME_HV_IstLeistung_EKK, invalid-value=Invalid_TME_HV_IstLeistung_EKK_XIX_Thermomanagement_01_XIX_HCP5_CANFD01:127, compu-method=CM_TME_HV_IstLeistung_EKK, data-constr=DC_TME_HV_IstLeistung_EKK, unit=Unit_Unit_Watt, transfer-property=PENDING  # aktuelle elektrische Leistung HV-Kältemittelverdichter
          signal TME_HV_IstLeistung_HVHL_XIX_Thermomanagement_01_XIX_HCP5_CANFD01: start 314, 7 bit, little-endian, data-type-policy=OVERRIDE, i-signal-type=PRIMITIVE, init-value=126, base-type=BT_TME_HV_IstLeistung_HVHL, invalid-value=Invalid_TME_HV_IstLeistung_HVHL_XIX_Thermomanagement_01_XIX_HCP5_CANFD01:127, compu-method=CM_TME_HV_IstLeistung_HVHL, data-constr=DC_TME_HV_IstLeistung_HVHL, unit=Unit_Unit_Watt, transfer-property=PENDING  # aktuelle elektrische HV-Leistung HV-Luftheizer
          signal TME_LED_STK_XIX_Thermomanagement_01_XIX_HCP5_CANFD01: start 321, 3 bit, little-endian, data-type-policy=OVERRIDE, i-signal-type=PRIMITIVE, init-value=6, base-type=BT_TME_LED_STK, compu-method=CM_TME_LED_STK, data-constr=DC_TME_LED_STK, transfer-property=TRIGGERED-ON-CHANGE  # Funktionsbeleuchtung Standklimatisierungstaste
          signal TME_LED_STK_Timer_XIX_Thermomanagement_01_XIX_HCP5_CANFD01: start 324, 3 bit, little-endian, data-type-policy=OVERRIDE, i-signal-type=PRIMITIVE, init-value=6, base-type=BT_TME_LED_STK_Timer, compu-method=CM_TME_LED_STK_Timer, data-constr=DC_TME_LED_STK_Timer, transfer-property=TRIGGERED-ON-CHANGE  # Funktionsbeleuchtung Standklimatisierungstaste fuer Timer Symbol
          signal TME_HV_IstLeistung_BTL_XIX_Thermomanagement_01_XIX_HCP5_CANFD01: start 327, 9 bit, little-endian, data-type-policy=OVERRIDE, i-signal-type=PRIMITIVE, init-value=510, base-type=BT_TME_HV_IstLeistung_BTL, invalid-value=Invalid_TME_HV_IstLeistung_BTL_XIX_Thermomanagement_01_XIX_HCP5_CANFD01:511, compu-method=CM_TME_HV_IstLeistung_BTL, data-constr=DC_TME_HV_IstLeistung_BTL, unit=Unit_Unit_Watt, transfer-property=PENDING  # aktuelle elektrische HV-Leistung für Bauteilkonditionierung
          signal TME_HV_IstLeistung_Komfort_XIX_Thermomanagement_01_XIX_HCP5_CANFD01: start 336, 9 bit, little-endian, data-type-policy=OVERRIDE, i-signal-type=PRIMITIVE, init-value=510, base-type=BT_TME_HV_IstLeistung_Komfort, invalid-value=Invalid_TME_HV_IstLeistung_Komfort_XIX_Thermomanagement_01_XIX_HCP5_CANFD01:511, compu-method=CM_TME_HV_IstLeistung_Komfort, data-constr=DC_TME_HV_IstLeistung_Komfort, unit=Unit_Unit_Watt, transfer-property=PENDING  # aktuelle elektrische HV-Leistung für Innenraumklimatisierung
          signal TME_eKMV_Istmodus_XIX_Thermomanagement_01_XIX_HCP5_CANFD01: start 345, 3 bit, little-endian, data-type-policy=OVERRIDE, i-signal-type=PRIMITIVE, init-value=7, base-type=BT_TME_eKMV_Istmodus, invalid-value=Invalid_TME_eKMV_Istmodus_XIX_Thermomanagement_01_XIX_HCP5_CANFD01:5, compu-method=CM_TME_eKMV_Istmodus, data-constr=DC_TME_eKMV_Istmodus, transfer-property=PENDING  # aktuelle IstModus des eKMV
          signal TME_eKMV_Spannung_XIX_Thermomanagement_01_XIX_HCP5_CANFD01: start 348, 9 bit, little-endian, data-type-policy=OVERRIDE, i-signal-type=PRIMITIVE, init-value=510, base-type=BT_TME_eKMV_Spannung, invalid-value=Invalid_TME_eKMV_Spannung_XIX_Thermomanagement_01_XIX_HCP5_CANFD01:511, compu-method=CM_TME_eKMV_Spannung, data-constr=DC_TME_eKMV_Spannung, unit=Unit_Unit_Volt, transfer-property=PENDING  # Gemessene Spannung des eKMV
          signal TME_eKMV_Strom_XIX_Thermomanagement_01_XIX_HCP5_CANFD01: start 357, 8 bit, little-endian, data-type-policy=OVERRIDE, i-signal-type=PRIMITIVE, init-value=254, base-type=BT_TME_eKMV_Strom, invalid-value=Invalid_TME_eKMV_Strom_XIX_Thermomanagement_01_XIX_HCP5_CANFD01:255, compu-method=CM_TME_eKMV_Strom, data-constr=DC_TME_eKMV_Strom, unit=Unit_Unit_Amper, transfer-property=PENDING  # Gemessener Strom des eKMV
          signal TME_HVEM_Abschaltleistung_XIX_Thermomanagement_01_XIX_HCP5_CANFD01: start 365, 9 bit, little-endian, data-type-policy=OVERRIDE, i-signal-type=PRIMITIVE, init-value=510, base-type=BT_TME_HVEM_Abschaltleistung, invalid-value=Invalid_TME_HVEM_Abschaltleistung_XIX_Thermomanagement_01_XIX_HCP5_CANFD01:511, compu-method=CM_TME_HVEM_Abschaltleistung, data-constr=DC_TME_HVEM_Abschaltleistung, unit=Unit_Unit_Watt, transfer-property=PENDING  # mögliche Abschaltleistung seitens TME im Fall Kickdown/Launch control
          signal TME_MSF_Stufe_XIX_Thermomanagement_01_XIX_HCP5_CANFD01: start 374, 2 bit, little-endian, data-type-policy=OVERRIDE, i-signal-type=PRIMITIVE, init-value=0, base-type=BT_TME_MSF_Stufe, compu-method=CM_TME_MSF_Stufe, data-constr=DC_TME_MSF_Stufe, transfer-property=PENDING  # Leistungsstufe in der Mindestschubfunktion seitens TME
          signal TME_MVEM_MinLeistung_XIX_Thermomanagement_01_XIX_HCP5_CANFD01: start 376, 8 bit, little-endian, data-type-policy=OVERRIDE, i-signal-type=PRIMITIVE, init-value=254, base-type=BT_TME_MVEM_MinLeistung, invalid-value=Invalid_TME_MVEM_MinLeistung_XIX_Thermomanagement_01_XIX_HCP5_CANFD01:255, compu-method=CM_TME_MVEM_MinLeistung, data-constr=DC_TME_MVEM_MinLeistung, unit=Unit_Unit_Watt, transfer-property=PENDING  # MV Leistungsbedarf des TME-Systemes für Kllimatisierung/Batteriekühlung
          signal TME_MVEM_Wunschleistung_XIX_Thermomanagement_01_XIX_HCP5_CANFD01: start 384, 8 bit, little-endian, data-type-policy=OVERRIDE, i-signal-type=PRIMITIVE, init-value=254, base-type=BT_TME_MVEM_Wunschleistung, invalid-value=Invalid_TME_MVEM_Wunschleistung_XIX_Thermomanagement_01_XIX_HCP5_CANFD01:255, compu-method=CM_TME_MVEM_Wunschleistung, data-constr=DC_TME_MVEM_Wunschleistung, unit=Unit_Unit_Watt, transfer-property=PENDING  # MV Wunschleistung des TME-Systemes für Kllimatisierung
          signal TME_MVH_L_Istmodus_XIX_Thermomanagement_01_XIX_HCP5_CANFD01: start 392, 3 bit, little-endian, data-type-policy=OVERRIDE, i-signal-type=PRIMITIVE, init-value=7, base-type=BT_TME_MVH_L_Istmodus, invalid-value=Invalid_TME_MVH_L_Istmodus_XIX_Thermomanagement_01_XIX_HCP5_CANFD01:5, compu-method=CM_TME_MVH_L_Istmodus, data-constr=DC_TME_MVH_L_Istmodus, transfer-property=PENDING  # aktueller Ist-Modus des MVH_L
          signal TME_MVH_L_Spannung_XIX_Thermomanagement_01_XIX_HCP5_CANFD01: start 395, 8 bit, little-endian, data-type-policy=OVERRIDE, i-signal-type=PRIMITIVE, init-value=254, base-type=BT_TME_MVH_L_Spannung, invalid-value=Invalid_TME_MVH_L_Spannung_XIX_Thermomanagement_01_XIX_HCP5_CANFD01:255, compu-method=CM_TME_MVH_L_Spannung, data-constr=DC_TME_MVH_L_Spannung, unit=Unit_Unit_Volt, transfer-property=PENDING  # Gemessene Spannung des MVH_L
          signal TME_MVH_L_Strom_XIX_Thermomanagement_01_XIX_HCP5_CANFD01: start 403, 9 bit, little-endian, data-type-policy=OVERRIDE, i-signal-type=PRIMITIVE, init-value=510, base-type=BT_TME_MVH_L_Strom, invalid-value=Invalid_TME_MVH_L_Strom_XIX_Thermomanagement_01_XIX_HCP5_CANFD01:511, compu-method=CM_TME_MVH_L_Strom, data-constr=DC_TME_MVH_L_Strom, unit=Unit_Unit_Amper, transfer-property=PENDING  # Gemessener Strom des MVH_L
          signal TME_ZR_Anforderung_XIX_Thermomanagement_01_XIX_HCP5_CANFD01: start 412, 2 bit, little-endian, data-type-policy=OVERRIDE, i-signal-type=PRIMITIVE, init-value=0, base-type=BT_TME_ZR_Anforderung, compu-method=CM_TME_ZR_Anforderung, data-constr=DC_TME_ZR_Anforderung, transfer-property=PENDING  # Anforderung an MIB die Displays zu aktivieren
          signal TME_HV_Anf_XIX_Thermomanagement_01_XIX_HCP5_CANFD01: start 414, 2 bit, little-endian, data-type-policy=OVERRIDE, i-signal-type=PRIMITIVE, init-value=0, base-type=BT_TME_HV_Anf, compu-method=CM_TME_HV_Anf, data-constr=DC_TME_HV_Anf, transfer-property=PENDING  # Anforderung "HV-Netz aktivieren" wegen Innenraumkonditionierung mit HV-Komponente
          signal TME_HVEM_Vorhaltleistung_XIX_Thermomanagement_01_XIX_HCP5_CANFD01: start 416, 10 bit, little-endian, data-type-policy=OVERRIDE, i-signal-type=PRIMITIVE, init-value=1022, base-type=BT_TME_HVEM_Vorhaltleistung, invalid-value=Invalid_TME_HVEM_Vorhaltleistung_XIX_Thermomanagement_01_XIX_HCP5_CANFD01:1023, compu-method=CM_TME_HVEM_Vorhaltleistung, data-constr=DC_TME_HVEM_Vorhaltleistung, unit=Unit_Unit_Watt, transfer-property=PENDING  # Seitens Thermomanagement benötigter Leistungsvorhalt von HV-System
          signal TME_PTC_stufig_Status_XIX_Thermomanagement_01_XIX_HCP5_CANFD01: start 426, 3 bit, little-endian, data-type-policy=OVERRIDE, i-signal-type=PRIMITIVE, init-value=6, base-type=BT_TME_PTC_stufig_Status, invalid-value=Invalid_TME_PTC_stufig_Status_XIX_Thermomanagement_01_XIX_HCP5_CANFD01:7, compu-method=CM_TME_PTC_stufig_Status, data-constr=DC_TME_PTC_stufig_Status, transfer-property=PENDING  # Status von 12V_PTC_Stufig
          signal TME_EKK_HVK_Fehler_AE_XIX_Thermomanagement_01_XIX_HCP5_CANFD01: start 429, 2 bit, little-endian, data-type-policy=OVERRIDE, i-signal-type=PRIMITIVE, init-value=3, base-type=BT_TME_EKK_HVK_Fehler_AE, compu-method=CM_TME_EKK_HVK_Fehler_AE, data-constr=DC_TME_EKK_HVK_Fehler_AE, transfer-property=TRIGGERED-ON-CHANGE  # Fehlerstatus aktive Entladung EKK
          signal TME_Anforderung_Heizkreispumpe_XIX_Thermomanagement_01_XIX_HCP5_CANFD01: start 431, 7 bit, little-endian, data-type-policy=OVERRIDE, i-signal-type=PRIMITIVE, init-value=126, base-type=BT_TME_Anforderung_Heizkreispumpe, invalid-value=Invalid_TME_Anforderung_Heizkreispumpe_XIX_Thermomanagement_01_XIX_HCP5_CANFD01:127, compu-method=CM_TME_Anforderung_Heizkreispumpe, data-constr=DC_TME_Anforderung_Heizkreispumpe, unit=Unit_Unit_PerCent, transfer-property=PENDING  # Anforderung Heizkreispumpe für Diagnose T-Sensor
          signal TME_Heizanforderung_Innenraum_XIX_Thermomanagement_01_XIX_HCP5_CANFD01: start 438, 2 bit, little-endian, data-type-policy=OVERRIDE, i-signal-type=PRIMITIVE, init-value=0, base-type=BT_TME_Heizanforderung_Innenraum, compu-method=CM_TME_Heizanforderung_Innenraum, data-constr=DC_TME_Heizanforderung_Innenraum, transfer-property=PENDING  # Anforderung an VKM bei Heizbedarf des Innenraums
          signal TME_Kompressorlastmoment_XIX_Thermomanagement_01_XIX_HCP5_CANFD01: start 440, 8 bit, little-endian, data-type-policy=OVERRIDE, i-signal-type=PRIMITIVE, init-value=0, base-type=BT_TME_Kompressorlastmoment, invalid-value=Invalid_TME_Kompressorlastmoment_XIX_Thermomanagement_01_XIX_HCP5_CANFD01:255, compu-method=CM_TME_Kompressorlastmoment, data-constr=DC_TME_Kompressorlastmoment, unit=Unit_Unit_NewtoMeter, transfer-property=PENDING  # Aktuelles Lastmoment des Klimakompressors bezogen auf die Kurbelwelle
          signal TME_Antriebszustand_Anf_XIX_Thermomanagement_01_XIX_HCP5_CANFD01: start 448, 3 bit, little-endian, data-type-policy=OVERRIDE, i-signal-type=PRIMITIVE, init-value=0, base-type=BT_TME_Antriebszustand_Anf, invalid-value=Invalid_TME_Antriebszustand_Anf_XIX_Thermomanagement_01_XIX_HCP5_CANFD01:7, compu-method=CM_TME_Antriebszustand_Anf, data-constr=DC_TME_Antriebszustand_Anf, transfer-property=PENDING  # Antriebszustandsanforderung von Thermomanagement an VKM
          signal TME_Batt_Kond_status_XIX_Thermomanagement_01_XIX_HCP5_CANFD01: start 451, 1 bit, little-endian, data-type-policy=OVERRIDE, i-signal-type=PRIMITIVE, init-value=0, base-type=BT_TME_Batt_Kond_status, compu-method=CM_TME_Batt_Kond_status, data-constr=DC_TME_Batt_Kond_status, transfer-property=PENDING  # Status der Vorkonditionierung der Batterie
          signal TME_Klima_Heizleistung_reduziert_XIX_Thermomanagement_01_XIX_HCP5_CANFD01: start 452, 1 bit, little-endian, data-type-policy=OVERRIDE, i-signal-type=PRIMITIVE, init-value=0, base-type=BT_TME_Klima_Heizleistung_reduziert, compu-method=CM_TME_Klima_Heizleistung_reduziert, data-constr=DC_TME_Klima_Heizleistung_reduziert, transfer-property=PENDING  # Status reduzierte Heizleistung für die Innenraumklimatisierung
          signal TME_Notbelueftung_Aktivierung_XIX_Thermomanagement_01_XIX_HCP5_CANFD01: start 453, 1 bit, little-endian, data-type-policy=OVERRIDE, i-signal-type=PRIMITIVE, init-value=0, base-type=BT_TME_Notbelueftung_Aktivierung, compu-method=CM_TME_Notbelueftung_Aktivierung, data-constr=DC_TME_Notbelueftung_Aktivierung, transfer-property=PENDING  # Anfoderung an Klima, die Notbelueftung zu aktivieren
          signal TME_Vorwarn_Komp_ein_XIX_Thermomanagement_01_XIX_HCP5_CANFD01: start 454, 1 bit, little-endian, data-type-policy=OVERRIDE, i-signal-type=PRIMITIVE, init-value=0, base-type=BT_TME_Vorwarn_Komp_ein, compu-method=CM_TME_Vorwarn_Komp_ein, data-constr=DC_TME_Vorwarn_Komp_ein, transfer-property=PENDING  # Vorwarnung an Motor zum Aufbau Momentenreserve bei kompressor_Ein
          signal TME_PTC_Leistung_Ist_XIX_Thermomanagement_01_XIX_HCP5_CANFD01: start 455, 9 bit, little-endian, data-type-policy=OVERRIDE, i-signal-type=PRIMITIVE, init-value=510, base-type=BT_TME_PTC_Leistung_Ist, invalid-value=Invalid_TME_PTC_Leistung_Ist_XIX_Thermomanagement_01_XIX_HCP5_CANFD01:511, compu-method=CM_TME_PTC_Leistung_Ist, data-constr=DC_TME_PTC_Leistung_Ist, unit=Unit_Unit_Watt, transfer-property=PENDING  # IST_Leistung von NV/MV PTC (LIN und Stufig)
          signal TME_DCDC_HV_Status_Kuehlung_XIX_Thermomanagement_01_XIX_HCP5_CANFD01: start 464, 2 bit, little-endian, data-type-policy=OVERRIDE, i-signal-type=PRIMITIVE, init-value=2, base-type=BT_TME_DCDC_HV_Status_Kuehlung, invalid-value=Invalid_TME_DCDC_HV_Status_Kuehlung_XIX_Thermomanagement_01_XIX_HCP5_CANFD01:1, compu-method=CM_TME_DCDC_HV_Status_Kuehlung, data-constr=DC_TME_DCDC_HV_Status_Kuehlung, transfer-property=PENDING  # TME Fehlerstatus HV DCDC-Wandler Kühlung
          signal TME_NT_Kuehlmittel_Sensor_02_XIX_Thermomanagement_01_XIX_HCP5_CANFD01: start 466, 1 bit, little-endian, data-type-policy=OVERRIDE, i-signal-type=PRIMITIVE, init-value=0, base-type=BT_TME_NT_Kuehlmittel_Sensor_02, compu-method=CM_TME_NT_Kuehlmittel_Sensor_02, data-constr=DC_TME_NT_Kuehlmittel_Sensor_02, transfer-property=PENDING  # Signal der Sensorelektroden für die Kühlmittelreserve aktuell, entstört, bewertet (OK/Mangel)
          signal TME_Min_Leerlaufdrehzahl_XIX_Thermomanagement_01_XIX_HCP5_CANFD01: start 467, 7 bit, little-endian, data-type-policy=OVERRIDE, i-signal-type=PRIMITIVE, init-value=126, base-type=BT_TME_Min_Leerlaufdrehzahl, invalid-value=Invalid_TME_Min_Leerlaufdrehzahl_XIX_Thermomanagement_01_XIX_HCP5_CANFD01:127, compu-method=CM_TME_Min_Leerlaufdrehzahl, data-constr=DC_TME_Min_Leerlaufdrehzahl, unit=Unit_Unit_MinutInver, transfer-property=PENDING  # Minimale Motordrehzahl im Stand
          signal TME_HT_Kuehlmittel_Sensor_XIX_Thermomanagement_01_XIX_HCP5_CANFD01: start 474, 1 bit, little-endian, data-type-policy=OVERRIDE, i-signal-type=PRIMITIVE, init-value=0, base-type=BT_TME_HT_Kuehlmittel_Sensor, compu-method=CM_TME_HT_Kuehlmittel_Sensor, data-constr=DC_TME_HT_Kuehlmittel_Sensor, transfer-property=PENDING  # Signal der Sensorelektroden für die Kühlmittelreserve aktuell, entstört, bewertet (OK/Mangel)
          signal TME_Kuehlerluefter_Totalausfall_XIX_Thermomanagement_01_XIX_HCP5_CANFD01: start 475, 1 bit, little-endian, data-type-policy=OVERRIDE, i-signal-type=PRIMITIVE, init-value=0, base-type=BT_TME_Kuehlerluefter_Totalausfall, compu-method=CM_TME_Kuehlerluefter_Totalausfall, data-constr=DC_TME_Kuehlerluefter_Totalausfall, transfer-property=PENDING  # Totalausfall Kühlerlüfter
          signal TME_Kuehlerjalousie_Ausfall_XIX_Thermomanagement_01_XIX_HCP5_CANFD01: start 476, 1 bit, little-endian, data-type-policy=OVERRIDE, i-signal-type=PRIMITIVE, init-value=0, base-type=BT_TME_Kuehlerjalousie_Ausfall, compu-method=CM_TME_Kuehlerjalousie_Ausfall, data-constr=DC_TME_Kuehlerjalousie_Ausfall, transfer-property=PENDING  # Ausfall Kühlerjalousie
          signal TME_HV_IstLeistung_HVHW_XIX_Thermomanagement_01_XIX_HCP5_CANFD01: start 477, 7 bit, little-endian, data-type-policy=OVERRIDE, i-signal-type=PRIMITIVE, init-value=126, base-type=BT_TME_HV_IstLeistung_HVHW, invalid-value=Invalid_TME_HV_IstLeistung_HVHW_XIX_Thermomanagement_01_XIX_HCP5_CANFD01:127, compu-method=CM_TME_HV_IstLeistung_HVHW, data-constr=DC_TME_HV_IstLeistung_HVHW, unit=Unit_Unit_Watt, transfer-property=PENDING  # aktuelle HV-Leistung HV-Heizer Wasser
          signal TME_Temp_nach_Heizregister_XIX_Thermomanagement_01_XIX_HCP5_CANFD01: start 484, 10 bit, little-endian, data-type-policy=OVERRIDE, i-signal-type=PRIMITIVE, init-value=1022, base-type=BT_TME_Temp_nach_Heizregister, invalid-value=Invalid_TME_Temp_nach_Heizregister_XIX_Thermomanagement_01_XIX_HCP5_CANFD01:1023, compu-method=CM_TME_Temp_nach_Heizregister, data-constr=DC_TME_Temp_nach_Heizregister, unit=Unit_Unit_DegreCelsi, transfer-property=PENDING  # Determined air temperature after damper register
          signal TME_HVHW_Verbauinfo_XIX_Thermomanagement_01_XIX_HCP5_CANFD01: start 494, 2 bit, little-endian, data-type-policy=OVERRIDE, i-signal-type=PRIMITIVE, init-value=0, base-type=BT_TME_HVHW_Verbauinfo, compu-method=CM_TME_HVHW_Verbauinfo, data-constr=DC_TME_HVHW_Verbauinfo, transfer-property=PENDING  # Verbauinfo des Hochvolt-Heizer Luft
          signal TME_HVHL_Verbauinfo_XIX_Thermomanagement_01_XIX_HCP5_CANFD01: start 496, 2 bit, little-endian, data-type-policy=OVERRIDE, i-signal-type=PRIMITIVE, init-value=0, base-type=BT_TME_HVHL_Verbauinfo, compu-method=CM_TME_HVHL_Verbauinfo, data-constr=DC_TME_HVHL_Verbauinfo, transfer-property=PENDING  # Verbauinformation für den HV-Heizer Luft
          signal TME_MVH_L_Verbauinfo_XIX_Thermomanagement_01_XIX_HCP5_CANFD01: start 498, 2 bit, little-endian, data-type-policy=OVERRIDE, i-signal-type=PRIMITIVE, init-value=0, base-type=BT_TME_MVH_L_Verbauinfo, compu-method=CM_TME_MVH_L_Verbauinfo, data-constr=DC_TME_MVH_L_Verbauinfo, transfer-property=PENDING  # Verbauinformation für den MV-Heizer Luft
          signal TME_ETV_IstVolumenstrom_XIX_Thermomanagement_01_XIX_HCP5_CANFD01: start 500, 9 bit, little-endian, data-type-policy=OVERRIDE, i-signal-type=PRIMITIVE, init-value=510, base-type=BT_TME_ETV_IstVolumenstrom, invalid-value=Invalid_TME_ETV_IstVolumenstrom_XIX_Thermomanagement_01_XIX_HCP5_CANFD01:511, compu-method=CM_TME_ETV_IstVolumenstrom, data-constr=DC_TME_ETV_IstVolumenstrom, unit=Unit_Unit_LiterPerMinut, transfer-property=PENDING  # Ist-Volumenstrom Kühlkreis am eTV
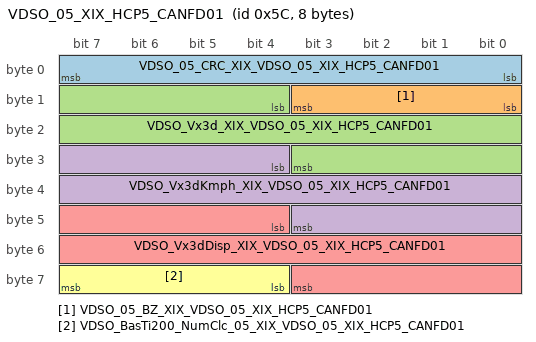
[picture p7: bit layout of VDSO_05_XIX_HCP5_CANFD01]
      frame VDSO_05_XIX_HCP5_CANFD01: id 0x5C, to BMC_HV, frame-length=8, can-addressing-mode=STANDARD, can-frame-rx-behavior=CAN-FD, can-frame-tx-behavior=CAN-FD
        pdu VDSO_05_XIX_HCP5_CANFD01: length=8, transmission-mode-true-timing=cyclic-timing={time-offset=0, time-period=0.05}, unused-bit-pattern=0
          signal VDSO_05_CRC_XIX_VDSO_05_XIX_HCP5_CANFD01: start 0, 8 bit, little-endian, data-type-policy=OVERRIDE, i-signal-type=PRIMITIVE, init-value=0, base-type=BT_VDSO_05_CRC, compu-method=CM_VDSO_05_CRC, data-constr=DC_VDSO_05_CRC, transfer-property=PENDING  # Für MLB: Berechnung siehe Lastenheft "Kommunikationsabsicherung für FlexRay und CAN" Ab MQB und MLBevo: Berechnung siehe Lastenheft "End-to-End Kommunikationsabsicherung" Endwerte siehe Begleitdokument "S-PDU Kennungsfolgen"
          signal VDSO_05_BZ_XIX_VDSO_05_XIX_HCP5_CANFD01: start 8, 4 bit, little-endian, data-type-policy=OVERRIDE, i-signal-type=PRIMITIVE, init-value=0, base-type=BT_VDSO_05_BZ, compu-method=CM_VDSO_05_BZ, data-constr=DC_VDSO_05_BZ, transfer-property=PENDING  # 4bit Botschaftszähler, wird mit jeder Sendebotschaft inkrementiert
          signal VDSO_Vx3d_XIX_VDSO_05_XIX_HCP5_CANFD01: start 12, 16 bit, little-endian, data-type-policy=OVERRIDE, i-signal-type=PRIMITIVE, init-value=65534, base-type=BT_VDSO_Vx3d, invalid-value=Invalid_VDSO_Vx3d_XIX_VDSO_05_XIX_HCP5_CANFD01:65535, compu-method=CM_VDSO_Vx3d, data-constr=DC_VDSO_Vx3d, unit=Unit_Unit_MeterPerSecon, transfer-property=PENDING, to BMC_HV(timeout 0.5 s)  # Geschwindigkeitssignal vom ABS/ASR oder ESP. Mittelwert der angetriebenen Räder. Bei MSR oder ABS Eingriffen wird die ABS-Referenzgeschwindigkeit für >= 200ms eingespiegelt (Zeit wird mit Aktiv-Flanke der Funktionsbits getriggert) MQB: Bei Frontantrieb und gesteuertem Allrad (Haldex) Mittelwert der Vorderräder.
          signal VDSO_Vx3dKmph_XIX_VDSO_05_XIX_HCP5_CANFD01: start 28, 16 bit, little-endian, data-type-policy=OVERRIDE, i-signal-type=PRIMITIVE, init-value=65534, base-type=BT_VDSO_Vx3dKmph, invalid-value=Invalid_VDSO_Vx3dKmph_XIX_VDSO_05_XIX_HCP5_CANFD01:65535, compu-method=CM_VDSO_Vx3dKmph, data-constr=DC_VDSO_Vx3dKmph, unit=Unit_Unit_KiloMeterPerHour, transfer-property=PENDING  # Longitudinal velocity estimated at the centre of rear axle. Estimation requires 3D IMU.
          signal VDSO_Vx3dDisp_XIX_VDSO_05_XIX_HCP5_CANFD01: start 44, 16 bit, little-endian, data-type-policy=OVERRIDE, i-signal-type=PRIMITIVE, init-value=65534, base-type=BT_VDSO_Vx3dDisp, invalid-value=Invalid_VDSO_Vx3dDisp_XIX_VDSO_05_XIX_HCP5_CANFD01:65535, compu-method=CM_VDSO_Vx3dDisp, data-constr=DC_VDSO_Vx3dDisp, unit=Unit_Unit_MeterPerSecon, transfer-property=PENDING  # VDSO_Vx3d incl. additional scaling to meet official regulations (Typ approval. NCAP eg)
          signal VDSO_BasTi200_NumClc_05_XIX_VDSO_05_XIX_HCP5_CANFD01: start 60, 4 bit, little-endian, data-type-policy=OVERRIDE, i-signal-type=PRIMITIVE, base-type=BT_VDSO_BasTi200_NumClc_05, compu-method=CM_VDSO_BasTi200_NumClc_05, data-constr=DC_VDSO_BasTi200_NumClc_05, unit=Unit_Unit_None, transfer-property=PENDING  # CalculationNumber of the VDSO 200 Runnable to enable PDU-TLT merge in receiver ECU
      frame WFS_02_XIX_HCP5_CANFD01: id 0x1A555446, to BMC_HV, frame-length=32, can-addressing-mode=EXTENDED, can-frame-rx-behavior=CAN-FD, can-frame-tx-behavior=CAN-FD
        pdu WFS_02_XIX_HCP5_CANFD01: length=28, minimum-delay=0.05, transmission-mode-true-timing={cyclic-timing={time-offset=0, time-period=0.4}, event-controlled-timing={number-of-repetitions=0, repetition-period=0}}, unused-bit-pattern=0
          signal WFS_02_CRC_XIX_WFS_02_XIX_HCP5_CANFD01: start 0, 8 bit, little-endian, data-type-policy=OVERRIDE, i-signal-type=PRIMITIVE, init-value=0, base-type=BT_WFS_02_CRC, compu-method=CM_WFS_02_CRC, data-constr=DC_WFS_02_CRC, transfer-property=PENDING  # Für MLB: Berechnung siehe Lastenheft "Kommunikationsabsicherung für FlexRay und CAN" Ab MQB und MLBevo: Berechnung siehe Lastenheft "End-to-End Kommunikationsabsicherung" Endwerte siehe Begleitdokument "S-PDU Kennungsfolgen"
          signal WFS_02_BZ_XIX_WFS_02_XIX_HCP5_CANFD01: start 8, 4 bit, little-endian, data-type-policy=OVERRIDE, i-signal-type=PRIMITIVE, init-value=0, base-type=BT_WFS_02_BZ, compu-method=CM_WFS_02_BZ, data-constr=DC_WFS_02_BZ, transfer-property=PENDING
          signal WFS_ID_Geb_autorisiert_in_Kl15_XIX_WFS_02_XIX_HCP5_CANFD01: start 12, 1 bit, little-endian, data-type-policy=OVERRIDE, i-signal-type=PRIMITIVE, init-value=0, base-type=BT_WFS_ID_Geb_autorisiert_in_Kl15, compu-method=CM_WFS_ID_Geb_autorisiert_in_Kl15, data-constr=DC_WFS_ID_Geb_autorisiert_in_Kl15, transfer-property=TRIGGERED-ON-CHANGE-WITHOUT-REPETITION  # Authorisierung des Schlüssels im aktiven Klemme-15-Zyklus
          signal WFS_ID_Geb_steckt_XIX_WFS_02_XIX_HCP5_CANFD01: start 13, 1 bit, little-endian, data-type-policy=OVERRIDE, i-signal-type=PRIMITIVE, init-value=0, base-type=BT_WFS_ID_Geb_steckt, compu-method=CM_WFS_ID_Geb_steckt, data-constr=DC_WFS_ID_Geb_steckt, transfer-property=TRIGGERED-ON-CHANGE-WITHOUT-REPETITION  # Schluessel (ID-Geber) im Zuendschloss
          signal WFS_ID_Geb_autorisiert_XIX_WFS_02_XIX_HCP5_CANFD01: start 14, 1 bit, little-endian, data-type-policy=OVERRIDE, i-signal-type=PRIMITIVE, init-value=0, base-type=BT_WFS_ID_Geb_autorisiert, compu-method=CM_WFS_ID_Geb_autorisiert, data-constr=DC_WFS_ID_Geb_autorisiert, transfer-property=TRIGGERED-ON-CHANGE-WITHOUT-REPETITION  # Authorisierung Schluessel (ID-Geber)
          signal WFS_Safe_XIX_WFS_02_XIX_HCP5_CANFD01: start 15, 1 bit, little-endian, data-type-policy=OVERRIDE, i-signal-type=PRIMITIVE, init-value=0, base-type=BT_WFS_Safe, compu-method=CM_WFS_Safe, data-constr=DC_WFS_Safe, transfer-property=TRIGGERED-ON-CHANGE-WITHOUT-REPETITION  # Status WFS
          signal VIN_1_XIX_WFS_02_XIX_HCP5_CANFD01: start 16, 8 bit, little-endian, data-type-policy=OVERRIDE, i-signal-type=PRIMITIVE, init-value=45, base-type=BT_VIN_1, compu-method=CM_VIN_1, data-constr=DC_VIN_1, transfer-property=PENDING, to BMC_HV(timeout 4 s)  # Initwert: 0x2D bei Fahrzeugen mit Wegfahrsperrengeneration >= 5 0x58 bei Fahrzeugen mit Wegfahrsperrengeneration < 5 (z.B. WFS-4)
          signal VIN_2_XIX_WFS_02_XIX_HCP5_CANFD01: start 24, 8 bit, little-endian, data-type-policy=OVERRIDE, i-signal-type=PRIMITIVE, init-value=45, base-type=BT_VIN_2, compu-method=CM_VIN_2, data-constr=DC_VIN_2, transfer-property=PENDING, to BMC_HV(timeout 4 s)  # Initwert: 0x2D bei Fahrzeugen mit Wegfahrsperrengeneration >= 5 0x58 bei Fahrzeugen mit Wegfahrsperrengeneration < 5 (z.B. WFS-4)
          signal VIN_3_XIX_WFS_02_XIX_HCP5_CANFD01: start 32, 8 bit, little-endian, data-type-policy=OVERRIDE, i-signal-type=PRIMITIVE, init-value=45, base-type=BT_VIN_3, compu-method=CM_VIN_3, data-constr=DC_VIN_3, transfer-property=PENDING, to BMC_HV(timeout 4 s)  # Initwert: 0x2D bei Fahrzeugen mit Wegfahrsperrengeneration >= 5 0x58 bei Fahrzeugen mit Wegfahrsperrengeneration < 5 (z.B. WFS-4)
          signal VIN_4_XIX_WFS_02_XIX_HCP5_CANFD01: start 40, 8 bit, little-endian, data-type-policy=OVERRIDE, i-signal-type=PRIMITIVE, init-value=45, base-type=BT_VIN_4, compu-method=CM_VIN_4, data-constr=DC_VIN_4, transfer-property=PENDING, to BMC_HV(timeout 4 s)  # Initwert: 0x2D bei Fahrzeugen mit Wegfahrsperrengeneration >= 5 0x58 bei Fahrzeugen mit Wegfahrsperrengeneration < 5 (z.B. WFS-4)
          signal VIN_5_XIX_WFS_02_XIX_HCP5_CANFD01: start 48, 8 bit, little-endian, data-type-policy=OVERRIDE, i-signal-type=PRIMITIVE, init-value=45, base-type=BT_VIN_5, compu-method=CM_VIN_5, data-constr=DC_VIN_5, transfer-property=PENDING, to BMC_HV(timeout 4 s)  # Initwert: 0x2D bei Fahrzeugen mit Wegfahrsperrengeneration >= 5 0x58 bei Fahrzeugen mit Wegfahrsperrengeneration < 5 (z.B. WFS-4)
          signal VIN_6_XIX_WFS_02_XIX_HCP5_CANFD01: start 56, 8 bit, little-endian, data-type-policy=OVERRIDE, i-signal-type=PRIMITIVE, init-value=45, base-type=BT_VIN_6, compu-method=CM_VIN_6, data-constr=DC_VIN_6, transfer-property=PENDING, to BMC_HV(timeout 4 s)  # Initwert: 0x2D bei Fahrzeugen mit Wegfahrsperrengeneration >= 5 0x58 bei Fahrzeugen mit Wegfahrsperrengeneration < 5 (z.B. WFS-4)
          signal VIN_7_XIX_WFS_02_XIX_HCP5_CANFD01: start 64, 8 bit, little-endian, data-type-policy=OVERRIDE, i-signal-type=PRIMITIVE, init-value=45, base-type=BT_VIN_7, compu-method=CM_VIN_7, data-constr=DC_VIN_7, transfer-property=PENDING, to BMC_HV(timeout 4 s)  # Initwert: 0x2D bei Fahrzeugen mit Wegfahrsperrengeneration >= 5 0x58 bei Fahrzeugen mit Wegfahrsperrengeneration < 5 (z.B. WFS-4)
          signal VIN_8_XIX_WFS_02_XIX_HCP5_CANFD01: start 72, 8 bit, little-endian, data-type-policy=OVERRIDE, i-signal-type=PRIMITIVE, init-value=45, base-type=BT_VIN_8, compu-method=CM_VIN_8, data-constr=DC_VIN_8, transfer-property=PENDING, to BMC_HV(timeout 4 s)  # Initwert: 0x2D bei Fahrzeugen mit Wegfahrsperrengeneration >= 5 0x58 bei Fahrzeugen mit Wegfahrsperrengeneration < 5 (z.B. WFS-4)
          signal VIN_9_XIX_WFS_02_XIX_HCP5_CANFD01: start 80, 8 bit, little-endian, data-type-policy=OVERRIDE, i-signal-type=PRIMITIVE, init-value=45, base-type=BT_VIN_9, compu-method=CM_VIN_9, data-constr=DC_VIN_9, transfer-property=PENDING, to BMC_HV(timeout 4 s)  # Initwert: 0x2D bei Fahrzeugen mit Wegfahrsperrengeneration >= 5 0x58 bei Fahrzeugen mit Wegfahrsperrengeneration < 5 (z.B. WFS-4)
          signal VIN_10_XIX_WFS_02_XIX_HCP5_CANFD01: start 88, 8 bit, little-endian, data-type-policy=OVERRIDE, i-signal-type=PRIMITIVE, init-value=45, base-type=BT_VIN_10, compu-method=CM_VIN_10, data-constr=DC_VIN_10, transfer-property=PENDING, to BMC_HV(timeout 4 s)  # Initwert: 0x2D bei Fahrzeugen mit Wegfahrsperrengeneration >= 5 0x58 bei Fahrzeugen mit Wegfahrsperrengeneration < 5 (z.B. WFS-4)
          signal VIN_11_XIX_WFS_02_XIX_HCP5_CANFD01: start 96, 8 bit, little-endian, data-type-policy=OVERRIDE, i-signal-type=PRIMITIVE, init-value=45, base-type=BT_VIN_11, compu-method=CM_VIN_11, data-constr=DC_VIN_11, transfer-property=PENDING, to BMC_HV(timeout 4 s)  # Initwert: 0x2D bei Fahrzeugen mit Wegfahrsperrengeneration >= 5 0x58 bei Fahrzeugen mit Wegfahrsperrengeneration < 5 (z.B. WFS-4)
          signal VIN_12_XIX_WFS_02_XIX_HCP5_CANFD01: start 104, 8 bit, little-endian, data-type-policy=OVERRIDE, i-signal-type=PRIMITIVE, init-value=45, base-type=BT_VIN_12, compu-method=CM_VIN_12, data-constr=DC_VIN_12, transfer-property=PENDING, to BMC_HV(timeout 4 s)  # Initwert: 0x2D bei Fahrzeugen mit Wegfahrsperrengeneration >= 5 0x58 bei Fahrzeugen mit Wegfahrsperrengeneration < 5 (z.B. WFS-4)
          signal VIN_13_XIX_WFS_02_XIX_HCP5_CANFD01: start 112, 8 bit, little-endian, data-type-policy=OVERRIDE, i-signal-type=PRIMITIVE, init-value=45, base-type=BT_VIN_13, compu-method=CM_VIN_13, data-constr=DC_VIN_13, transfer-property=PENDING, to BMC_HV(timeout 4 s)  # Initwert: 0x2D bei Fahrzeugen mit Wegfahrsperrengeneration >= 5 0x58 bei Fahrzeugen mit Wegfahrsperrengeneration < 5 (z.B. WFS-4)
          signal VIN_14_XIX_WFS_02_XIX_HCP5_CANFD01: start 120, 8 bit, little-endian, data-type-policy=OVERRIDE, i-signal-type=PRIMITIVE, init-value=45, base-type=BT_VIN_14, compu-method=CM_VIN_14, data-constr=DC_VIN_14, transfer-property=PENDING, to BMC_HV(timeout 4 s)  # Initwert: 0x2D bei Fahrzeugen mit Wegfahrsperrengeneration >= 5 0x58 bei Fahrzeugen mit Wegfahrsperrengeneration < 5 (z.B. WFS-4)
          signal VIN_15_XIX_WFS_02_XIX_HCP5_CANFD01: start 128, 8 bit, little-endian, data-type-policy=OVERRIDE, i-signal-type=PRIMITIVE, init-value=45, base-type=BT_VIN_15, compu-method=CM_VIN_15, data-constr=DC_VIN_15, transfer-property=PENDING, to BMC_HV(timeout 4 s)  # Initwert: 0x2D bei Fahrzeugen mit Wegfahrsperrengeneration >= 5 0x58 bei Fahrzeugen mit Wegfahrsperrengeneration < 5 (z.B. WFS-4)
          signal VIN_16_XIX_WFS_02_XIX_HCP5_CANFD01: start 136, 8 bit, little-endian, data-type-policy=OVERRIDE, i-signal-type=PRIMITIVE, init-value=45, base-type=BT_VIN_16, compu-method=CM_VIN_16, data-constr=DC_VIN_16, transfer-property=PENDING, to BMC_HV(timeout 4 s)  # Initwert: 0x2D bei Fahrzeugen mit Wegfahrsperrengeneration >= 5 0x58 bei Fahrzeugen mit Wegfahrsperrengeneration < 5 (z.B. WFS-4)
          signal VIN_17_XIX_WFS_02_XIX_HCP5_CANFD01: start 144, 8 bit, little-endian, data-type-policy=OVERRIDE, i-signal-type=PRIMITIVE, init-value=45, base-type=BT_VIN_17, compu-method=CM_VIN_17, data-constr=DC_VIN_17, transfer-property=PENDING, to BMC_HV(timeout 4 s)  # Initwert: 0x2D bei Fahrzeugen mit Wegfahrsperrengeneration >= 5 0x58 bei Fahrzeugen mit Wegfahrsperrengeneration < 5 (z.B. WFS-4)
          signal WFS_Schluessel_Soll_XIX_WFS_02_XIX_HCP5_CANFD01: start 152, 4 bit, little-endian, data-type-policy=OVERRIDE, i-signal-type=PRIMITIVE, init-value=0, base-type=BT_WFS_Schluessel_Soll, compu-method=CM_WFS_Schluessel_Soll, data-constr=DC_WFS_Schluessel_Soll, unit=Unit_Unit_None, transfer-property=TRIGGERED-ON-CHANGE-WITHOUT-REPETITION  # Sollwert der zu lernenden Schluessel
          signal WFS_Schluessel_Ist_XIX_WFS_02_XIX_HCP5_CANFD01: start 156, 4 bit, little-endian, data-type-policy=OVERRIDE, i-signal-type=PRIMITIVE, init-value=0, base-type=BT_WFS_Schluessel_Ist, compu-method=CM_WFS_Schluessel_Ist, data-constr=DC_WFS_Schluessel_Ist, unit=Unit_Unit_None, transfer-property=TRIGGERED-ON-CHANGE-WITHOUT-REPETITION  # Istwert der gelernten Schluessel
          signal WFS_Schluessel_Fahrberecht_XIX_WFS_02_XIX_HCP5_CANFD01: start 160, 4 bit, little-endian, data-type-policy=OVERRIDE, i-signal-type=PRIMITIVE, init-value=0, base-type=BT_WFS_Schluessel_Fahrberecht, compu-method=CM_WFS_Schluessel_Fahrberecht, data-constr=DC_WFS_Schluessel_Fahrberecht, transfer-property=TRIGGERED-ON-CHANGE-WITHOUT-REPETITION  # Schlüsselnummer Fahrberechtigung 0 = ungueltig, xxxx = Schluessel-Nr.
          signal WFS_Fahrerhinweise_XIX_WFS_02_XIX_HCP5_CANFD01: start 164, 2 bit, little-endian, data-type-policy=OVERRIDE, i-signal-type=PRIMITIVE, init-value=0, base-type=BT_WFS_Fahrerhinweise, compu-method=CM_WFS_Fahrerhinweise, data-constr=DC_WFS_Fahrerhinweise, transfer-property=PENDING  # Meldungen, Fahrer- und Warnhinweise der Wegfahrsperre
          signal WFS_Parken_Status_XIX_WFS_02_XIX_HCP5_CANFD01: start 166, 2 bit, little-endian, data-type-policy=OVERRIDE, i-signal-type=PRIMITIVE, init-value=0, base-type=BT_WFS_Parken_Status, compu-method=CM_WFS_Parken_Status, data-constr=DC_WFS_Parken_Status, transfer-property=TRIGGERED-ON-CHANGE-WITHOUT-REPETITION  # Schnittstelle zwischen WFS und ZFAS für das Pilotierte Parken um in Richtung ZFAS den Status der WFS im BCM2 zu kommunizieren
          signal WFS_Klemmenfreigabe_XIX_WFS_02_XIX_HCP5_CANFD01: start 169, 1 bit, little-endian, data-type-policy=OVERRIDE, i-signal-type=PRIMITIVE, init-value=0, base-type=BT_WFS_Klemmenfreigabe, compu-method=CM_WFS_Klemmenfreigabe, data-constr=DC_WFS_Klemmenfreigabe, transfer-property=TRIGGERED-ON-CHANGE-WITHOUT-REPETITION  # Freigabe von der WFS zum Einschalten der Klemme 15 und Klemme S
          signal WFS_ELV_authorisiert_XIX_WFS_02_XIX_HCP5_CANFD01: start 170, 1 bit, little-endian, data-type-policy=OVERRIDE, i-signal-type=PRIMITIVE, init-value=0, base-type=BT_WFS_ELV_authorisiert, compu-method=CM_WFS_ELV_authorisiert, data-constr=DC_WFS_ELV_authorisiert, transfer-property=PENDING  # Authorisierung der elektrischen Lenkungsverriegelung an der WFS
          signal WFS_Betrieb_Lesespule_XIX_WFS_02_XIX_HCP5_CANFD01: start 171, 1 bit, little-endian, data-type-policy=OVERRIDE, i-signal-type=PRIMITIVE, init-value=0, base-type=BT_WFS_Betrieb_Lesespule, compu-method=CM_WFS_Betrieb_Lesespule, data-constr=DC_WFS_Betrieb_Lesespule, transfer-property=PENDING  # Schlüsselkommunikation über die Lesespule
          signal WFS_LF_Aktiv_XIX_WFS_02_XIX_HCP5_CANFD01: start 172, 1 bit, little-endian, data-type-policy=OVERRIDE, i-signal-type=PRIMITIVE, init-value=0, base-type=BT_WFS_LF_Aktiv, compu-method=CM_WFS_LF_Aktiv, data-constr=DC_WFS_LF_Aktiv, transfer-property=PENDING  # LF Schluesselkommunikation
          signal WFS_LZ_02_XIX_WFS_02_XIX_HCP5_CANFD01: start 173, 4 bit, little-endian, data-type-policy=OVERRIDE, i-signal-type=PRIMITIVE, init-value=0, base-type=BT_WFS_LZ_02, invalid-value=Invalid_WFS_LZ_02_XIX_WFS_02_XIX_HCP5_CANFD01:9, compu-method=CM_WFS_LZ_02, data-constr=DC_WFS_LZ_02, transfer-property=TRIGGERED-ON-CHANGE-WITHOUT-REPETITION  # Inbetriebnahme/Anlernzustand der Wegfahrsperre
          signal IMMO_Display_XIX_WFS_02_XIX_HCP5_CANFD01: start 177, 2 bit, little-endian, data-type-policy=OVERRIDE, i-signal-type=PRIMITIVE, init-value=0, base-type=BT_IMMO_Display, invalid-value=Invalid_IMMO_Display_XIX_WFS_02_XIX_HCP5_CANFD01:2, compu-method=CM_IMMO_Display, data-constr=DC_IMMO_Display, transfer-property=TRIGGERED-ON-CHANGE-WITHOUT-REPETITION  # Signal zur Steuerung der WFS-Anzeige im Kombi (Service)
          signal IMMO_ClampPermStatus_XIX_WFS_02_XIX_HCP5_CANFD01: start 179, 4 bit, little-endian, data-type-policy=OVERRIDE, i-signal-type=PRIMITIVE, init-value=15, base-type=BT_IMMO_ClampPermStatus, compu-method=CM_IMMO_ClampPermStatus, data-constr=DC_IMMO_ClampPermStatus, transfer-property=TRIGGERED-ON-CHANGE-WITHOUT-REPETITION  # Antwortsignal der WFS an die Klemmensteuerung zur Klemmenfreigabe
      frame XCP_BJB_CRO_01_XIX_HCP5_CANFD01: id 0x18FCD000, to BMC_HV, frame-length=8, can-addressing-mode=EXTENDED, can-frame-rx-behavior=CAN-FD, can-frame-tx-behavior=CAN-FD
        user defined pdu CDD_XCP_BJB_CRO_01_XIX_HCP5_CANFD01: length=8, cdd-type=EID
      frame XCP_BJB_DTO_01_XIX_HCP5_CANFD01: id 0x18FCD001, from BMC_HV, frame-length=8, can-addressing-mode=EXTENDED, can-frame-rx-behavior=CAN-FD, can-frame-tx-behavior=CAN-FD
        user defined pdu CDD_XCP_BJB_DTO_01_XIX_HCP5_CANFD01: length=8, cdd-type=EID
      frame XCP_Hybrid_01_CRO_01_FD_XIX_HCP5_CANFD01: id 0x1BFC6700, to BMC_HV, frame-length=64, can-addressing-mode=EXTENDED, can-frame-rx-behavior=CAN-FD, can-frame-tx-behavior=CAN-FD
        general purpose i pdu XCP_Hybrid_01_CRO_01_FD_XIX_HCP5_CANFD01: category=XCP, length=64
      frame XCP_Hybrid_01_DTO_01_FD_XIX_HCP5_CANFD01: id 0x1BFC6701, from BMC_HV, frame-length=64, can-addressing-mode=EXTENDED, can-frame-rx-behavior=CAN-FD, can-frame-tx-behavior=CAN-FD
        general purpose i pdu XCP_Hybrid_01_DTO_01_FD_XIX_HCP5_CANFD01: category=XCP, length=64
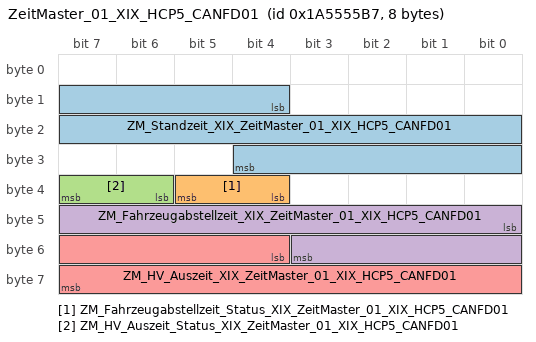
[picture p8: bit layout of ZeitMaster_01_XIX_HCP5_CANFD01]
      frame ZeitMaster_01_XIX_HCP5_CANFD01: id 0x1A5555B7, to BMC_HV, frame-length=8, can-addressing-mode=EXTENDED, can-frame-rx-behavior=CAN-FD, can-frame-tx-behavior=CAN-FD
        pdu ZeitMaster_01_XIX_HCP5_CANFD01: length=8, transmission-mode-true-timing=cyclic-timing={time-offset=0, time-period=1}, unused-bit-pattern=0
          signal ZM_Standzeit_XIX_ZeitMaster_01_XIX_HCP5_CANFD01: start 12, 17 bit, little-endian, data-type-policy=OVERRIDE, i-signal-type=PRIMITIVE, init-value=131070, base-type=BT_ZM_Standzeit, invalid-value=Invalid_ZM_Standzeit_XIX_ZeitMaster_01_XIX_HCP5_CANFD01:131071, compu-method=CM_ZM_Standzeit, data-constr=DC_ZM_Standzeit, unit=Unit_Unit_Secon, transfer-property=PENDING  # Standzeit des Fahrzeugs
          signal ZM_Fahrzeugabstellzeit_Status_XIX_ZeitMaster_01_XIX_HCP5_CANFD01: start 36, 2 bit, little-endian, data-type-policy=OVERRIDE, i-signal-type=PRIMITIVE, init-value=0, base-type=BT_ZM_Fahrzeugabstellzeit_Status, compu-method=CM_ZM_Fahrzeugabstellzeit_Status, data-constr=DC_ZM_Fahrzeugabstellzeit_Status, transfer-property=PENDING  # Status Fahrzeugabstellzeit
          signal ZM_HV_Auszeit_Status_XIX_ZeitMaster_01_XIX_HCP5_CANFD01: start 38, 2 bit, little-endian, data-type-policy=OVERRIDE, i-signal-type=PRIMITIVE, init-value=0, base-type=BT_ZM_HV_Auszeit_Status, compu-method=CM_ZM_HV_Auszeit_Status, data-constr=DC_ZM_HV_Auszeit_Status, transfer-property=PENDING, to BMC_HV(timeout 5 s)  # Status HV-Auszeit
          signal ZM_Fahrzeugabstellzeit_XIX_ZeitMaster_01_XIX_HCP5_CANFD01: start 40, 12 bit, little-endian, data-type-policy=OVERRIDE, i-signal-type=PRIMITIVE, init-value=4094, base-type=BT_ZM_Fahrzeugabstellzeit, invalid-value=Invalid_ZM_Fahrzeugabstellzeit_XIX_ZeitMaster_01_XIX_HCP5_CANFD01:4095, compu-method=CM_ZM_Fahrzeugabstellzeit, data-constr=DC_ZM_Fahrzeugabstellzeit, unit=Unit_Unit_Minut, transfer-property=PENDING  # Zeit seit letzter Fahrbereitschaft
          signal ZM_HV_Auszeit_XIX_ZeitMaster_01_XIX_HCP5_CANFD01: start 52, 12 bit, little-endian, data-type-policy=OVERRIDE, i-signal-type=PRIMITIVE, init-value=4094, base-type=BT_ZM_HV_Auszeit, invalid-value=Invalid_ZM_HV_Auszeit_XIX_ZeitMaster_01_XIX_HCP5_CANFD01:4095, compu-method=CM_ZM_HV_Auszeit, data-constr=DC_ZM_HV_Auszeit, unit=Unit_Unit_Minut, transfer-property=PENDING, to BMC_HV(timeout 5 s)  # Zeit seit letzter Hochvoltaktivität
      frame Zeitmaster_05_XIX_HCP5_CANFD01: id 0x1A5555AA, to BMC_HV, frame-length=8, can-addressing-mode=EXTENDED, can-frame-rx-behavior=CAN-FD, can-frame-tx-behavior=CAN-FD
        pdu Zeitmaster_05_XIX_HCP5_CANFD01: length=8, transmission-mode-true-timing=cyclic-timing={time-offset=0, time-period=0.5}, unused-bit-pattern=0
          signal ZM_HV_Auszeit_HiRes_XIX_Zeitmaster_05_XIX_HCP5_CANFD01: start 32, 16 bit, little-endian, data-type-policy=OVERRIDE, i-signal-type=PRIMITIVE, init-value=65534, base-type=BT_ZM_HV_Auszeit_HiRes, invalid-value=Invalid_ZM_HV_Auszeit_HiRes_XIX_Zeitmaster_05_XIX_HCP5_CANFD01:65535, compu-method=CM_ZM_HV_Auszeit_HiRes, data-constr=DC_ZM_HV_Auszeit_HiRes, unit=Unit_Unit_Minut, transfer-property=PENDING, to BMC_HV(timeout 5 s)  # Zeit seit letzter Hochvoltaktivität (Erweiterter Wertebereich)
          signal ZM_Fahrzeugabstellzeit_HiRes_XIX_Zeitmaster_05_XIX_HCP5_CANFD01: start 48, 16 bit, little-endian, data-type-policy=OVERRIDE, i-signal-type=PRIMITIVE, init-value=65534, base-type=BT_ZM_Fahrzeugabstellzeit_HiRes, invalid-value=Invalid_ZM_Fahrzeugabstellzeit_HiRes_XIX_Zeitmaster_05_XIX_HCP5_CANFD01:65535, compu-method=CM_ZM_Fahrzeugabstellzeit_HiRes, data-constr=DC_ZM_Fahrzeugabstellzeit_HiRes, unit=Unit_Unit_Secon, transfer-property=PENDING  # Zeit seit letzter Fahrbereitschaft (Erweiterter Wertebereich)
      pdu triggering PT_BMC_HV_01_E2E: pdu=BMC_HV_01_XIX_HCP5_CANFD01_E2E, from BMC_HV
      pdu triggering PT_BMC_HV_02_E2E: pdu=BMC_HV_02_XIX_HCP5_CANFD01_E2E, from BMC_HV
      pdu triggering PT_BMC_HV_{06..09}: pdu=BMC_HV_{06..09}_XIX_HCP5_CANFD01, from BMC_HV
      pdu triggering PT_BMC_HV_14: pdu=BMC_HV_14_XIX_HCP5_CANFD01, from BMC_HV
      pdu triggering PT_HCP5_CANFD01_XIX_TPCHType_CANFD_DAAP_XIX_0x1C403F7B_XIX_0x1C423F7B_XIX_Physical: pdu=CDD_HCP5_CANFD01_XIX_TPCHType_CANFD_DAAP_XIX_0x1C403F7B_XIX_0x1C423F7B_XIX_Physical, to BMC_HV
      pdu triggering PT_HCP5_CANFD01_XIX_TPCHType_CANFD_DAAP_XIX_0x1C413FDD_XIX_Functional: pdu=CDD_HCP5_CANFD01_XIX_TPCHType_CANFD_DAAP_XIX_0x1C413FDD_XIX_Functional, to BMC_HV
      pdu triggering PT_HCP5_CANFD01_XIX_TPCHType_CANFD_DAAP_XIX_0x1C423F7B_XIX_0x1C403F7B_XIX_Physical: pdu=CDD_HCP5_CANFD01_XIX_TPCHType_CANFD_DAAP_XIX_0x1C423F7B_XIX_0x1C403F7B_XIX_Physical, from BMC_HV
      pdu triggering PT_HCP5_CANFD01_XIX_TPCHType_CANFD_ISO_Diagnose_XIX_0x1C40007B_XIX_0x1C42007B_XIX_Physical: pdu=DCM_HCP5_CANFD01_XIX_TPCHType_CANFD_ISO_Diagnose_XIX_0x1C40007B_XIX_0x1C42007B_XIX_Physical, to BMC_HV
      pdu triggering PT_HCP5_CANFD01_XIX_TPCHType_CANFD_ISO_Diagnose_XIX_0x1C410000_XIX_Functional: pdu=DCM_HCP5_CANFD01_XIX_TPCHType_CANFD_ISO_Diagnose_XIX_0x1C410000_XIX_Functional, to BMC_HV
      pdu triggering PT_HCP5_CANFD01_XIX_TPCHType_CANFD_ISO_Diagnose_XIX_0x1C42007B_XIX_0x1C40007B_XIX_Physical: pdu=DCM_HCP5_CANFD01_XIX_TPCHType_CANFD_ISO_Diagnose_XIX_0x1C42007B_XIX_0x1C40007B_XIX_Physical, from BMC_HV
      pdu triggering PT_HCP5_CANFD01_XIX_TPCHType_CANFD_OBDC_Diagnose_XIX_0x1C40027B_XIX_0x1C42027B_XIX_Physical: pdu=DCM_HCP5_CANFD01_XIX_TPCHType_CANFD_OBDC_Diagnose_XIX_0x1C40027B_XIX_0x1C42027B_XIX_Physical, to BMC_HV
      pdu triggering PT_HCP5_CANFD01_XIX_TPCHType_CANFD_OBDC_Diagnose_XIX_0x1C410200_XIX_Functional: pdu=DCM_HCP5_CANFD01_XIX_TPCHType_CANFD_OBDC_Diagnose_XIX_0x1C410200_XIX_Functional, to BMC_HV
      pdu triggering PT_HCP5_CANFD01_XIX_TPCHType_CANFD_OBDC_Diagnose_XIX_0x1C42027B_XIX_0x1C40027B_XIX_Physical: pdu=DCM_HCP5_CANFD01_XIX_TPCHType_CANFD_OBDC_Diagnose_XIX_0x1C42027B_XIX_0x1C40027B_XIX_Physical, from BMC_HV
      pdu triggering PT_HCP5_CANFD01_XIX_TPCHType_CANHS_Flash_DIA_XIX_0x17FC16D0_XIX_0x17FE16D0_XIX_Physical: pdu=DCM_HCP5_CANFD01_XIX_TPCHType_CANHS_Flash_DIA_XIX_0x17FC16D0_XIX_0x17FE16D0_XIX_Physical, to BMC_HV
      pdu triggering PT_HCP5_CANFD01_XIX_TPCHType_CANHS_Flash_DIA_XIX_0x17FC17B1_XIX_0x17FE17B1_XIX_Physical: pdu=DCM_HCP5_CANFD01_XIX_TPCHType_CANHS_Flash_DIA_XIX_0x17FC17B1_XIX_0x17FE17B1_XIX_Physical, to BMC_HV
      pdu triggering PT_HCP5_CANFD01_XIX_TPCHType_CANHS_Flash_DIA_XIX_0x17FC17B2_XIX_0x17FE17B2_XIX_Physical: pdu=DCM_HCP5_CANFD01_XIX_TPCHType_CANHS_Flash_DIA_XIX_0x17FC17B2_XIX_0x17FE17B2_XIX_Physical, to BMC_HV
      pdu triggering PT_HCP5_CANFD01_XIX_TPCHType_CANHS_Flash_DIA_XIX_0x17FE16D0_XIX_0x17FC16D0_XIX_Physical: pdu=DCM_HCP5_CANFD01_XIX_TPCHType_CANHS_Flash_DIA_XIX_0x17FE16D0_XIX_0x17FC16D0_XIX_Physical, from BMC_HV
      pdu triggering PT_HCP5_CANFD01_XIX_TPCHType_CANHS_Flash_DIA_XIX_0x17FE17B1_XIX_0x17FC17B1_XIX_Physical: pdu=DCM_HCP5_CANFD01_XIX_TPCHType_CANHS_Flash_DIA_XIX_0x17FE17B1_XIX_0x17FC17B1_XIX_Physical, from BMC_HV
      pdu triggering PT_HCP5_CANFD01_XIX_TPCHType_CANHS_Flash_DIA_XIX_0x17FE17B2_XIX_0x17FC17B2_XIX_Physical: pdu=DCM_HCP5_CANFD01_XIX_TPCHType_CANHS_Flash_DIA_XIX_0x17FE17B2_XIX_0x17FC17B2_XIX_Physical, from BMC_HV
      pdu triggering PT_HCP5_CANFD01_XIX_TPCHType_CANHS_ISO_Diagnose_XIX_0x17FC007B_XIX_0x17FE007B_XIX_Physical: pdu=DCM_HCP5_CANFD01_XIX_TPCHType_CANHS_ISO_Diagnose_XIX_0x17FC007B_XIX_0x17FE007B_XIX_Physical, to BMC_HV
      pdu triggering PT_HCP5_CANFD01_XIX_TPCHType_CANHS_ISO_Diagnose_XIX_0x17FE007B_XIX_0x17FC007B_XIX_Physical: pdu=DCM_HCP5_CANFD01_XIX_TPCHType_CANHS_ISO_Diagnose_XIX_0x17FE007B_XIX_0x17FC007B_XIX_Physical, from BMC_HV
      pdu triggering PT_HCP5_CANFD01_XIX_TPCHType_CANHS_ISO_Diagnose_XIX_0x700_XIX_Functional: pdu=DCM_HCP5_CANFD01_XIX_TPCHType_CANHS_ISO_Diagnose_XIX_0x700_XIX_Functional, to BMC_HV
      pdu triggering PT_HCP5_CANFD01_XIX_TPCHType_CANHS_OBDC_SSN_Diagnose_XIX_0x17FC70D0_XIX_0x17FE70D0_XIX_Physical: pdu=DCM_HCP5_CANFD01_XIX_TPCHType_CANHS_OBDC_SSN_Diagnose_XIX_0x17FC70D0_XIX_0x17FE70D0_XIX_Physical, to BMC_HV
      pdu triggering PT_HCP5_CANFD01_XIX_TPCHType_CANHS_OBDC_SSN_Diagnose_XIX_0x17FC71B1_XIX_0x17FE71B1_XIX_Physical: pdu=DCM_HCP5_CANFD01_XIX_TPCHType_CANHS_OBDC_SSN_Diagnose_XIX_0x17FC71B1_XIX_0x17FE71B1_XIX_Physical, to BMC_HV
      pdu triggering PT_HCP5_CANFD01_XIX_TPCHType_CANHS_OBDC_SSN_Diagnose_XIX_0x17FC71B2_XIX_0x17FE71B2_XIX_Physical: pdu=DCM_HCP5_CANFD01_XIX_TPCHType_CANHS_OBDC_SSN_Diagnose_XIX_0x17FC71B2_XIX_0x17FE71B2_XIX_Physical, to BMC_HV
      pdu triggering PT_HCP5_CANFD01_XIX_TPCHType_CANHS_OBDC_SSN_Diagnose_XIX_0x17FE70D0_XIX_0x17FC70D0_XIX_Physical: pdu=DCM_HCP5_CANFD01_XIX_TPCHType_CANHS_OBDC_SSN_Diagnose_XIX_0x17FE70D0_XIX_0x17FC70D0_XIX_Physical, from BMC_HV
      pdu triggering PT_HCP5_CANFD01_XIX_TPCHType_CANHS_OBDC_SSN_Diagnose_XIX_0x17FE71B1_XIX_0x17FC71B1_XIX_Physical: pdu=DCM_HCP5_CANFD01_XIX_TPCHType_CANHS_OBDC_SSN_Diagnose_XIX_0x17FE71B1_XIX_0x17FC71B1_XIX_Physical, from BMC_HV
      pdu triggering PT_HCP5_CANFD01_XIX_TPCHType_CANHS_OBDC_SSN_Diagnose_XIX_0x17FE71B2_XIX_0x17FC71B2_XIX_Physical: pdu=DCM_HCP5_CANFD01_XIX_TPCHType_CANHS_OBDC_SSN_Diagnose_XIX_0x17FE71B2_XIX_0x17FC71B2_XIX_Physical, from BMC_HV
      pdu triggering PT_HCP5_CANFD01_XIX_TPCHType_CANHS_OBDx_XIX_0x18DA05F1_XIX_0x18DAF105_XIX_Physical: pdu=DCM_HCP5_CANFD01_XIX_TPCHType_CANHS_OBDx_XIX_0x18DA05F1_XIX_0x18DAF105_XIX_Physical, to BMC_HV
      pdu triggering PT_HCP5_CANFD01_XIX_TPCHType_CANHS_OBDx_XIX_0x18DAF105_XIX_0x18DA05F1_XIX_Physical: pdu=DCM_HCP5_CANFD01_XIX_TPCHType_CANHS_OBDx_XIX_0x18DAF105_XIX_0x18DA05F1_XIX_Physical, from BMC_HV
      pdu triggering PT_HCP5_CANFD01_XIX_TPCHType_CANHS_OBDx_XIX_0x18DB33F1_XIX_Functional: pdu=DCM_HCP5_CANFD01_XIX_TPCHType_CANHS_OBDx_XIX_0x18DB33F1_XIX_Functional, to BMC_HV
      pdu triggering PT_HVK_03_E2E: pdu=HVK_03_XIX_HCP5_CANFD01_E2E, to BMC_HV
      pdu triggering PT_OBD_HCP1: pdu=OBD_HCP1_XIX_HCP5_CANFD01, to BMC_HV
      pdu triggering PT_OBD_Hybrid_01: pdu=OBD_Hybrid_01_XIX_HCP5_CANFD01, from BMC_HV
      pdu triggering PT_SOK_Zeit_Hybrid_01_Resp_01: pdu=SOK_Zeit_Hybrid_01_Resp_01_XIX_HCP5_CANFD01, to BMC_HV
